VERSION ""

NS_ :

BS_:

BU_: HCM IPMA_ADAS PSCM ABS_ESC PCM ECM_HEV VDM CMR_DSMC SOBDMC_HPCM GWM _delete AWD_DLCM GENERIC TSTR

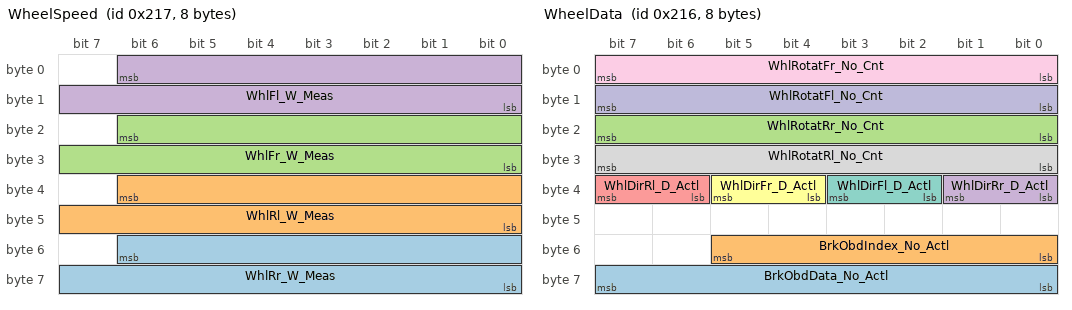
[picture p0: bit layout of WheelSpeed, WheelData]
BO_ 535 WheelSpeed: 8 ABS_ESC
 SG_ WhlRr_W_Meas : 54|15@0+ (0.01,0) [0|327.65] "rad/s"  VDM,SOBDMC_HPCM,IPMA_ADAS,GWM,ECM_HEV,PCM,PSCM,AWD_DLCM
 SG_ WhlRl_W_Meas : 38|15@0+ (0.01,0) [0|327.65] "rad/s"  VDM,SOBDMC_HPCM,IPMA_ADAS,GWM,ECM_HEV,PCM,PSCM,AWD_DLCM
 SG_ WhlFr_W_Meas : 22|15@0+ (0.01,0) [0|327.65] "rad/s"  VDM,SOBDMC_HPCM,IPMA_ADAS,GWM,ECM_HEV,PCM,PSCM,AWD_DLCM
 SG_ WhlFl_W_Meas : 6|15@0+ (0.01,0) [0|327.65] "rad/s"  VDM,SOBDMC_HPCM,IPMA_ADAS,GWM,ECM_HEV,PCM,PSCM,AWD_DLCM

BO_ 534 WheelData: 8 ABS_ESC
 SG_ BrkObdData_No_Actl : 63|8@0+ (1,0) [0|255] "unitless"  SOBDMC_HPCM,GWM
 SG_ BrkObdIndex_No_Actl : 53|6@0+ (1,0) [0|63] "unitless"  SOBDMC_HPCM,GWM
 SG_ WhlRotatRr_No_Cnt : 23|8@0+ (1,0) [0|255] "Unitless"  IPMA_ADAS,GWM
 SG_ WhlDirRr_D_Actl : 33|2@0+ (1,0) [0|3] "SED"  IPMA_ADAS,GWM,PCM,PSCM,ECM_HEV
 SG_ WhlDirRl_D_Actl : 39|2@0+ (1,0) [0|3] "SED"  IPMA_ADAS,GWM,PSCM,PCM,ECM_HEV
 SG_ WhlDirFr_D_Actl : 37|2@0+ (1,0) [0|3] "SED"  IPMA_ADAS,GWM,PCM,PSCM,ECM_HEV
 SG_ WhlDirFl_D_Actl : 35|2@0+ (1,0) [0|3] "SED"  IPMA_ADAS,GWM,PCM,PSCM,ECM_HEV
 SG_ WhlRotatRl_No_Cnt : 31|8@0+ (1,0) [0|255] "Unitless"  IPMA_ADAS,GWM
 SG_ WhlRotatFr_No_Cnt : 7|8@0+ (1,0) [0|255] "Unitless"  IPMA_ADAS,GWM
 SG_ WhlRotatFl_No_Cnt : 15|8@0+ (1,0) [0|255] "Unitless"  IPMA_ADAS,GWM

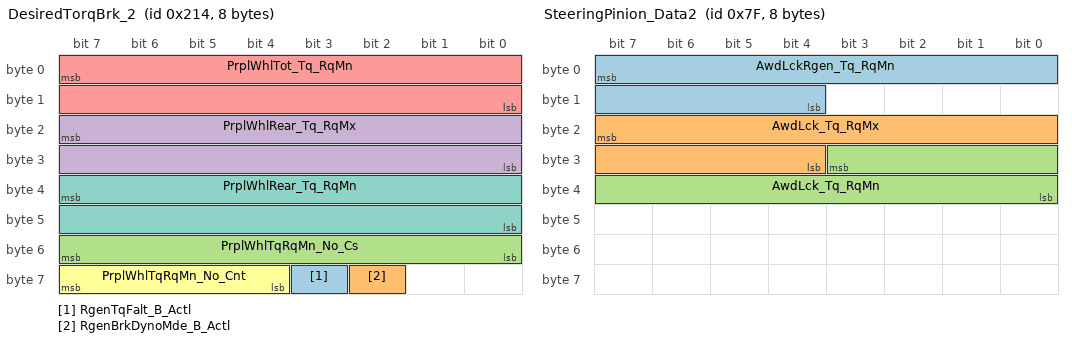
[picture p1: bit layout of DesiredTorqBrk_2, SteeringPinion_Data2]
BO_ 532 DesiredTorqBrk_2: 8 ABS_ESC
 SG_ RgenTqFalt_B_Actl : 59|1@0+ (1,0) [0|1] "SED"  SOBDMC_HPCM,GWM
 SG_ RgenBrkDynoMde_B_Actl : 58|1@0+ (1,0) [0|1] "SED"  ECM_HEV,SOBDMC_HPCM,GWM
 SG_ PrplWhlTqRqMn_No_Cs : 55|8@0+ (1,0) [0|255] "Unitless"  SOBDMC_HPCM,GWM,ECM_HEV,PCM
 SG_ PrplWhlRear_Tq_RqMx : 23|16@0+ (4,-131072) [-131072|131068] "Nm"  GWM
 SG_ PrplWhlTot_Tq_RqMn : 7|16@0+ (4,-131072) [-131072|131068] "Nm"  SOBDMC_HPCM,GWM,ECM_HEV,PCM
 SG_ PrplWhlTqRqMn_No_Cnt : 63|4@0+ (1,0) [0|15] "Unitless"  SOBDMC_HPCM,GWM,ECM_HEV,PCM
 SG_ PrplWhlRear_Tq_RqMn : 39|16@0+ (4,-131072) [-131072|131068] "Nm"  SOBDMC_HPCM,GWM

BO_ 531 DesiredTorqBrk: 8 ABS_ESC
 SG_ PrkBrkMsgTxt_D_Rq : 36|4@0+ (1,0) [0|15] "SED"  GWM
 SG_ VehStop_D_Stat : 28|2@0+ (1,0) [0|3] "SED"  IPMA_ADAS,GWM
 SG_ TracCtlPtActv_B_Actl : 31|1@0+ (1,0) [0|1] "SED"  SOBDMC_HPCM,IPMA_ADAS,ECM_HEV,PCM,VDM,AWD_DLCM,GWM
 SG_ VehicleStationary : 39|1@0+ (1,0) [0|1] "SED"  GWM,AWD_DLCM
 SG_ AbsActv_B_Actl : 45|1@0+ (1,0) [0|1] "SED"  SOBDMC_HPCM,IPMA_ADAS,ECM_HEV,PCM,PSCM,GWM,VDM,AWD_DLCM
 SG_ StabCtlBrkActv_B_Actl : 23|1@0+ (1,0) [0|1] "SED"  SOBDMC_HPCM,IPMA_ADAS,ECM_HEV,PCM,PSCM,VDM,GWM,AWD_DLCM
 SG_ CmbbBrkPrchg_B_Actl : 59|1@0+ (1,0) [0|1] "SED"  IPMA_ADAS,GWM
 SG_ CmbbBrkDecel_B_Actl : 58|1@0+ (1,0) [0|1] "SED"  IPMA_ADAS,GWM
 SG_ CmbbBaSensInc_B_Actl : 57|1@0+ (1,0) [0|1] "SED"  IPMA_ADAS,GWM
 SG_ AccBrkWarm_B_Actl : 63|1@0+ (1,0) [0|1] "SED"  IPMA_ADAS,GWM
 SG_ AccBrkTotTqMn_B_Actl : 62|1@0+ (1,0) [0|1] "SED"  IPMA_ADAS,GWM
 SG_ AccBrkPrchgActv_B_Actl : 61|1@0+ (1,0) [0|1] "SED"  IPMA_ADAS,GWM
 SG_ AccBrkDis_B_Actl : 44|1@0+ (1,0) [0|1] "SED"  IPMA_ADAS,GWM
 SG_ AccBrkDeny_B_Actl : 42|1@0+ (1,0) [0|1] "SED"  IPMA_ADAS,ECM_HEV,PCM,GWM
 SG_ AccBrkActv_B_Actl : 43|1@0+ (1,0) [0|1] "SED"  IPMA_ADAS,GWM
 SG_ PrplDrgCtlActv_B_Actl : 46|1@0+ (1,0) [0|1] "SED"  SOBDMC_HPCM,ECM_HEV,PCM,GWM
 SG_ PrplWhlTot_Tq_RqMx : 7|16@0+ (4,-131072) [-131072|131068] "Nm"  SOBDMC_HPCM,ECM_HEV,PCM,GWM,AWD_DLCM
 SG_ CmbbBrkDis_B_Actl : 56|1@0+ (1,0) [0|1] "SED"  IPMA_ADAS,PSCM,GWM
 SG_ CmbbDeny_B_ActlBrk : 60|1@0+ (1,0) [0|1] "SED"  SOBDMC_HPCM,IPMA_ADAS,PSCM,ECM_HEV,GENERIC,PCM,GWM
 SG_ CcDis_B_Cmd : 47|1@0+ (1,0) [0|1] "SED"  ECM_HEV,PCM,GWM
 SG_ VehLongOvrGnd_A_Est : 41|10@0+ (0.035,-17.9) [-17.9|17.835] "m/s^2"  SOBDMC_HPCM,IPMA_ADAS,GWM,VDM
 SG_ AccStopActv_B_ActlBrk : 22|1@0+ (1,0) [0|1] "SED"  IPMA_ADAS,ECM_HEV,PCM,GWM
 SG_ AccDis_B_ActlEpb : 32|1@0+ (1,0) [0|1] "SED"  IPMA_ADAS,GWM
 SG_ PrkBrkStatus : 26|3@0+ (1,0) [0|7] "SED"  SOBDMC_HPCM,IPMA_ADAS,ECM_HEV,PCM,GWM,AWD_DLCM
 SG_ PrkBrkYwLamp_D_Rq : 38|2@0+ (1,0) [0|3] "SED"  GWM
 SG_ PrkBrkRedLamp_D_Rq : 30|2@0+ (1,0) [0|3] "SED"  GWM

BO_ 127 SteeringPinion_Data2: 8 ABS_ESC
 SG_ AwdLckRgen_Tq_RqMn : 7|12@0+ (1,-4095) [-4095|0] "Nm"  SOBDMC_HPCM,GWM
 SG_ AwdLck_Tq_RqMx : 23|12@0+ (1,0) [0|4095] "Nm"  AWD_DLCM,ECM_HEV,PCM,SOBDMC_HPCM,GWM
 SG_ AwdLck_Tq_RqMn : 27|12@0+ (1,0) [0|4095] "Nm"  AWD_DLCM,ECM_HEV,PCM,SOBDMC_HPCM,GWM

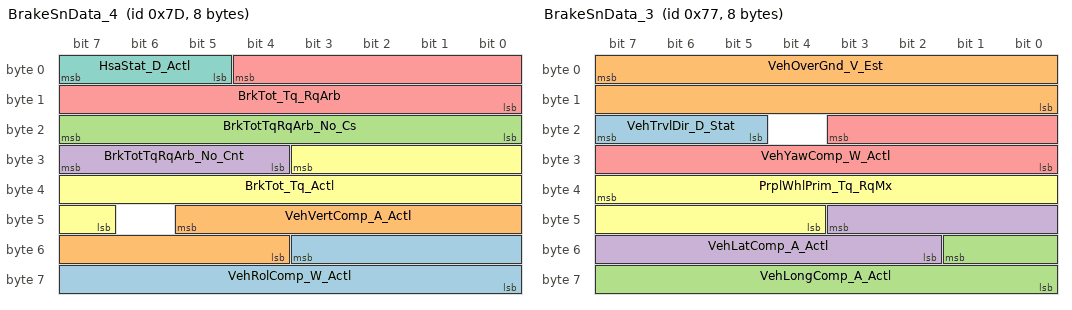
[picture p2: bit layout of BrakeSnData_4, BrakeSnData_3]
BO_ 125 BrakeSnData_4: 8 ABS_ESC
 SG_ VehRolComp_W_Actl : 51|12@0+ (0.03663,-75) [-75|74.92659] "degrees/sec"  GWM,VDM
 SG_ VehVertComp_A_Actl : 45|10@0+ (0.035,-17.9) [-17.9|17.835] "m/s^2"  GWM,VDM
 SG_ BrkTotTqRqArb_No_Cs : 23|8@0+ (1,0) [0|255] "Unitless"  SOBDMC_HPCM,ECM_HEV,PCM,GWM
 SG_ BrkTotTqRqArb_No_Cnt : 31|4@0+ (1,0) [0|15] "Unitless"  SOBDMC_HPCM,ECM_HEV,PCM,GWM
 SG_ BrkTot_Tq_RqArb : 4|13@0+ (4,0) [0|32756] "Nm"  SOBDMC_HPCM,HCM,IPMA_ADAS,ECM_HEV,PCM,VDM,GWM
 SG_ BrkTot_Tq_Actl : 27|13@0+ (4,0) [0|32756] "Nm"  SOBDMC_HPCM,ECM_HEV,PCM,PSCM,GWM
 SG_ HsaStat_D_Actl : 7|3@0+ (1,0) [0|7] "SED"  ECM_HEV,PCM,GWM

BO_ 119 BrakeSnData_3: 8 ABS_ESC
 SG_ VehTrvlDir_D_Stat : 23|3@0+ (1,0) [0|7] "SED"  GWM
 SG_ VehOverGnd_V_Est : 7|16@0+ (0.01,0) [0|655.33] "kph"  SOBDMC_HPCM,IPMA_ADAS,PSCM,GWM,VDM,AWD_DLCM
 SG_ VehLongComp_A_Actl : 49|10@0+ (0.035,-17.9) [-17.9|17.835] "m/s^2"  SOBDMC_HPCM,ECM_HEV,PCM,VDM,HCM,GWM,AWD_DLCM
 SG_ VehLatComp_A_Actl : 43|10@0+ (0.035,-17.9) [-17.9|17.835] "m/s^2"  SOBDMC_HPCM,ECM_HEV,PCM,PSCM,VDM,HCM,GWM,AWD_DLCM
 SG_ VehYawComp_W_Actl : 19|12@0+ (0.03663,-75) [-75|74.92659] "deg/s"  SOBDMC_HPCM,IPMA_ADAS,ECM_HEV,PCM,PSCM,VDM,GWM,AWD_DLCM
 SG_ PrplWhlPrim_Tq_RqMx : 39|12@0+ (8,0) [0|32760] "Nm"  SOBDMC_HPCM,GWM

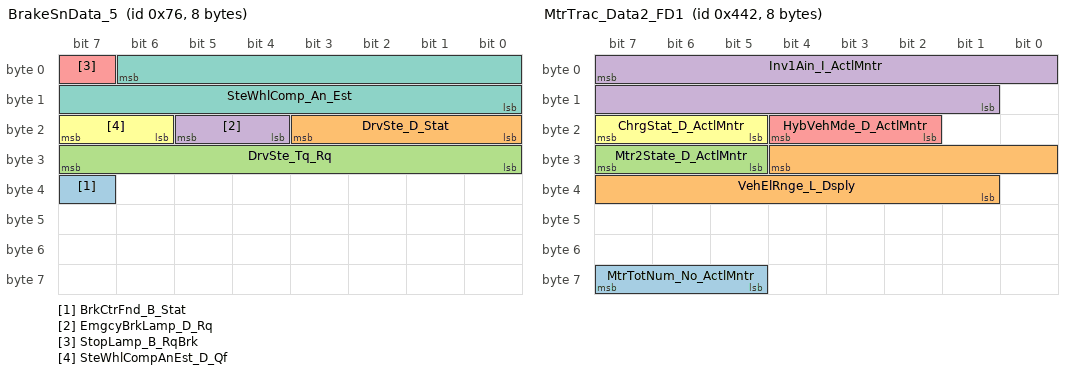
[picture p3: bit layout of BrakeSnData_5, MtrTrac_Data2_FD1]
BO_ 118 BrakeSnData_5: 8 ABS_ESC
 SG_ BrkCtrFnd_B_Stat : 39|1@0+ (1,0) [0|1] "SED"  GWM
 SG_ DrvSte_D_Stat : 19|4@0+ (1,0) [0|15] "SED"  GWM
 SG_ DrvSte_Tq_Rq : 31|8@0+ (0.0625,-8) [-8|7.8125] "Nm"  GWM
 SG_ EmgcyBrkLamp_D_Rq : 21|2@0+ (1,0) [0|3] "SED"  GWM
 SG_ StopLamp_B_RqBrk : 7|1@0+ (1,0) [0|1] "SED"  GWM
 SG_ SteWhlCompAnEst_D_Qf : 23|2@0+ (1,0) [0|3] "SED"  GWM
 SG_ SteWhlComp_An_Est : 6|15@0+ (0.1,-1600) [-1600|1676.7] "deg"  GWM

BO_ 73 Global_PATS_SubTarget: 8 ABS_ESC
 SG_ immoSubTarget1Data_T1 : 15|40@0+ (1,0) [0|1099511627775] "Encrypted"  ECM_HEV,SOBDMC_HPCM,GWM,PCM
 SG_ immoSubTarget1Cmd_T1 : 7|3@0+ (1,0) [0|7] "SED"  SOBDMC_HPCM,GWM,PCM

BO_ 1034 GGCC_Config_Mgmt_ID_1_FD1: 8 GWM
 SG_ VehicleGGCCData : 7|64@0+ (1,0) [0|1.84467E+019] "mixed"  SOBDMC_HPCM,HCM,VDM,IPMA_ADAS,ABS_ESC,ECM_HEV,PCM,PSCM,CMR_DSMC,AWD_DLCM

BO_ 561 TransGearData_2: 8 PCM
 SG_ TrnMsgTxt2_D_Rq : 39|3@0+ (1,0) [0|7] "SED"  GWM
 SG_ TrnMsgTxt_D_Rq : 23|4@0+ (1,0) [0|15] "SED"  GWM

BO_ 1090 MtrTrac_Data2_FD1: 8 SOBDMC_HPCM
 SG_ MtrTotNum_No_ActlMntr : 63|3@0+ (1,0) [0|7] "unitless"  GWM
 SG_ VehElRnge_L_Dsply : 28|12@0+ (0.1,0) [0|409.3] "kilometer"  GWM
 SG_ Mtr2State_D_ActlMntr : 31|3@0+ (1,0) [0|7] "SED"  GWM
 SG_ Inv1Ain_I_ActlMntr : 7|15@0+ (0.1,-1000) [-1000|2276.5] "ampere"  GWM
 SG_ HybVehMde_D_ActlMntr : 20|3@0+ (1,0) [0|7] "SED"  GWM
 SG_ ChrgStat_D_ActlMntr : 23|3@0+ (1,0) [0|7] "SED"  GWM

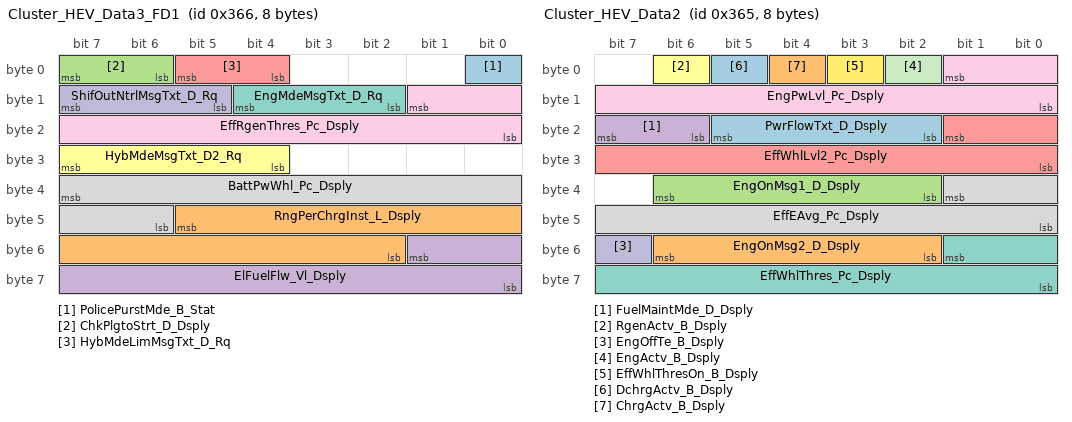
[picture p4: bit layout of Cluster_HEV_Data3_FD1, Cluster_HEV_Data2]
BO_ 870 Cluster_HEV_Data3_FD1: 8 SOBDMC_HPCM
 SG_ PolicePurstMde_B_Stat : 0|1@0+ (1,0) [0|1] "SED"  GWM
 SG_ RngPerChrgInst_L_Dsply : 45|12@0+ (0.1,0) [0|409.3] "km"  GWM
 SG_ ChkPlgtoStrt_D_Dsply : 7|2@0+ (1,0) [0|3] "SED"  GWM
 SG_ ElFuelFlw_Vl_Dsply : 49|10@0+ (25,0) [0|25575] "micro-litre"  GWM
 SG_ HybMdeLimMsgTxt_D_Rq : 5|2@0+ (1,0) [0|3] "SED"  GWM
 SG_ HybMdeMsgTxt_D2_Rq : 31|4@0+ (1,0) [0|15] "SED"  GWM
 SG_ EngMdeMsgTxt_D_Rq : 12|3@0+ (1,0) [0|7] "SED"  GWM
 SG_ BattPwWhl_Pc_Dsply : 39|10@0+ (0.1,0) [0|102.3] "percent"  GWM
 SG_ EffRgenThres_Pc_Dsply : 9|10@0+ (0.1,-102.3) [-102.3|0] "percent"  GWM
 SG_ ShifOutNtrlMsgTxt_D_Rq : 15|3@0+ (1,0) [0|7] "SED"  GWM

BO_ 869 Cluster_HEV_Data2: 8 SOBDMC_HPCM
 SG_ PwrFlowTxt_D_Dsply : 21|4@0+ (1,0) [0|15] "SED"  GWM
 SG_ EngOnMsg2_D_Dsply : 54|5@0+ (1,0) [0|31] "SED"  GWM
 SG_ EngOnMsg1_D_Dsply : 38|5@0+ (1,0) [0|31] "SED"  GWM
 SG_ FuelMaintMde_D_Dsply : 23|2@0+ (1,0) [0|3] "SED"  GWM
 SG_ EffWhlLvl2_Pc_Dsply : 17|10@0+ (0.2,-102.2) [-102.2|102.4] "percent"  GWM
 SG_ RgenActv_B_Dsply : 6|1@0+ (1,0) [0|1] "SED"  GWM
 SG_ EffWhlThres_Pc_Dsply : 49|10@0+ (0.1,0) [0|102.3] "percent"  GWM
 SG_ EffEAvg_Pc_Dsply : 33|10@0+ (0.1,0) [0|102.3] "percent"  GWM
 SG_ EngPwLvl_Pc_Dsply : 1|10@0+ (0.1,0) [0|102.3] "percent"  GWM
 SG_ EngOffTe_B_Dsply : 55|1@0+ (1,0) [0|1] "SED"  GWM
 SG_ EngActv_B_Dsply : 2|1@0+ (1,0) [0|1] "SED"  GWM
 SG_ EffWhlThresOn_B_Dsply : 3|1@0+ (1,0) [0|1] "SED"  GWM
 SG_ DchrgActv_B_Dsply : 5|1@0+ (1,0) [0|1] "SED"  GWM
 SG_ ChrgActv_B_Dsply : 4|1@0+ (1,0) [0|1] "SED"  GWM

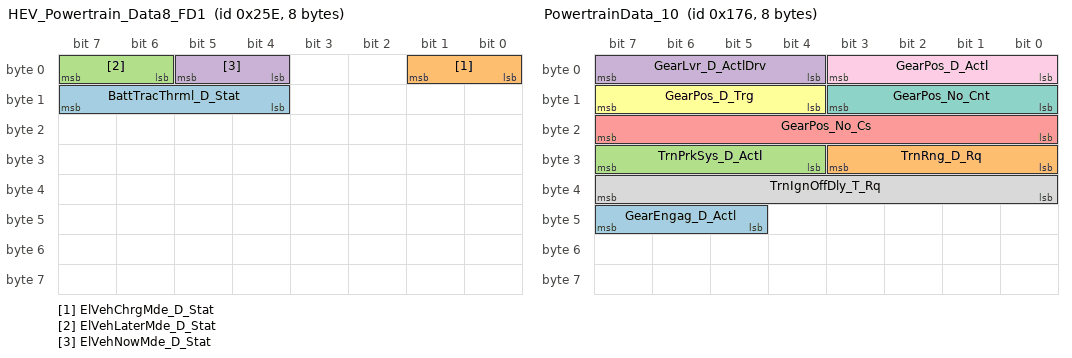
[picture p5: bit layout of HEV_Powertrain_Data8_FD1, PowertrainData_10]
BO_ 606 HEV_Powertrain_Data8_FD1: 8 SOBDMC_HPCM
 SG_ BattTracThrml_D_Stat : 15|4@0+ (1,0) [0|15] "SED"  GWM
 SG_ ElVehChrgMde_D_Stat : 1|2@0+ (1,0) [0|3] "SED"  GWM
 SG_ ElVehLaterMde_D_Stat : 7|2@0+ (1,0) [0|3] "SED"  ABS_ESC,GWM
 SG_ ElVehNowMde_D_Stat : 5|2@0+ (1,0) [0|3] "SED"  ABS_ESC,GWM

BO_ 374 PowertrainData_10: 8 PCM
 SG_ GearEngag_D_Actl : 47|3@0+ (1,0) [0|7] "SED"  ABS_ESC,GWM
 SG_ TrnRng_D_Rq : 27|4@0+ (1,0) [0|15] "SED"  IPMA_ADAS,ABS_ESC,ECM_HEV,GWM,AWD_DLCM
 SG_ TrnPrkSys_D_Actl : 31|4@0+ (1,0) [0|15] "SED"  IPMA_ADAS,ABS_ESC,ECM_HEV,GWM,AWD_DLCM
 SG_ GearLvr_D_ActlDrv : 7|4@0+ (1,0) [0|15] "SED"  IPMA_ADAS,ABS_ESC,ECM_HEV,GWM
 SG_ GearPos_No_Cs : 23|8@0+ (1,0) [0|255] "unitless"  IPMA_ADAS,ABS_ESC,ECM_HEV,GWM
 SG_ GearPos_D_Trg : 15|4@0+ (1,0) [0|15] "SED"  HCM,IPMA_ADAS,ABS_ESC,ECM_HEV,GWM,AWD_DLCM
 SG_ GearPos_No_Cnt : 11|4@0+ (1,0) [0|15] "unitless"  IPMA_ADAS,ABS_ESC,ECM_HEV,GWM
 SG_ TrnIgnOffDly_T_Rq : 39|8@0+ (4,0) [0|1020] "ms"  GWM
 SG_ GearPos_D_Actl : 3|4@0+ (1,0) [0|15] "SED"  ABS_ESC,IPMA_ADAS,ECM_HEV,GWM

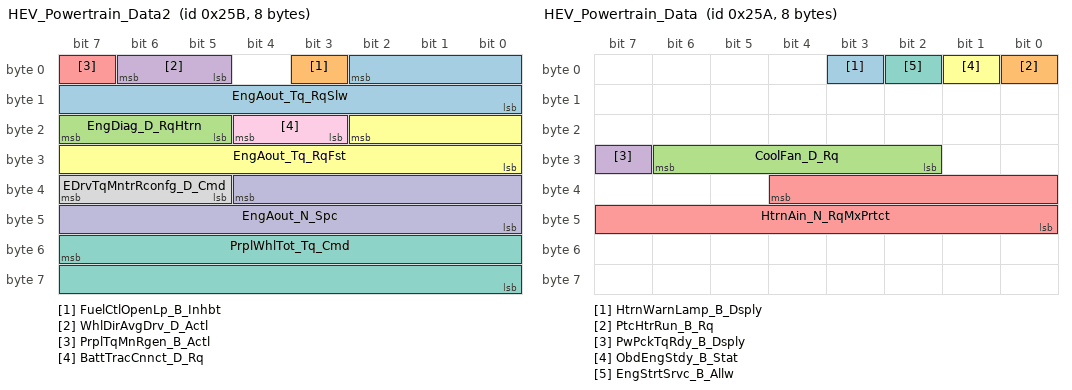
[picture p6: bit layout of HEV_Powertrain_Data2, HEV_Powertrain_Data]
BO_ 603 HEV_Powertrain_Data2: 8 SOBDMC_HPCM
 SG_ EngAout_Tq_RqSlw : 2|11@0+ (1,-500) [-500|1547] "Nm"  ECM_HEV,GWM
 SG_ FuelCtlOpenLp_B_Inhbt : 3|1@0+ (1,0) [0|1] "SED"  ECM_HEV,GWM
 SG_ EngDiag_D_RqHtrn : 23|3@0+ (1,0) [0|7] "SED"  ECM_HEV,GWM
 SG_ WhlDirAvgDrv_D_Actl : 6|2@0+ (1,0) [0|3] "SED"  IPMA_ADAS,ABS_ESC,ECM_HEV,GWM
 SG_ PrplTqMnRgen_B_Actl : 7|1@0+ (1,0) [0|1] "SED"  ABS_ESC,GWM
 SG_ EngAout_Tq_RqFst : 18|11@0+ (1,-500) [-500|1547] "Nm"  ECM_HEV,GWM
 SG_ PrplWhlTot_Tq_Cmd : 55|16@0+ (4,-131072) [-131072|131068] "Nm"  ECM_HEV,GWM
 SG_ EDrvTqMntrRconfg_D_Cmd : 39|3@0+ (1,0) [0|7] "SED"  ECM_HEV,GWM
 SG_ BattTracCnnct_D_Rq : 20|2@0+ (1,0) [0|3] "SED"  SOBDMC_HPCM,ECM_HEV,GWM
 SG_ EngAout_N_Spc : 36|13@0+ (2,0) [0|16382] "rpm"  ECM_HEV,GWM

BO_ 602 HEV_Powertrain_Data: 8 SOBDMC_HPCM
 SG_ HtrnWarnLamp_B_Dsply : 3|1@0+ (1,0) [0|1] "SED"  GWM
 SG_ PtcHtrRun_B_Rq : 0|1@0+ (1,0) [0|1] "SED"  GWM
 SG_ CoolFan_D_Rq : 30|5@0+ (1,0) [0|31] "unitless"  GWM
 SG_ PwPckTqRdy_B_Dsply : 31|1@0+ (1,0) [0|1] "SED"  GWM
 SG_ HtrnAin_N_RqMxPrtct : 36|13@0+ (2,0) [0|16382] "RPM"  GWM
 SG_ ObdEngStdy_B_Stat : 1|1@0+ (1,0) [0|1] "SED"  GWM
 SG_ EngStrtSrvc_B_Allw : 2|1@0+ (1,0) [0|1] "SED"  GWM

BO_ 1152 HEV_Powertrain_Data6: 8 ECM_HEV
 SG_ VehElEff_No_Avg : 15|7@0+ (10,-100) [-100|1150] "watt*hr/km" Vector__XXX
 SG_ PwCabinEnblScnd_B_Rq : 28|1@0+ (1,0) [0|1] "SED"  GWM
 SG_ PwCabinEnbl_B_Rq : 29|1@0+ (1,0) [0|1] "SED"  GWM
 SG_ PwTrnkFrntEnblScnd_B_Rq : 30|1@0+ (1,0) [0|1] "SED"  GWM
 SG_ PwTrnkFrntEnbl_B_Rq : 31|1@0+ (1,0) [0|1] "SED"  GWM
 SG_ PwOutlet8EnblScnd_B_Rq : 16|1@0+ (1,0) [0|1] "SED"  GWM
 SG_ PwOutlet8Enbl_B_Rq : 17|1@0+ (1,0) [0|1] "SED"  GWM
 SG_ PwOutlet7EnblScnd_B_Rq : 18|1@0+ (1,0) [0|1] "SED"  GWM
 SG_ PwOutlet7Enbl_B_Rq : 19|1@0+ (1,0) [0|1] "SED"  GWM
 SG_ PwOutlet6EnblScnd_B_Rq : 20|1@0+ (1,0) [0|1] "SED"  GWM
 SG_ PwOutlet6Enbl_B_Rq : 21|1@0+ (1,0) [0|1] "SED"  GWM
 SG_ HybPwULoLamp_B_Rq : 22|1@0+ (1,0) [0|1] "SED"  GWM
 SG_ GrdAsstActv_B_Stat : 8|1@0+ (1,0) [0|1] "SED"  SOBDMC_HPCM,GWM
 SG_ EngTeHi_B_Actl : 5|1@0+ (1,0) [0|1] "SED"  SOBDMC_HPCM,GWM
 SG_ DcdcOn_B_Rq : 6|1@0+ (1,0) [0|1] "SED"  GWM
 SG_ ULoBattSpprtSustn_B_Rq : 7|1@0+ (1,0) [0|1] "SED"  SOBDMC_HPCM,GWM
 SG_ BattTracDiagClr_B_Stat : 2|1@0+ (1,0) [0|1] "SED"  GWM

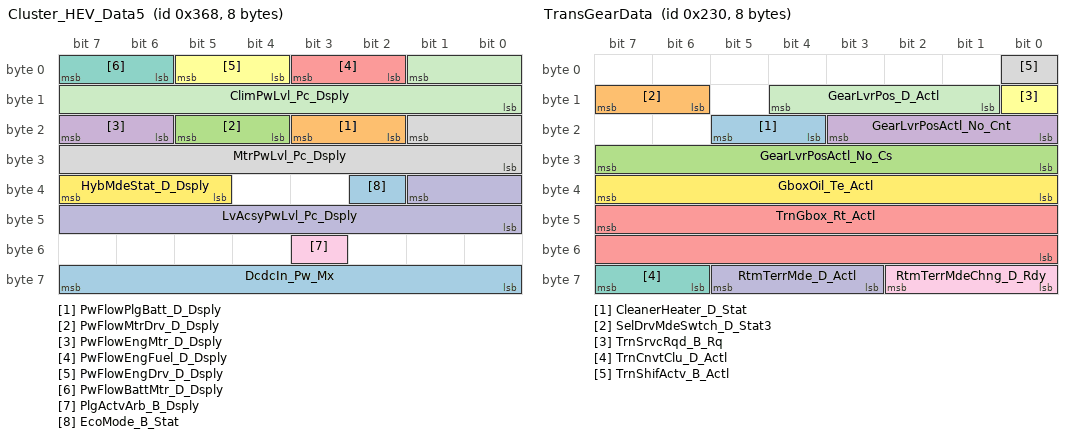
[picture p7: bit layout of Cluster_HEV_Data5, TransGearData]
BO_ 872 Cluster_HEV_Data5: 8 SOBDMC_HPCM
 SG_ DcdcIn_Pw_Mx : 63|8@0+ (20,1000) [1000|6100] "watts"  GWM,GENERIC
 SG_ PwFlowPlgBatt_D_Dsply : 19|2@0+ (1,0) [0|3] "SED"  GWM
 SG_ PwFlowMtrDrv_D_Dsply : 21|2@0+ (1,0) [0|3] "SED"  GWM
 SG_ PwFlowEngMtr_D_Dsply : 23|2@0+ (1,0) [0|3] "SED"  GWM
 SG_ PwFlowEngFuel_D_Dsply : 3|2@0+ (1,0) [0|3] "SED"  GWM
 SG_ PwFlowEngDrv_D_Dsply : 5|2@0+ (1,0) [0|3] "SED"  GWM
 SG_ PwFlowBattMtr_D_Dsply : 7|2@0+ (1,0) [0|3] "SED"  GWM
 SG_ MtrPwLvl_Pc_Dsply : 17|10@0+ (0.2,-102.2) [-102.2|102.4] "percent"  GWM
 SG_ PlgActvArb_B_Dsply : 51|1@0+ (1,0) [0|1] "SED"  GWM
 SG_ LvAcsyPwLvl_Pc_Dsply : 33|10@0+ (0.1,0) [0|102.3] "percent"  GWM
 SG_ ClimPwLvl_Pc_Dsply : 1|10@0+ (0.1,0) [0|102.3] "percent"  GWM
 SG_ HybMdeStat_D_Dsply : 39|3@0+ (1,0) [0|7] "SED"  GWM,ECM_HEV
 SG_ EcoMode_B_Stat : 34|1@0+ (1,0) [0|1] "SED"  GWM

BO_ 560 TransGearData: 8 ECM_HEV
 SG_ CleanerHeater_D_Stat : 21|2@0+ (1,0) [0|3] "SED"  GWM
 SG_ SelDrvMdeSwtch_D_Stat3 : 15|2@0+ (1,0) [0|3] "SED"  GWM
 SG_ GearLvrPosActl_No_Cs : 31|8@0+ (1,0) [0|255] "Unitless"  GWM
 SG_ GearLvrPosActl_No_Cnt : 19|4@0+ (1,0) [0|15] "Unitless"  GWM
 SG_ TrnGbox_Rt_Actl : 47|16@0+ (0.001,0) [0|65.533] "Unitless"  GWM,ECM_HEV
 SG_ TrnSrvcRqd_B_Rq : 8|1@0+ (1,0) [0|1] "SED"  GWM
 SG_ TrnCnvtClu_D_Actl : 63|2@0+ (1,0) [0|3] "SED"  GWM,AWD_DLCM
 SG_ TrnShifActv_B_Actl : 0|1@0+ (1,0) [0|1] "SED"  ABS_ESC,GWM,ECM_HEV
 SG_ RtmTerrMdeChng_D_Rdy : 58|3@0+ (1,0) [0|7] "SED"  GWM
 SG_ RtmTerrMde_D_Actl : 61|3@0+ (1,0) [0|7] "SED"  GWM
 SG_ GearLvrPos_D_Actl : 12|4@0+ (1,0) [0|15] "SED"  HCM,VDM,IPMA_ADAS,GWM,ABS_ESC,ECM_HEV,AWD_DLCM
 SG_ GboxOil_Te_Actl : 39|8@0+ (1,-60) [-60|193] "degC"  AWD_DLCM,GWM,ECM_HEV

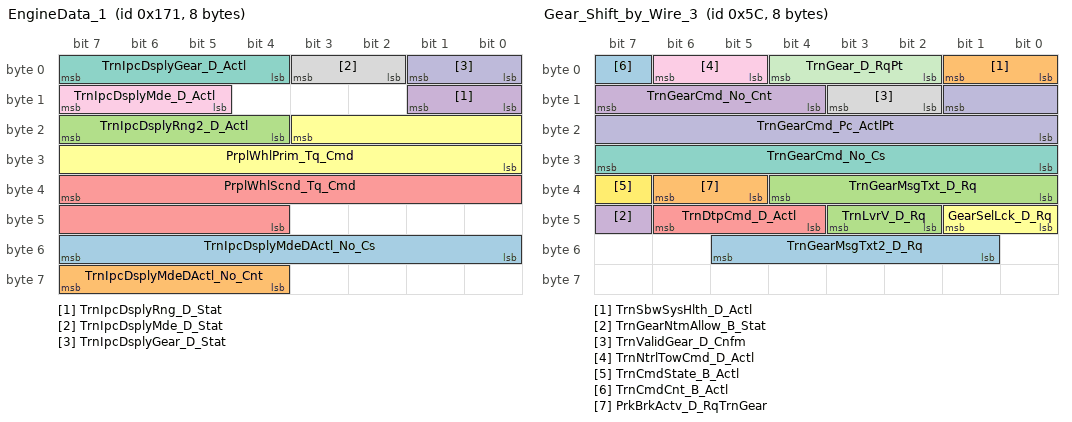
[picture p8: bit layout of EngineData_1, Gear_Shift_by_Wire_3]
BO_ 369 EngineData_1: 8 SOBDMC_HPCM
 SG_ TrnIpcDsplyMdeDActl_No_Cs : 55|8@0+ (1,0) [0|255] "Unitless"  GWM
 SG_ TrnIpcDsplyMdeDActl_No_Cnt : 63|4@0+ (1,0) [0|15] "Unitless"  GWM
 SG_ TrnIpcDsplyRng2_D_Actl : 23|4@0+ (1,0) [0|15] "SED" Vector__XXX
 SG_ TrnIpcDsplyRng_D_Stat : 9|2@0+ (1,0) [0|3] "SED" Vector__XXX
 SG_ PrplWhlScnd_Tq_Cmd : 39|12@0+ (8,-16380) [-16380|16380] "Nm"  ABS_ESC
 SG_ PrplWhlPrim_Tq_Cmd : 19|12@0+ (8,-16380) [-16380|16380] "Nm"  ABS_ESC
 SG_ TrnIpcDsplyGear_D_Actl : 7|4@0+ (1,0) [0|15] "SED"  GWM
 SG_ TrnIpcDsplyMde_D_Stat : 3|2@0+ (1,0) [0|3] "SED"  GWM
 SG_ TrnIpcDsplyMde_D_Actl : 15|3@0+ (1,0) [0|7] "SED"  GWM
 SG_ TrnIpcDsplyGear_D_Stat : 1|2@0+ (1,0) [0|3] "SED"  GWM

BO_ 92 Gear_Shift_by_Wire_3: 8 PCM
 SG_ TrnGearMsgTxt2_D_Rq : 53|5@0+ (1,0) [0|31] "SED"  GWM
 SG_ TrnSbwSysHlth_D_Actl : 1|2@0+ (1,0) [0|3] "SED"  GWM
 SG_ TrnLvrV_D_Rq : 43|2@0+ (1,0) [0|3] "SED"  GWM
 SG_ TrnGearNtmAllow_B_Stat : 47|1@0+ (1,0) [0|1] "SED"  GWM
 SG_ TrnDtpCmd_D_Actl : 46|3@0+ (1,0) [0|7] "SED"  GWM
 SG_ GearSelLck_D_Rq : 41|2@0+ (1,0) [0|3] "SED"  GWM
 SG_ TrnGearCmd_No_Cs : 31|8@0+ (1,0) [0|255] "Unitless"  GWM
 SG_ TrnValidGear_D_Cnfm : 11|2@0+ (1,0) [0|3] "SED"  GWM
 SG_ TrnNtrlTowCmd_D_Actl : 6|2@0+ (1,0) [0|3] "SED"  IPMA_ADAS,GWM,ABS_ESC
 SG_ TrnGearCmd_Pc_ActlPt : 9|10@0+ (0.1,0) [0|102.2] "percent duty cycle"  GWM
 SG_ TrnGear_D_RqPt : 4|3@0+ (1,0) [0|7] "SED"  GWM
 SG_ TrnCmdState_B_Actl : 39|1@0+ (1,0) [0|1] "SED"  GWM
 SG_ TrnCmdCnt_B_Actl : 7|1@0+ (1,0) [0|1] "unitless"  GWM
 SG_ PrkBrkActv_D_RqTrnGear : 38|2@0+ (1,0) [0|3] "SED"  GWM,ABS_ESC
 SG_ TrnGearMsgTxt_D_Rq : 36|5@0+ (1,0) [0|31] "SED"  GWM
 SG_ TrnGearCmd_No_Cnt : 15|4@0+ (1,0) [0|15] "Unitless"  GWM

BO_ 2030 TesterPhysicalResSOBDMCFD1: 64 SOBDMC_HPCM
 SG_ TesterPhysicalResSOBDMC : 7|64@0+ (1,0) [0|1.84467E+019] "unitless"  TSTR

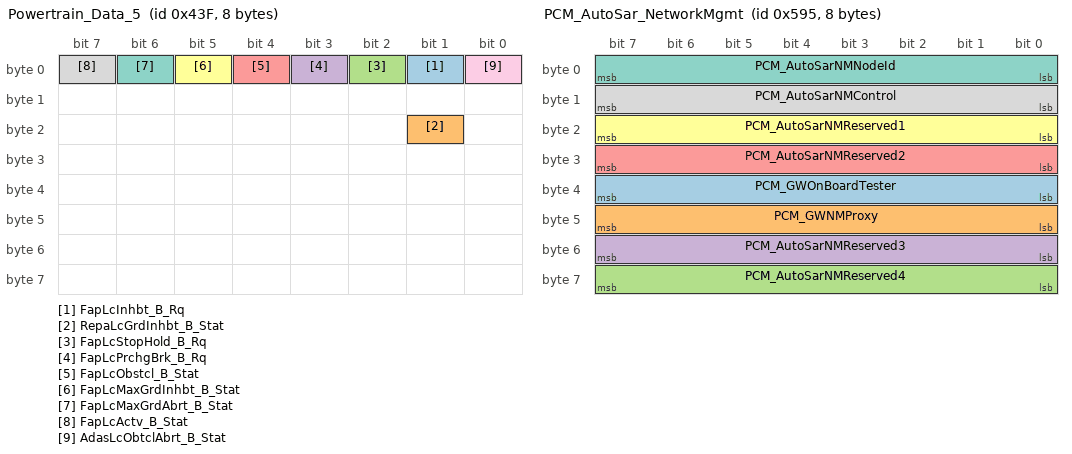
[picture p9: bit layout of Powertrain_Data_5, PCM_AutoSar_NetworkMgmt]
BO_ 1087 Powertrain_Data_5: 8 ECM_HEV
 SG_ FapLcInhbt_B_Rq : 1|1@0+ (1,0) [0|1] "SED"  GWM,IPMA_ADAS
 SG_ RepaLcGrdInhbt_B_Stat : 17|1@0+ (1,0) [0|1] "SED"  IPMA_ADAS,GWM
 SG_ FapLcStopHold_B_Rq : 2|1@0+ (1,0) [0|1] "SED"  ABS_ESC
 SG_ FapLcPrchgBrk_B_Rq : 3|1@0+ (1,0) [0|1] "SED"  ABS_ESC
 SG_ FapLcObstcl_B_Stat : 4|1@0+ (1,0) [0|1] "SED"  IPMA_ADAS
 SG_ FapLcMaxGrdInhbt_B_Stat : 5|1@0+ (1,0) [0|1] "SED"  IPMA_ADAS
 SG_ FapLcMaxGrdAbrt_B_Stat : 6|1@0+ (1,0) [0|1] "SED"  IPMA_ADAS
 SG_ FapLcActv_B_Stat : 7|1@0+ (1,0) [0|1] "SED"  IPMA_ADAS
 SG_ AdasLcObtclAbrt_B_Stat : 0|1@0+ (1,0) [0|1] "SED"  GWM,IPMA_ADAS

BO_ 1896 TesterPhysicalResABS: 64 ABS_ESC
 SG_ TesterPhysicalResABS : 7|64@0+ (1,0) [0|1.84467E+019] "unitless"  TSTR

BO_ 1888 TesterPhysicalReqABS: 64 TSTR
 SG_ TesterPhysicalReqABS : 7|64@0+ (1,0) [0|1.84467E+019] "unitless"  ABS_ESC

BO_ 1848 TesterPhysicalResPSCM: 64 PSCM
 SG_ TesterPhysicalResPSCM : 7|64@0+ (1,0) [0|1.84467E+019] "unitless"  TSTR

BO_ 1840 TesterPhysicalReqPSCM: 64 TSTR
 SG_ TesterPhysicalReqPSCM : 7|64@0+ (1,0) [0|1.84467E+019] "unitless"  PSCM

BO_ 1713 ABS_Rapid_Data_Response_2: 8 ABS_ESC
 SG_ UUDTABSResponse2 : 7|64@0+ (1,0) [0|1.84467440737096E+019] "unitless"  TSTR

BO_ 1712 ABS_Rapid_Data_Response_1: 8 ABS_ESC
 SG_ UUDTABSResponse1 : 7|64@0+ (1,0) [0|1.84467440737096E+019] "unitless"  TSTR

BO_ 2024 TesterPhysicalResPCM: 64 ECM_HEV
 SG_ TesterPhysicalResPCM : 7|64@0+ (1,0) [0|1.84467E+019] "unitless"  TSTR

BO_ 2016 TesterPhysicalReqPCM: 64 TSTR
 SG_ TesterPhysicalReqPCM : 7|64@0+ (1,0) [0|1.84467E+019] "unitless"  ECM_HEV,PCM

BO_ 2015 TesterFunctionalReq_FD1: 64 TSTR
 SG_ TesterFunctionalReq : 7|64@0+ (1,0) [0|1.84467E+019] "unitless"  CMR_DSMC,VDM,SOBDMC_HPCM,HCM,IPMA_ADAS,ECM_HEV,PCM,PSCM,ABS_ESC,AWD_DLCM,GWM

BO_ 1814 TesterPhysicalReqGWM_FD1: 64 TSTR
 SG_ TesterPhysicalReqGWM_F1 : 7|64@0+ (1,0) [0|1.84467E+019] "unitless"  GWM

BO_ 1697 PCM_Rapid_Data_Response_2: 8 ECM_HEV
 SG_ UUDTPCMResponse2 : 7|64@0+ (1,0) [0|1.84467440737096E+019] "unitless"  TSTR

BO_ 1696 PCM_Rapid_Data_Response_1: 8 ECM_HEV
 SG_ UUDTPCMResponse1 : 7|64@0+ (1,0) [0|1.84467440737096E+019] "unitless"  TSTR

BO_ 1429 PCM_AutoSar_NetworkMgmt: 8 ECM_HEV
 SG_ PCM_GWOnBoardTester : 39|8@0+ (1,0) [0|255] "unitless"  GENERIC
 SG_ PCM_GWNMProxy : 47|8@0+ (1,0) [0|255] "unitless"  GENERIC
 SG_ PCM_AutoSarNMReserved4 : 63|8@0+ (1,0) [0|255] "unitless"  GENERIC
 SG_ PCM_AutoSarNMReserved3 : 55|8@0+ (1,0) [0|255] "unitless"  GENERIC
 SG_ PCM_AutoSarNMReserved2 : 31|8@0+ (1,0) [0|255] "unitless"  GENERIC
 SG_ PCM_AutoSarNMReserved1 : 23|8@0+ (1,0) [0|255] "unitless"  GENERIC
 SG_ PCM_AutoSarNMNodeId : 7|8@0+ (1,0) [0|255] "unitless"  GENERIC
 SG_ PCM_AutoSarNMControl : 15|8@0+ (1,0) [0|255] "unitless"  GENERIC

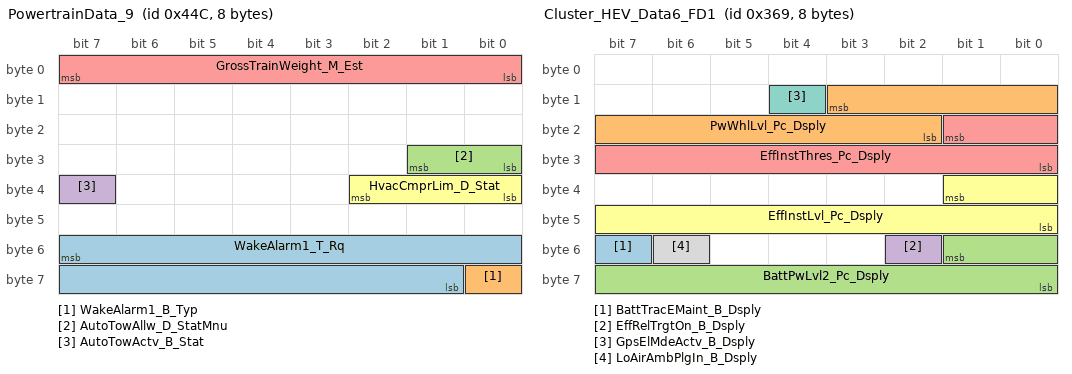
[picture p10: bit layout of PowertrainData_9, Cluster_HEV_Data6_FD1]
BO_ 1100 PowertrainData_9: 8 ECM_HEV
 SG_ WakeAlarm1_T_Rq : 55|15@0+ (1,0) [0|32767] "minute"  GWM
 SG_ WakeAlarm1_B_Typ : 56|1@0+ (1,0) [0|1] "SED"  GWM
 SG_ AutoTowAllw_D_StatMnu : 25|2@0+ (1,0) [0|3] "SED"  GWM
 SG_ AutoTowActv_B_Stat : 39|1@0+ (1,0) [0|1] "SED"  IPMA_ADAS,GWM
 SG_ GrossTrainWeight_M_Est : 7|8@0+ (100,0) [0|25300] "kilogram"  IPMA_ADAS,VDM,GWM,AWD_DLCM
 SG_ HvacCmprLim_D_Stat : 34|3@0+ (1,0) [0|7] "SED"  GWM

BO_ 873 Cluster_HEV_Data6_FD1: 8 SOBDMC_HPCM
 SG_ BattTracEMaint_B_Dsply : 55|1@0+ (1,0) [0|1] "SED"  GWM
 SG_ PwWhlLvl_Pc_Dsply : 11|10@0+ (0.2,-102.2) [-102.2|102.4] "percent"  GWM
 SG_ BattPwLvl2_Pc_Dsply : 49|10@0+ (0.2,-102.2) [-102.2|102.4] "percent"  GWM
 SG_ EffRelTrgtOn_B_Dsply : 50|1@0+ (1,0) [0|1] "SED"  GWM
 SG_ EffInstThres_Pc_Dsply : 17|10@0+ (0.1,0) [0|102.3] "percent"  GWM
 SG_ EffInstLvl_Pc_Dsply : 33|10@0+ (0.1,0) [0|102.3] "percent"  GWM
 SG_ GpsElMdeActv_B_Dsply : 12|1@0+ (1,0) [0|1] "SED"  GWM
 SG_ LoAirAmbPlgIn_B_Dsply : 54|1@0+ (1,0) [0|1] "SED"  GWM

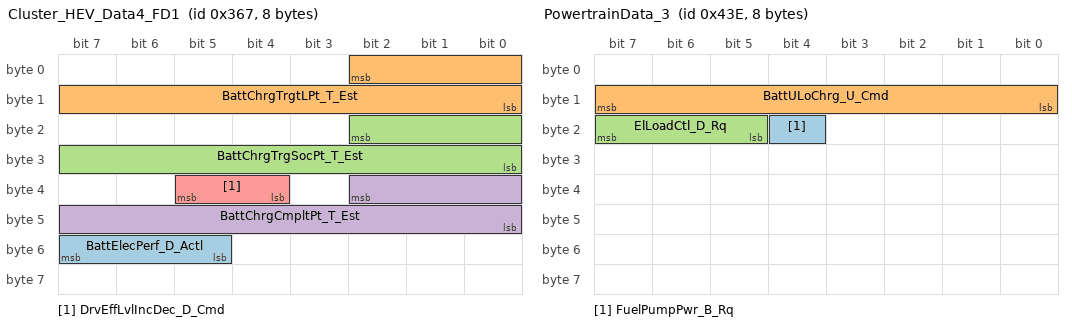
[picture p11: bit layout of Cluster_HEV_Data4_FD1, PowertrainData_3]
BO_ 871 Cluster_HEV_Data4_FD1: 8 SOBDMC_HPCM
 SG_ BattElecPerf_D_Actl : 55|3@0+ (1,0) [0|7] "SED"  GWM
 SG_ BattChrgTrgtLPt_T_Est : 2|11@0+ (1,0) [0|2045] "minute"  GWM
 SG_ BattChrgTrgSocPt_T_Est : 18|11@0+ (1,0) [0|2045] "minute"  GWM
 SG_ BattChrgCmpltPt_T_Est : 34|11@0+ (1,0) [0|2045] "minute"  GWM
 SG_ DrvEffLvlIncDec_D_Cmd : 37|2@0+ (1,0) [0|3] "SED"  GWM

BO_ 1098 EffDrvModeData: 8 PCM
 SG_ EcoCochInstTot_Pc_Dsply : 47|8@0+ (0.392157,0) [0|100.000035] "percent"  GWM

BO_ 1086 PowertrainData_3: 8 ECM_HEV
 SG_ FuelPumpPwr_B_Rq : 20|1@0+ (1,0) [0|1] "SED"  GWM
 SG_ BattULoChrg_U_Cmd : 15|8@0+ (0.025,10.6) [10.6|16.975] "volt"  GWM
 SG_ ElLoadCtl_D_Rq : 23|3@0+ (1,0) [0|7] "SED"  GWM

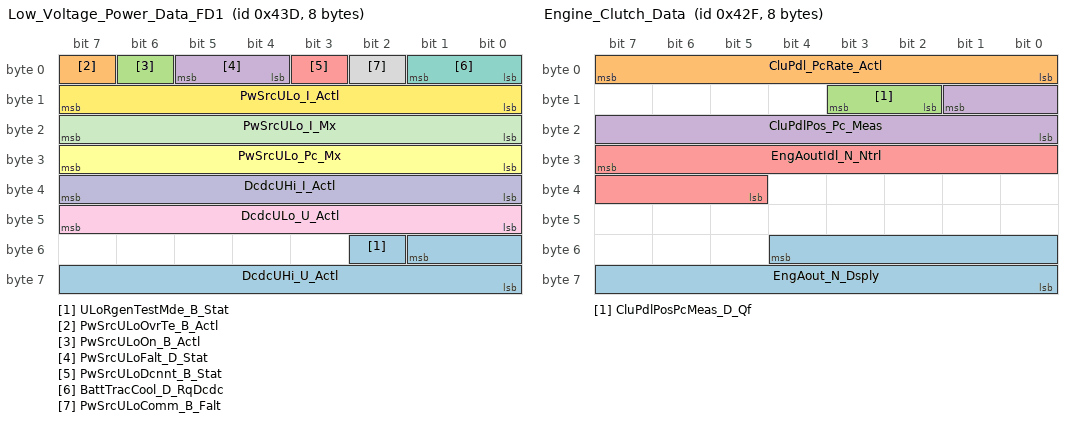
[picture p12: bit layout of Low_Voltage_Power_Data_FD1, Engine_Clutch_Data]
BO_ 1085 Low_Voltage_Power_Data_FD1: 8 GWM
 SG_ ULoRgenTestMde_B_Stat : 50|1@0+ (1,0) [0|1] "SED"  GWM
 SG_ PwSrcULoOvrTe_B_Actl : 7|1@0+ (1,0) [0|1] "SED"  SOBDMC_HPCM,GWM
 SG_ PwSrcULoOn_B_Actl : 6|1@0+ (1,0) [0|1] "SED"  SOBDMC_HPCM,ECM_HEV,GWM
 SG_ PwSrcULoFalt_D_Stat : 5|2@0+ (1,0) [0|3] "SED"  GWM
 SG_ PwSrcULoDcnnt_B_Stat : 3|1@0+ (1,0) [0|1] "SED"  SOBDMC_HPCM,ECM_HEV,GWM
 SG_ PwSrcULo_Pc_Mx : 31|8@0+ (0.4,0) [0|101.6] "%"  SOBDMC_HPCM,GWM
 SG_ BattTracCool_D_RqDcdc : 1|2@0+ (1,0) [0|3] "SED"  GWM
 SG_ PwSrcULoComm_B_Falt : 2|1@0+ (1,0) [0|1] "SED"  GWM
 SG_ DcdcULo_U_Actl : 47|8@0+ (0.1,0) [0|25.4] "Volts"  SOBDMC_HPCM,ECM_HEV,GWM
 SG_ DcdcUHi_I_Actl : 39|8@0+ (0.1,0) [0|25.4] "Amps"  SOBDMC_HPCM,GWM
 SG_ PwSrcULo_I_Mx : 23|8@0+ (1,0) [0|254] "ampere"  SOBDMC_HPCM,ECM_HEV,GWM
 SG_ PwSrcULo_I_Actl : 15|8@0+ (1,0) [0|254] "ampere"  SOBDMC_HPCM,ECM_HEV,GWM
 SG_ DcdcUHi_U_Actl : 49|10@0+ (0.5,0) [0|510.5] "V"  SOBDMC_HPCM,ECM_HEV,GWM

BO_ 1071 Engine_Clutch_Data: 8 ECM_HEV
 SG_ EngAout_N_Dsply : 52|13@0+ (2,0) [0|16382] "rpm"  GWM
 SG_ CluPdl_PcRate_Actl : 7|8@0+ (0.04,-5) [-5|5.2] "%/ms"  ABS_ESC,GWM
 SG_ CluPdlPosPcMeas_D_Qf : 11|2@0+ (1,0) [0|3] "SED"  ABS_ESC,GWM
 SG_ CluPdlPos_Pc_Meas : 9|10@0+ (0.1,0) [0|102.3] "%"  ABS_ESC,GWM
 SG_ EngAoutIdl_N_Ntrl : 31|11@0+ (2,0) [0|4094] "rpm"  ABS_ESC,GWM

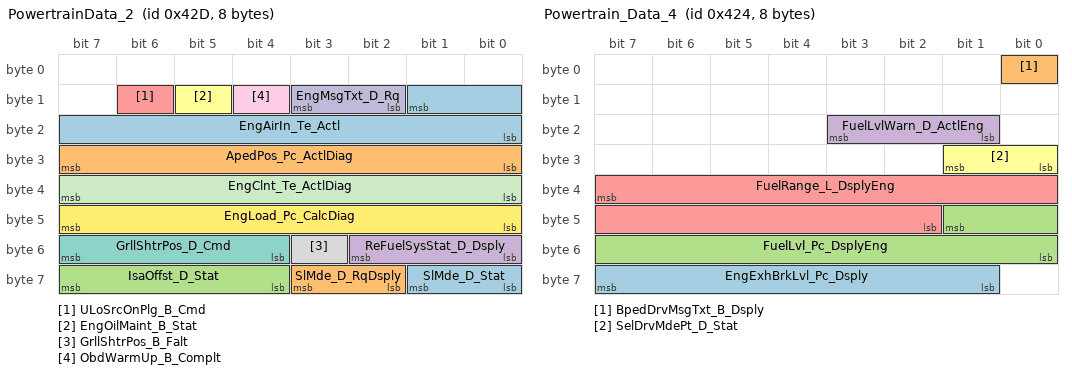
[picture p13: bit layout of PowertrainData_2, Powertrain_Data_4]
BO_ 1069 PowertrainData_2: 8 ECM_HEV
 SG_ SlMde_D_Stat : 57|2@0+ (1,0) [0|3] "SED"  GWM
 SG_ SlMde_D_RqDsply : 59|2@0+ (1,0) [0|3] "SED"  GWM
 SG_ IsaOffst_D_Stat : 63|4@0+ (1,0) [0|15] "SED"  GWM
 SG_ ReFuelSysStat_D_Dsply : 50|3@0+ (1,0) [0|7] "SED"  GWM
 SG_ ULoSrcOnPlg_B_Cmd : 14|1@0+ (1,0) [0|1] "SED"  SOBDMC_HPCM,GWM
 SG_ EngOilMaint_B_Stat : 13|1@0+ (1,0) [0|1] "SED"  SOBDMC_HPCM,GWM
 SG_ GrllShtrPos_D_Cmd : 55|4@0+ (1,0) [0|15] "SED"  GWM
 SG_ GrllShtrPos_B_Falt : 51|1@0+ (1,0) [0|1] "SED"  GWM
 SG_ ObdWarmUp_B_Complt : 12|1@0+ (1,0) [0|1] "SED"  SOBDMC_HPCM,GWM
 SG_ EngMsgTxt_D_Rq : 11|2@0+ (1,0) [0|3] "SED"  GWM
 SG_ EngClnt_Te_ActlDiag : 39|8@0+ (1,-40) [-40|215] "degC"  SOBDMC_HPCM,GWM
 SG_ EngLoad_Pc_CalcDiag : 47|8@0+ (0.392157,0) [0|100.000035] "%"  SOBDMC_HPCM,GWM
 SG_ EngAirIn_Te_Actl : 9|10@0+ (0.25,-128) [-128|127.25] "degC"  GWM
 SG_ ApedPos_Pc_ActlDiag : 31|8@0+ (0.392157,0) [0|100.000035] "%"  SOBDMC_HPCM,GWM

BO_ 1060 Powertrain_Data_4: 8 ECM_HEV
 SG_ EngExhBrkLvl_Pc_Dsply : 63|7@0+ (1,0) [0|127] "Percent"  GWM
 SG_ BpedDrvMsgTxt_B_Dsply : 0|1@0+ (1,0) [0|1] "SED"  GWM
 SG_ FuelLvl_Pc_DsplyEng : 41|10@0+ (0.108696,-5.217408) [-5.217408|105.9786] "percent"  GWM
 SG_ FuelLvlWarn_D_ActlEng : 19|3@0+ (1,0) [0|7] "SED"  GWM
 SG_ FuelRange_L_DsplyEng : 39|14@0+ (0.1,0) [0|1638.3] "kilometer"  GWM
 SG_ SelDrvMdePt_D_Stat : 25|2@0+ (1,0) [0|3] "SED"  ABS_ESC,GWM

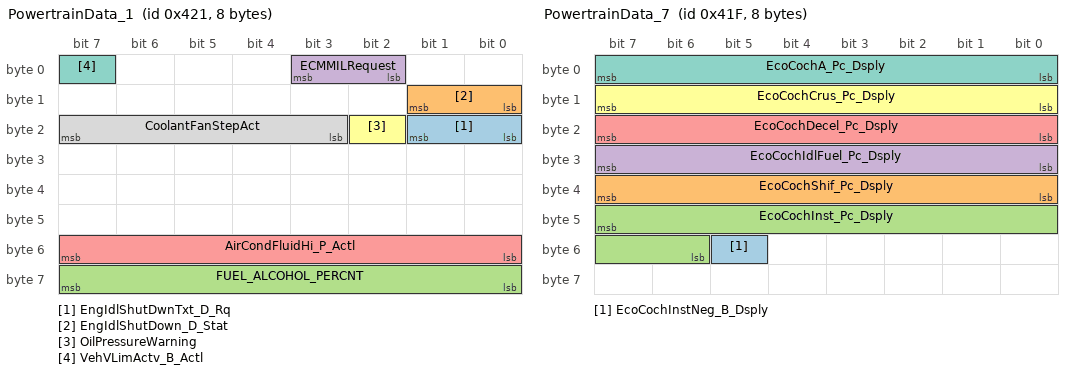
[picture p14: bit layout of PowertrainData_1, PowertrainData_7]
BO_ 1057 PowertrainData_1: 8 ECM_HEV
 SG_ EngIdlShutDwnTxt_D_Rq : 17|2@0+ (1,0) [0|3] "SED"  GWM
 SG_ EngIdlShutDown_D_Stat : 9|2@0+ (1,0) [0|3] "SED"  GWM
 SG_ FUEL_ALCOHOL_PERCNT : 63|8@0+ (0.393700787,0) [0|99.999899898] "Percent"  GWM
 SG_ ECMMILRequest : 3|2@0+ (1,0) [0|3] "SED"  GWM
 SG_ AirCondFluidHi_P_Actl : 55|8@0+ (0.125,0) [0|31.625] "bar"  SOBDMC_HPCM,GWM
 SG_ OilPressureWarning : 18|1@0+ (1,0) [0|1] "SED"  GWM
 SG_ VehVLimActv_B_Actl : 7|1@0+ (1,0) [0|1] "SED"  SOBDMC_HPCM,GWM
 SG_ CoolantFanStepAct : 23|5@0+ (1,0) [0|31] "Steps"  GWM

BO_ 1055 PowertrainData_7: 8 ECM_HEV
 SG_ EcoCochInstNeg_B_Dsply : 53|1@0+ (1,0) [0|1] "SED"  GWM
 SG_ EcoCochShif_Pc_Dsply : 39|8@0+ (0.392157,0) [0|100.000035] "percent"  GWM
 SG_ EcoCochInst_Pc_Dsply : 47|10@0+ (0.1,0) [0|102.3] "percent"  GWM
 SG_ EcoCochIdlFuel_Pc_Dsply : 31|8@0+ (0.392157,0) [0|100.000035] "percent"  GWM
 SG_ EcoCochDecel_Pc_Dsply : 23|8@0+ (0.392157,0) [0|100.000035] "percent"  GWM
 SG_ EcoCochCrus_Pc_Dsply : 15|8@0+ (0.392157,0) [0|100.000035] "percent"  GWM
 SG_ EcoCochA_Pc_Dsply : 7|8@0+ (0.392157,0) [0|100.000035] "percent"  GWM

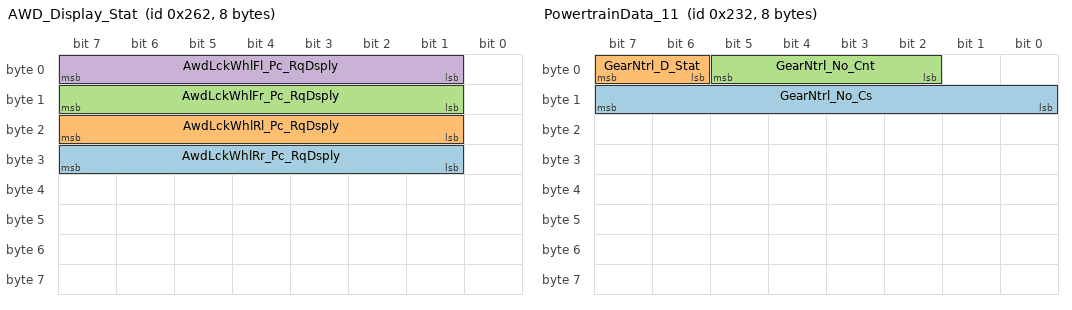
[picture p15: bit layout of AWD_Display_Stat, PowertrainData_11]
BO_ 610 AWD_Display_Stat: 8 AWD_DLCM
 SG_ AwdLckWhlRr_Pc_RqDsply : 31|7@0+ (1,0) [0|127] "percent"  GWM
 SG_ AwdLckWhlRl_Pc_RqDsply : 23|7@0+ (1,0) [0|127] "percent"  GWM
 SG_ AwdLckWhlFr_Pc_RqDsply : 15|7@0+ (1,0) [0|127] "percent"  GWM
 SG_ AwdLckWhlFl_Pc_RqDsply : 7|7@0+ (1,0) [0|127] "percent"  GWM

BO_ 562 PowertrainData_11: 8 ECM_HEV
 SG_ GearNtrl_No_Cs : 15|8@0+ (1,0) [0|255] "unitless"  GWM
 SG_ GearNtrl_D_Stat : 7|2@0+ (1,0) [0|3] "SED"  ABS_ESC,GWM
 SG_ GearNtrl_No_Cnt : 5|4@0+ (1,0) [0|15] "unitless"  GWM

BO_ 517 PowertrainData_6: 8 ECM_HEV
 SG_ FapLc_B_Err : 10|1@0+ (1,0) [0|1] "SED"  IPMA_ADAS,GWM
 SG_ BrkTot_Tq_RqFapLc : 7|13@0+ (4,0) [0|32764] "Nm"  ABS_ESC,GWM

BO_TX_BU_ 606 : PCM,SOBDMC_HPCM;
BO_TX_BU_ 374 : SOBDMC_HPCM,PCM;
BO_TX_BU_ 560 : ECM_HEV,SOBDMC_HPCM,PCM;
BO_TX_BU_ 369 : PCM,SOBDMC_HPCM;
BO_TX_BU_ 92 : SOBDMC_HPCM,PCM;
BO_TX_BU_ 1087 : PCM,ECM_HEV;
BO_TX_BU_ 2024 : PCM,ECM_HEV;
BO_TX_BU_ 1697 : PCM,ECM_HEV;
BO_TX_BU_ 1696 : PCM,ECM_HEV;
BO_TX_BU_ 1429 : PCM,ECM_HEV;
BO_TX_BU_ 1100 : PCM,ECM_HEV;
BO_TX_BU_ 1098 : ECM_HEV,PCM;
BO_TX_BU_ 1086 : PCM,ECM_HEV;
BO_TX_BU_ 1085 : PCM,GWM;
BO_TX_BU_ 1071 : PCM,ECM_HEV;
BO_TX_BU_ 1069 : PCM,ECM_HEV;
BO_TX_BU_ 1060 : PCM,ECM_HEV;
BO_TX_BU_ 1057 : PCM,ECM_HEV;
BO_TX_BU_ 1055 : PCM,ECM_HEV;
BO_TX_BU_ 610 : SOBDMC_HPCM,AWD_DLCM;
BO_TX_BU_ 562 : ECM_HEV,PCM;
BO_TX_BU_ 517 : PCM,ECM_HEV;
CM_ SG_ 534 BrkObdData_No_Actl "Signal not transmitted on gas, diesel and HEV.  Only supported on PHEV.";
CM_ SG_ 534 BrkObdIndex_No_Actl "Signal not transmitted on gas, diesel and HEV.  Only supported on PHEV.";
CM_ SG_ 534 WhlRotatRr_No_Cnt "DCR 1833 to update Tx from GWM to EP100ms. Wheel Count signals are used by complex algorithm to determine Tire Pressure by Location & can't change from 20msec. (jweinfur)";
CM_ SG_ 534 WhlRotatRl_No_Cnt "DCR 1833 to update Tx from GWM to EP100ms. Wheel Count signals are used by complex algorithm to determine Tire Pressure by Location & can't change from 20msec. (jweinfur)";
CM_ SG_ 534 WhlRotatFr_No_Cnt "DCR 1833 to update Tx from GWM to EP100ms. Wheel Count signals are used by complex algorithm to determine Tire Pressure by Location & can't change from 20msec. (jweinfur)";
CM_ SG_ 534 WhlRotatFl_No_Cnt "DCR 1833 to update Tx from GWM to EP100ms. Wheel Count signals are used by complex algorithm to determine Tire Pressure by Location & can't change from 20msec. (jweinfur)";
CM_ BO_ 532 "IC is NOT to use data in this message for displays, Used data from 415 instead.";
CM_ BO_ 531 "When PBM is present use 0x41B for PrkMsgTxt_D_Rq, PrkBrkRedLamp_D_Rq, PrkBrkYwLamp_D_Rq source signals otherwise ABS will source from 0x213.";
CM_ SG_ 118 SteWhlCompAnEst_D_Qf "Legacy signal not supported, reserving bit locations for commodity BCM, PAM, RCM, APIM dbc files.  GWM to Tx Init value, no valid data. ";
CM_ SG_ 118 SteWhlComp_An_Est "Legacy signal not supported, reserving bit locations for commodity BCM, PAM, RCM, APIM dbc files.  GWM to Tx Init value, no valid data. ";
CM_ BO_ 73 "Provide target function information to the control function of the Passive Anti-Theft Subsystem";
CM_ SG_ 1034 VehicleGGCCData "RCMGenSigTimeout=6000";
CM_ SG_ 870 PolicePurstMde_B_Stat "Normal SED EP 1000. Using 100FP can result  in100ms w/c latency.  Latency accepted for feature/function by SME since existing FGW msg.";
CM_ BO_ 374 "Programs w/o HS1 0x172 will need HS1 0x176 for GearPos_D_Actl.  Future MY Programs that choose c/o still require HS1 0x172. ";
CM_ SG_ 374 TrnRng_D_Rq "Powersplit HEVs with HF45, HPCM will Tx  this message.  For all other programs it will be Tx by PCM or TCM. ";
CM_ SG_ 374 TrnPrkSys_D_Actl "Powersplit HEVs with HF45, HPCM will Tx  this message.  For all other programs it will be Tx by PCM or TCM. ";
CM_ SG_ 374 GearLvr_D_ActlDrv "Powersplit HEVs with HF45, HPCM will Tx  this message.  For all other programs it will be Tx by PCM or TCM. ";
CM_ SG_ 374 GearPos_No_Cs "Powersplit HEVs with HF45, HPCM will Tx  this message.  For all other programs it will be Tx by PCM or TCM. ";
CM_ SG_ 374 GearPos_D_Trg "Powersplit HEVs with HF45, HPCM will Tx  this message.  For all other programs it will be Tx by PCM or TCM. ";
CM_ SG_ 374 GearPos_No_Cnt "Powersplit HEVs with HF45, HPCM will Tx  this message.  For all other programs it will be Tx by PCM or TCM. ";
CM_ SG_ 374 GearPos_D_Actl "Powersplit HEVs with HF45, HPCM will Tx  this message.  For all other programs it will be Tx by PCM or TCM. ";
CM_ BO_ 603 "48V mHEV: ECM_HEVDSL is Tx
MHT HEV: PCM_HEV is Tx
Powersplit HEV: SOBDMC_HPCM is Tx
";
CM_ SG_ 603 WhlDirAvgDrv_D_Actl "48V mHEV: ECM_HEVDSL is Tx,  MHT HEV: PCM_HEV is Tx,  Powersplit HEV: SOBDMC_HPCM is Tx";
CM_ SG_ 603 PrplTqMnRgen_B_Actl "48V mHEV: ECM_HEVDSL is Tx,  MHT HEV: PCM_HEV is Tx,  Powersplit HEV: SOBDMC_HPCM is Tx";
CM_ SG_ 603 BattTracCnnct_D_Rq "48V mHEV: ECM_HEVDSL is Tx,  MHT HEV: PCM_HEV is Tx,  Powersplit HEV: SOBDMC_HPCM is Tx";
CM_ BO_ 560 "MHT (U611/625) the HPCM will Rx 0x230 from the PCM_HEV
Powersplit FWD HEV’s (Cx482/3 430) the HPCM will Tx 0x230";
CM_ SG_ 560 SelDrvMdeSwtch_D_Stat3 "ECM_HEV does not support or Transmit signal.";
CM_ SG_ 560 GearLvrPosActl_No_Cs "Signal not transmitted on Gas & HEV variants. MHT(U611/625) HPCM Rx 0x230 from PCM_HEV. Powersplit FWD HEV’s(Cx482/3 430) HPCM Tx 0x230.";
CM_ SG_ 560 GearLvrPosActl_No_Cnt "Signal not transmitted on Gas & HEV variants. MHT(U611/625) HPCM Rx 0x230 from PCM_HEV. Powersplit FWD HEV’s(Cx482/3 430) HPCM Tx 0x230.";
CM_ SG_ 560 TrnGbox_Rt_Actl "Signal not transmitted on Gas & HEV variants. MHT(U611/625) HPCM Rx 0x230 from PCM_HEV. Powersplit FWD HEV’s(Cx482/3 430) HPCM Tx 0x230.";
CM_ SG_ 560 TrnSrvcRqd_B_Rq "Signal not transmitted on Diesel & HEV variants. MHT(U611/625) HPCM Rx 0x230 from PCM_HEV. Powersplit FWD HEV’s(Cx482/3 430) HPCM Tx 0x230.";
CM_ SG_ 560 TrnCnvtClu_D_Actl "Signal not transmitted on Gas & HEV variants. MHT(U611/625) HPCM Rx 0x230 from PCM_HEV. Powersplit FWD HEV’s(Cx482/3 430) HPCM Tx 0x230.";
CM_ SG_ 560 TrnShifActv_B_Actl "Signal not transmitted on HEV variants. MHT(U611/625) HPCM Rx 0x230 from PCM_HEV. Powersplit FWD HEV’s(Cx482/3 430) HPCM Tx 0x230.";
CM_ SG_ 560 GboxOil_Te_Actl "Signal not transmitted on HEV variants. MHT(U611/625) HPCM Rx 0x230 from PCM_HEV. Powersplit FWD HEV’s(Cx482/3 430) HPCM Tx 0x230.";
CM_ SG_ 369 TrnIpcDsplyMdeDActl_No_Cs "Applies to Drag Mode on S550 Only.";
CM_ SG_ 369 TrnIpcDsplyMdeDActl_No_Cnt "Applies to Drag Mode on S550 Only.";
CM_ SG_ 92 TrnGearMsgTxt2_D_Rq "Signal not transmitted on vehicles that do not have shift by wire.";
CM_ SG_ 92 TrnSbwSysHlth_D_Actl "Signal not transmitted on vehicles that do not have shift by wire.";
CM_ SG_ 92 TrnGearNtmAllow_B_Stat "Signal not transmitted on vehicles that do not have shift by wire.";
CM_ SG_ 92 TrnDtpCmd_D_Actl "Signal not transmitted on vehicles that do not have shift by wire.";
CM_ SG_ 92 TrnGearCmd_No_Cs "Signal not transmitted on vehicles that do not have shift by wire.";
CM_ SG_ 92 TrnValidGear_D_Cnfm "Signal not transmitted on vehicles that do not have shift by wire.";
CM_ SG_ 92 TrnNtrlTowCmd_D_Actl "Signal not transmitted on vehicles that do not have shift by wire.";
CM_ SG_ 92 TrnGearCmd_Pc_ActlPt "Signal not transmitted on vehicles that do not have shift by wire.";
CM_ SG_ 92 TrnGear_D_RqPt "Signal not transmitted on vehicles that do not have shift by wire.";
CM_ SG_ 92 TrnCmdState_B_Actl "Signal not transmitted on vehicles that do not have shift by wire.";
CM_ SG_ 92 TrnCmdCnt_B_Actl "Signal not transmitted on vehicles that do not have shift by wire.";
CM_ SG_ 92 PrkBrkActv_D_RqTrnGear "Signal not transmitted on vehicles that do not have shift by wire.";
CM_ SG_ 92 TrnGearMsgTxt_D_Rq "Signal not transmitted on vehicles that do not have shift by wire.";
CM_ SG_ 92 TrnGearCmd_No_Cnt "Signal not transmitted on vehicles that do not have shift by wire.";
CM_ BO_ 2015 "OBDII Request ($7DF) messages are for FNOS 1.0.1 only.
Diagnostic Functional Addressing ($7DF) and Dual Rate Periodic messages are for FNOS I3 only.";
CM_ SG_ 1086 ElLoadCtl_D_Rq "Signal not transmitted on HEV variants.";
CM_ BO_ 1085 "Tx by FD1 ECM, ECM_DIESEL, ECM_HEVDSL, PCM, PCM_HEV
Or FrameGateway from HS1
Set to FixedPeriodic 50ms at all nodes so the transmit method and rate export from mdc to dbc
Program specific msg lists update attributes as needed.";
CM_ SG_ 1085 ULoRgenTestMde_B_Stat "Signal not transmitted on HEV variants.";
CM_ SG_ 1085 BattTracCool_D_RqDcdc "Signal not transmitted on gas and diesel variants.";
CM_ SG_ 1085 PwSrcULoComm_B_Falt "Signal not transmitted on HEV variants.";
CM_ SG_ 1085 DcdcULo_U_Actl "Signal not transmitted on gas and diesel variants.";
CM_ SG_ 1085 DcdcUHi_I_Actl "Signal not transmitted on gas and diesel variants.";
CM_ SG_ 1085 DcdcUHi_U_Actl "Signal not transmitted on gas and diesel variants.";
CM_ SG_ 1071 CluPdl_PcRate_Actl "Signal not transmitted on HEV variants.";
CM_ SG_ 1071 CluPdlPosPcMeas_D_Qf "Signal not transmitted on HEV variants.";
CM_ SG_ 1071 CluPdlPos_Pc_Meas "Signal not transmitted on HEV variants.";
CM_ SG_ 1071 EngAoutIdl_N_Ntrl "Signal not transmitted on HEV variants and diesel.";
CM_ SG_ 1069 SlMde_D_Stat "IPC and HUD_ADV Receve from HS3 FGW 0x42D, not HS3 0x38A, MSG DCR 506.";
CM_ SG_ 1069 SlMde_D_RqDsply "IPC and HUD_ADV Receve from HS3 FGW 0x42D, not HS3 0x38A, MSG DCR 506.";
CM_ SG_ 1069 ObdWarmUp_B_Complt "Signal not transmitted on gas and diesel variants.";
CM_ SG_ 1069 EngMsgTxt_D_Rq "Signal not transmitted on diesel variants.";
CM_ SG_ 1069 EngClnt_Te_ActlDiag "Signal not transmitted on gas variants.";
CM_ SG_ 1069 EngLoad_Pc_CalcDiag "Signal not transmitted on gas variants.";
CM_ SG_ 1069 ApedPos_Pc_ActlDiag "Signal not transmitted on gas variants.";
CM_ SG_ 1057 EngIdlShutDown_D_Stat "Signal not transmitted on diesel variants.";
CM_ SG_ 1057 FUEL_ALCOHOL_PERCNT "signal not transmitted on diesel and HEV variants.";
CM_ SG_ 1057 VehVLimActv_B_Actl "Signal not transmitted on gas and HEV variants.";
CM_ SG_ 562 GearNtrl_No_Cs "Powersplit HEVs with HF45, HPCM will Tx  this message.  For all other programs it will be Tx by PCM or TCM. ";
CM_ SG_ 562 GearNtrl_No_Cnt "Powersplit HEVs with HF45, HPCM will Tx  this message.  For all other programs it will be Tx by PCM or TCM. ";
BA_DEF_ SG_  "U_CDX706_MY2023_Tx" ENUM  "No","Yes";
BA_DEF_ SG_  "U_CDX706_MY2023_Rx" ENUM  "No","Yes";
BA_DEF_ BO_  "AuthFreshnessCounterSyncAttempt" INT 0 2;
BA_DEF_ BO_  "VFrameFormat" ENUM  "StandardCAN","ExtendedCAN","reserved","reserved","reserved","reserved","reserved","reserved","reserved","reserved","reserved","reserved","reserved","reserved","StandardCAN_FD","ExtendedCAN_FD";
BA_DEF_ SG_  "GenSigSendType" ENUM  "Cyclic","OnWrite","vector_leerstring","OnChange","vector_leerstring","IfActive","vector_leerstring","NoSigSendType";
BA_DEF_ SG_  "GenSigInactiveValue" INT 0 100000;
BA_DEF_ SG_  "WakeupSignal" ENUM  "No","Yes";
BA_DEF_ SG_  "UsedOnPgmDBC" ENUM  "No","Yes";
BA_DEF_ SG_  "GenSigStartValueInteger" INT 0 1000000000;
BA_DEF_ SG_  "ContentDependant" ENUM  "No","Yes";
BA_DEF_ SG_  "MetaData" ENUM  "No","Yes";
BA_DEF_ SG_  "GenSigStartValue" HEX 0 268435455;
BA_DEF_ SG_  "U_CX727_MY2021_Rx" ENUM  "No","Yes";
BA_DEF_ SG_  "U_P702_MY2021_Rx" ENUM  "No","Yes";
BA_DEF_ SG_  "U_T6_MCA_MY2020_Rx" ENUM  "No","Yes";
BA_DEF_ SG_  "ECGUsedRxSignal" ENUM  "No","Yes";
BA_DEF_ SG_  "U_CD542_MY2021_Rx" ENUM  "No","Yes";
BA_DEF_ SG_  "U_U55X_MY2022_Rx" ENUM  "No","Yes";
BA_DEF_ SG_  "U_CD764_MY2022_Rx" ENUM  "No","Yes";
BA_DEF_ SG_  "U_CX727_MY2021_Tx" ENUM  "No","Yes";
BA_DEF_ SG_  "U_P702_MY2021_Tx" ENUM  "No","Yes";
BA_DEF_ SG_  "U_T6_MCA_MY2020_Tx" ENUM  "No","Yes";
BA_DEF_ SG_  "ECGUsedTxSignal" ENUM  "No","Yes";
BA_DEF_ SG_  "U_CD542_MY2021_Tx" ENUM  "No","Yes";
BA_DEF_ SG_  "U_U55X_MY2022_Tx" ENUM  "No","Yes";
BA_DEF_ SG_  "U_CD764_MY2022_Tx" ENUM  "No","Yes";
BA_DEF_ BO_  "GenMsgILSupport" ENUM  "No","Yes";
BA_DEF_ BO_  "DiagResponse" ENUM  "No","Yes";
BA_DEF_ BO_  "DiagRequest" ENUM  "No","Yes";
BA_DEF_ BO_  "TpTxIndex" INT 0 536870911;
BA_DEF_ BO_  "DiagState" ENUM  "No","Yes";
BA_DEF_ BO_  "TpApplType" STRING ;
BA_DEF_ BO_  "NmAsrMessage" ENUM  "No","Yes";
BA_DEF_ BO_  "SCP_AuthInfoTxLength" INT 0 512;
BA_DEF_ BO_  "SCP_FreshnessValueTxLength" INT 0 512;
BA_DEF_ BO_  "SCP_FreshnessValueLength" INT 0 512;
BA_DEF_ BO_  "OvtpPushApplication" ENUM  "FALSE","TRUE";
BA_DEF_ BO_  "GenMsgSendType" ENUM  "FixedPeriodic","Event","EnabledPeriodic","NotUsed","NotUsed","EventPeriodic","NotUsed","NotUsed","NoMsgSendType";
BA_DEF_ BO_  "GenMsgCycleTime" INT 0 100000;
BA_DEF_ BO_  "GenMsgDelayTime" INT 0 1000;
BA_DEF_ BO_  "GenMsgNrOfRepetition" INT 0 100;
BA_DEF_ BO_  "GenMsgStartDelayTime" INT 0 10000;
BA_DEF_ BO_  "EventRateOfChange" INT 10 10000;
BA_DEF_ BO_  "FrameGatewayId" HEX 0 1407;
BA_DEF_ BO_  "NetworkInitialization" ENUM  "No","Yes";
BA_DEF_ BO_  "FrameGatewayNetwork" STRING ;
BA_DEF_ BO_  "FrameRouting" STRING ;
BA_DEF_DEF_  "U_CDX706_MY2023_Tx" "No";
BA_DEF_DEF_  "U_CDX706_MY2023_Rx" "No";
BA_DEF_DEF_  "AuthFreshnessCounterSyncAttempt" 2;
BA_DEF_DEF_  "VFrameFormat" "ExtendedCAN_FD";
BA_DEF_DEF_  "GenSigSendType" "NoSigSendType";
BA_DEF_DEF_  "GenSigInactiveValue" 0;
BA_DEF_DEF_  "WakeupSignal" "No";
BA_DEF_DEF_  "UsedOnPgmDBC" "Yes";
BA_DEF_DEF_  "GenSigStartValueInteger" 0;
BA_DEF_DEF_  "ContentDependant" "No";
BA_DEF_DEF_  "MetaData" "No";
BA_DEF_DEF_  "GenSigStartValue" 0;
BA_DEF_DEF_  "U_CX727_MY2021_Rx" "No";
BA_DEF_DEF_  "U_P702_MY2021_Rx" "No";
BA_DEF_DEF_  "U_T6_MCA_MY2020_Rx" "No";
BA_DEF_DEF_  "ECGUsedRxSignal" "No";
BA_DEF_DEF_  "U_CD542_MY2021_Rx" "No";
BA_DEF_DEF_  "U_U55X_MY2022_Rx" "No";
BA_DEF_DEF_  "U_CD764_MY2022_Rx" "No";
BA_DEF_DEF_  "U_CX727_MY2021_Tx" "No";
BA_DEF_DEF_  "U_P702_MY2021_Tx" "No";
BA_DEF_DEF_  "U_T6_MCA_MY2020_Tx" "No";
BA_DEF_DEF_  "ECGUsedTxSignal" "No";
BA_DEF_DEF_  "U_CD542_MY2021_Tx" "No";
BA_DEF_DEF_  "U_U55X_MY2022_Tx" "No";
BA_DEF_DEF_  "U_CD764_MY2022_Tx" "No";
BA_DEF_DEF_  "GenMsgILSupport" "Yes";
BA_DEF_DEF_  "DiagResponse" "No";
BA_DEF_DEF_  "DiagRequest" "No";
BA_DEF_DEF_  "TpTxIndex" 0;
BA_DEF_DEF_  "DiagState" "No";
BA_DEF_DEF_  "TpApplType" "";
BA_DEF_DEF_  "NmAsrMessage" "No";
BA_DEF_DEF_  "SCP_AuthInfoTxLength" 53;
BA_DEF_DEF_  "SCP_FreshnessValueTxLength" 11;
BA_DEF_DEF_  "SCP_FreshnessValueLength" 64;
BA_DEF_DEF_  "OvtpPushApplication" "FALSE";
BA_DEF_DEF_  "GenMsgSendType" "NoMsgSendType";
BA_DEF_DEF_  "GenMsgCycleTime" 0;
BA_DEF_DEF_  "GenMsgDelayTime" 20;
BA_DEF_DEF_  "GenMsgNrOfRepetition" 1;
BA_DEF_DEF_  "GenMsgStartDelayTime" 0;
BA_DEF_DEF_  "EventRateOfChange" 10000;
BA_DEF_DEF_  "FrameGatewayId" 0;
BA_DEF_DEF_  "NetworkInitialization" "Yes";
BA_DEF_DEF_  "FrameGatewayNetwork" "NONE";
BA_DEF_DEF_  "FrameRouting" "";
BA_ "GenMsgSendType" BO_ 535 0;
BA_ "GenMsgCycleTime" BO_ 535 10;
BA_ "GenMsgDelayTime" BO_ 535 0;
BA_ "VFrameFormat" BO_ 535 14;
BA_ "GenMsgSendType" BO_ 534 0;
BA_ "GenMsgCycleTime" BO_ 534 20;
BA_ "GenMsgDelayTime" BO_ 534 10;
BA_ "VFrameFormat" BO_ 534 14;
BA_ "GenMsgSendType" BO_ 532 0;
BA_ "GenMsgCycleTime" BO_ 532 20;
BA_ "GenMsgDelayTime" BO_ 532 10;
BA_ "VFrameFormat" BO_ 532 14;
BA_ "GenMsgSendType" BO_ 531 0;
BA_ "GenMsgCycleTime" BO_ 531 20;
BA_ "GenMsgDelayTime" BO_ 531 10;
BA_ "VFrameFormat" BO_ 531 14;
BA_ "GenMsgSendType" BO_ 127 0;
BA_ "GenMsgCycleTime" BO_ 127 20;
BA_ "GenMsgDelayTime" BO_ 127 10;
BA_ "VFrameFormat" BO_ 127 14;
BA_ "GenMsgSendType" BO_ 125 0;
BA_ "GenMsgCycleTime" BO_ 125 20;
BA_ "GenMsgDelayTime" BO_ 125 10;
BA_ "VFrameFormat" BO_ 125 14;
BA_ "GenMsgSendType" BO_ 119 0;
BA_ "GenMsgCycleTime" BO_ 119 20;
BA_ "GenMsgDelayTime" BO_ 119 10;
BA_ "VFrameFormat" BO_ 119 14;
BA_ "GenMsgSendType" BO_ 118 5;
BA_ "GenMsgCycleTime" BO_ 118 500;
BA_ "VFrameFormat" BO_ 118 14;
BA_ "GenMsgSendType" BO_ 73 0;
BA_ "GenMsgCycleTime" BO_ 73 20;
BA_ "GenMsgDelayTime" BO_ 73 10;
BA_ "VFrameFormat" BO_ 73 14;
BA_ "FrameGatewayId" BO_ 1034 1034;
BA_ "FrameGatewayNetwork" BO_ 1034 "HS1_CAN";
BA_ "FrameRouting" BO_ 1034 "HS1_CAN,0x40A;";
BA_ "VFrameFormat" BO_ 1034 14;
BA_ "GenMsgSendType" BO_ 561 0;
BA_ "GenMsgCycleTime" BO_ 561 100;
BA_ "VFrameFormat" BO_ 561 14;
BA_ "GenMsgSendType" BO_ 1090 0;
BA_ "GenMsgCycleTime" BO_ 1090 1000;
BA_ "VFrameFormat" BO_ 1090 14;
BA_ "GenMsgSendType" BO_ 870 0;
BA_ "GenMsgCycleTime" BO_ 870 100;
BA_ "VFrameFormat" BO_ 870 14;
BA_ "GenMsgSendType" BO_ 869 0;
BA_ "GenMsgCycleTime" BO_ 869 100;
BA_ "VFrameFormat" BO_ 869 14;
BA_ "GenMsgSendType" BO_ 606 5;
BA_ "GenMsgCycleTime" BO_ 606 1000;
BA_ "VFrameFormat" BO_ 606 14;
BA_ "GenMsgSendType" BO_ 374 5;
BA_ "GenMsgCycleTime" BO_ 374 100;
BA_ "VFrameFormat" BO_ 374 14;
BA_ "GenMsgSendType" BO_ 603 0;
BA_ "GenMsgCycleTime" BO_ 603 20;
BA_ "GenMsgDelayTime" BO_ 603 10;
BA_ "VFrameFormat" BO_ 603 14;
BA_ "GenMsgSendType" BO_ 602 0;
BA_ "GenMsgCycleTime" BO_ 602 100;
BA_ "VFrameFormat" BO_ 602 14;
BA_ "GenMsgSendType" BO_ 1152 5;
BA_ "GenMsgCycleTime" BO_ 1152 1000;
BA_ "VFrameFormat" BO_ 1152 14;
BA_ "GenMsgSendType" BO_ 872 0;
BA_ "GenMsgCycleTime" BO_ 872 100;
BA_ "VFrameFormat" BO_ 872 14;
BA_ "GenMsgSendType" BO_ 560 0;
BA_ "GenMsgCycleTime" BO_ 560 20;
BA_ "GenMsgDelayTime" BO_ 560 10;
BA_ "VFrameFormat" BO_ 560 14;
BA_ "GenMsgSendType" BO_ 369 0;
BA_ "GenMsgCycleTime" BO_ 369 30;
BA_ "GenMsgDelayTime" BO_ 369 10;
BA_ "VFrameFormat" BO_ 369 14;
BA_ "GenMsgSendType" BO_ 92 5;
BA_ "GenMsgCycleTime" BO_ 92 100;
BA_ "VFrameFormat" BO_ 92 14;
BA_ "GenMsgILSupport" BO_ 2030 0;
BA_ "DiagResponse" BO_ 2030 1;
BA_ "GenMsgSendType" BO_ 2030 1;
BA_ "GenMsgDelayTime" BO_ 2030 0;
BA_ "NetworkInitialization" BO_ 2030 0;
BA_ "VFrameFormat" BO_ 2030 14;
BA_ "GenMsgSendType" BO_ 1087 5;
BA_ "GenMsgCycleTime" BO_ 1087 1000;
BA_ "VFrameFormat" BO_ 1087 14;
BA_ "GenMsgILSupport" BO_ 1896 0;
BA_ "DiagResponse" BO_ 1896 1;
BA_ "GenMsgSendType" BO_ 1896 1;
BA_ "GenMsgDelayTime" BO_ 1896 0;
BA_ "NetworkInitialization" BO_ 1896 0;
BA_ "VFrameFormat" BO_ 1896 14;
BA_ "GenMsgILSupport" BO_ 1888 0;
BA_ "DiagRequest" BO_ 1888 1;
BA_ "GenMsgSendType" BO_ 1888 1;
BA_ "GenMsgDelayTime" BO_ 1888 0;
BA_ "NetworkInitialization" BO_ 1888 0;
BA_ "VFrameFormat" BO_ 1888 14;
BA_ "GenMsgILSupport" BO_ 1848 0;
BA_ "DiagResponse" BO_ 1848 1;
BA_ "GenMsgSendType" BO_ 1848 1;
BA_ "GenMsgDelayTime" BO_ 1848 0;
BA_ "NetworkInitialization" BO_ 1848 0;
BA_ "VFrameFormat" BO_ 1848 14;
BA_ "GenMsgILSupport" BO_ 1840 0;
BA_ "DiagRequest" BO_ 1840 1;
BA_ "GenMsgSendType" BO_ 1840 1;
BA_ "GenMsgDelayTime" BO_ 1840 0;
BA_ "NetworkInitialization" BO_ 1840 0;
BA_ "VFrameFormat" BO_ 1840 14;
BA_ "GenMsgILSupport" BO_ 1713 0;
BA_ "TpApplType" BO_ 1713 "DiagUUDTResponse";
BA_ "GenMsgSendType" BO_ 1713 1;
BA_ "NetworkInitialization" BO_ 1713 0;
BA_ "VFrameFormat" BO_ 1713 14;
BA_ "GenMsgILSupport" BO_ 1712 0;
BA_ "TpApplType" BO_ 1712 "DiagUUDTResponse";
BA_ "GenMsgSendType" BO_ 1712 1;
BA_ "NetworkInitialization" BO_ 1712 0;
BA_ "VFrameFormat" BO_ 1712 14;
BA_ "GenMsgILSupport" BO_ 2024 0;
BA_ "DiagResponse" BO_ 2024 1;
BA_ "GenMsgSendType" BO_ 2024 1;
BA_ "GenMsgDelayTime" BO_ 2024 0;
BA_ "NetworkInitialization" BO_ 2024 0;
BA_ "VFrameFormat" BO_ 2024 14;
BA_ "GenMsgILSupport" BO_ 2016 0;
BA_ "DiagRequest" BO_ 2016 1;
BA_ "GenMsgSendType" BO_ 2016 1;
BA_ "GenMsgDelayTime" BO_ 2016 0;
BA_ "NetworkInitialization" BO_ 2016 0;
BA_ "VFrameFormat" BO_ 2016 14;
BA_ "GenMsgILSupport" BO_ 2015 0;
BA_ "DiagState" BO_ 2015 1;
BA_ "GenMsgSendType" BO_ 2015 1;
BA_ "GenMsgDelayTime" BO_ 2015 0;
BA_ "NetworkInitialization" BO_ 2015 0;
BA_ "VFrameFormat" BO_ 2015 14;
BA_ "GenMsgILSupport" BO_ 1814 0;
BA_ "DiagRequest" BO_ 1814 1;
BA_ "GenMsgSendType" BO_ 1814 1;
BA_ "GenMsgDelayTime" BO_ 1814 0;
BA_ "NetworkInitialization" BO_ 1814 0;
BA_ "VFrameFormat" BO_ 1814 14;
BA_ "GenMsgILSupport" BO_ 1697 0;
BA_ "TpApplType" BO_ 1697 "DiagUUDTResponse";
BA_ "GenMsgSendType" BO_ 1697 1;
BA_ "NetworkInitialization" BO_ 1697 0;
BA_ "VFrameFormat" BO_ 1697 14;
BA_ "GenMsgILSupport" BO_ 1696 0;
BA_ "TpApplType" BO_ 1696 "DiagUUDTResponse";
BA_ "GenMsgSendType" BO_ 1696 1;
BA_ "NetworkInitialization" BO_ 1696 0;
BA_ "VFrameFormat" BO_ 1696 14;
BA_ "GenMsgILSupport" BO_ 1429 0;
BA_ "NmAsrMessage" BO_ 1429 1;
BA_ "GenMsgSendType" BO_ 1429 0;
BA_ "GenMsgCycleTime" BO_ 1429 1000;
BA_ "NetworkInitialization" BO_ 1429 0;
BA_ "VFrameFormat" BO_ 1429 14;
BA_ "GenMsgSendType" BO_ 1100 5;
BA_ "GenMsgCycleTime" BO_ 1100 1000;
BA_ "VFrameFormat" BO_ 1100 14;
BA_ "GenMsgSendType" BO_ 873 0;
BA_ "GenMsgCycleTime" BO_ 873 100;
BA_ "VFrameFormat" BO_ 873 14;
BA_ "GenMsgSendType" BO_ 871 0;
BA_ "GenMsgCycleTime" BO_ 871 100;
BA_ "VFrameFormat" BO_ 871 14;
BA_ "GenMsgSendType" BO_ 1098 5;
BA_ "GenMsgCycleTime" BO_ 1098 500;
BA_ "VFrameFormat" BO_ 1098 14;
BA_ "GenMsgSendType" BO_ 1086 0;
BA_ "GenMsgCycleTime" BO_ 1086 100;
BA_ "VFrameFormat" BO_ 1086 14;
BA_ "GenMsgSendType" BO_ 1085 0;
BA_ "GenMsgCycleTime" BO_ 1085 50;
BA_ "FrameGatewayId" BO_ 1085 1085;
BA_ "FrameGatewayNetwork" BO_ 1085 "HS1_CAN";
BA_ "FrameRouting" BO_ 1085 "HS1_CAN,0x43D;";
BA_ "VFrameFormat" BO_ 1085 14;
BA_ "GenMsgSendType" BO_ 1071 0;
BA_ "GenMsgCycleTime" BO_ 1071 30;
BA_ "GenMsgDelayTime" BO_ 1071 10;
BA_ "VFrameFormat" BO_ 1071 14;
BA_ "GenMsgSendType" BO_ 1069 0;
BA_ "GenMsgCycleTime" BO_ 1069 100;
BA_ "VFrameFormat" BO_ 1069 14;
BA_ "GenMsgSendType" BO_ 1060 0;
BA_ "GenMsgCycleTime" BO_ 1060 100;
BA_ "VFrameFormat" BO_ 1060 14;
BA_ "GenMsgSendType" BO_ 1057 0;
BA_ "GenMsgCycleTime" BO_ 1057 100;
BA_ "VFrameFormat" BO_ 1057 14;
BA_ "GenMsgSendType" BO_ 1055 0;
BA_ "GenMsgCycleTime" BO_ 1055 100;
BA_ "VFrameFormat" BO_ 1055 14;
BA_ "GenMsgSendType" BO_ 610 0;
BA_ "GenMsgCycleTime" BO_ 610 100;
BA_ "VFrameFormat" BO_ 610 14;
BA_ "GenMsgSendType" BO_ 562 0;
BA_ "GenMsgCycleTime" BO_ 562 100;
BA_ "VFrameFormat" BO_ 562 14;
BA_ "GenMsgSendType" BO_ 517 0;
BA_ "GenMsgCycleTime" BO_ 517 10;
BA_ "GenMsgDelayTime" BO_ 517 0;
BA_ "VFrameFormat" BO_ 517 14;
BA_ "U_CX727_MY2021_Rx" SG_ 535 WhlRr_W_Meas 1;
BA_ "U_P702_MY2021_Rx" SG_ 535 WhlRr_W_Meas 1;
BA_ "U_T6_MCA_MY2020_Rx" SG_ 535 WhlRr_W_Meas 1;
BA_ "U_CD542_MY2021_Rx" SG_ 535 WhlRr_W_Meas 1;
BA_ "U_U55X_MY2022_Rx" SG_ 535 WhlRr_W_Meas 1;
BA_ "U_CD764_MY2022_Rx" SG_ 535 WhlRr_W_Meas 1;
BA_ "U_CX727_MY2021_Tx" SG_ 535 WhlRr_W_Meas 1;
BA_ "U_P702_MY2021_Tx" SG_ 535 WhlRr_W_Meas 1;
BA_ "U_T6_MCA_MY2020_Tx" SG_ 535 WhlRr_W_Meas 1;
BA_ "U_CD542_MY2021_Tx" SG_ 535 WhlRr_W_Meas 1;
BA_ "U_U55X_MY2022_Tx" SG_ 535 WhlRr_W_Meas 1;
BA_ "U_CD764_MY2022_Tx" SG_ 535 WhlRr_W_Meas 1;
BA_ "U_CX727_MY2021_Rx" SG_ 535 WhlRl_W_Meas 1;
BA_ "U_P702_MY2021_Rx" SG_ 535 WhlRl_W_Meas 1;
BA_ "U_T6_MCA_MY2020_Rx" SG_ 535 WhlRl_W_Meas 1;
BA_ "U_CD542_MY2021_Rx" SG_ 535 WhlRl_W_Meas 1;
BA_ "U_U55X_MY2022_Rx" SG_ 535 WhlRl_W_Meas 1;
BA_ "U_CD764_MY2022_Rx" SG_ 535 WhlRl_W_Meas 1;
BA_ "U_CX727_MY2021_Tx" SG_ 535 WhlRl_W_Meas 1;
BA_ "U_P702_MY2021_Tx" SG_ 535 WhlRl_W_Meas 1;
BA_ "U_T6_MCA_MY2020_Tx" SG_ 535 WhlRl_W_Meas 1;
BA_ "U_CD542_MY2021_Tx" SG_ 535 WhlRl_W_Meas 1;
BA_ "U_U55X_MY2022_Tx" SG_ 535 WhlRl_W_Meas 1;
BA_ "U_CD764_MY2022_Tx" SG_ 535 WhlRl_W_Meas 1;
BA_ "U_CX727_MY2021_Rx" SG_ 535 WhlFr_W_Meas 1;
BA_ "U_P702_MY2021_Rx" SG_ 535 WhlFr_W_Meas 1;
BA_ "U_T6_MCA_MY2020_Rx" SG_ 535 WhlFr_W_Meas 1;
BA_ "U_CD542_MY2021_Rx" SG_ 535 WhlFr_W_Meas 1;
BA_ "U_U55X_MY2022_Rx" SG_ 535 WhlFr_W_Meas 1;
BA_ "U_CD764_MY2022_Rx" SG_ 535 WhlFr_W_Meas 1;
BA_ "U_CX727_MY2021_Tx" SG_ 535 WhlFr_W_Meas 1;
BA_ "U_P702_MY2021_Tx" SG_ 535 WhlFr_W_Meas 1;
BA_ "U_T6_MCA_MY2020_Tx" SG_ 535 WhlFr_W_Meas 1;
BA_ "U_CD542_MY2021_Tx" SG_ 535 WhlFr_W_Meas 1;
BA_ "U_U55X_MY2022_Tx" SG_ 535 WhlFr_W_Meas 1;
BA_ "U_CD764_MY2022_Tx" SG_ 535 WhlFr_W_Meas 1;
BA_ "U_CX727_MY2021_Rx" SG_ 535 WhlFl_W_Meas 1;
BA_ "U_P702_MY2021_Rx" SG_ 535 WhlFl_W_Meas 1;
BA_ "U_T6_MCA_MY2020_Rx" SG_ 535 WhlFl_W_Meas 1;
BA_ "U_CD542_MY2021_Rx" SG_ 535 WhlFl_W_Meas 1;
BA_ "U_U55X_MY2022_Rx" SG_ 535 WhlFl_W_Meas 1;
BA_ "U_CD764_MY2022_Rx" SG_ 535 WhlFl_W_Meas 1;
BA_ "U_CX727_MY2021_Tx" SG_ 535 WhlFl_W_Meas 1;
BA_ "U_P702_MY2021_Tx" SG_ 535 WhlFl_W_Meas 1;
BA_ "U_T6_MCA_MY2020_Tx" SG_ 535 WhlFl_W_Meas 1;
BA_ "U_CD542_MY2021_Tx" SG_ 535 WhlFl_W_Meas 1;
BA_ "U_U55X_MY2022_Tx" SG_ 535 WhlFl_W_Meas 1;
BA_ "U_CD764_MY2022_Tx" SG_ 535 WhlFl_W_Meas 1;
BA_ "ContentDependant" SG_ 534 BrkObdData_No_Actl 1;
BA_ "U_CX727_MY2021_Rx" SG_ 534 BrkObdData_No_Actl 1;
BA_ "U_CD542_MY2021_Rx" SG_ 534 BrkObdData_No_Actl 1;
BA_ "U_CX727_MY2021_Tx" SG_ 534 BrkObdData_No_Actl 1;
BA_ "U_P702_MY2021_Tx" SG_ 534 BrkObdData_No_Actl 1;
BA_ "U_T6_MCA_MY2020_Tx" SG_ 534 BrkObdData_No_Actl 1;
BA_ "U_CD542_MY2021_Tx" SG_ 534 BrkObdData_No_Actl 1;
BA_ "U_U55X_MY2022_Tx" SG_ 534 BrkObdData_No_Actl 1;
BA_ "U_CD764_MY2022_Tx" SG_ 534 BrkObdData_No_Actl 1;
BA_ "ContentDependant" SG_ 534 BrkObdIndex_No_Actl 1;
BA_ "U_CX727_MY2021_Rx" SG_ 534 BrkObdIndex_No_Actl 1;
BA_ "U_CD542_MY2021_Rx" SG_ 534 BrkObdIndex_No_Actl 1;
BA_ "U_CX727_MY2021_Tx" SG_ 534 BrkObdIndex_No_Actl 1;
BA_ "U_P702_MY2021_Tx" SG_ 534 BrkObdIndex_No_Actl 1;
BA_ "U_T6_MCA_MY2020_Tx" SG_ 534 BrkObdIndex_No_Actl 1;
BA_ "U_CD542_MY2021_Tx" SG_ 534 BrkObdIndex_No_Actl 1;
BA_ "U_U55X_MY2022_Tx" SG_ 534 BrkObdIndex_No_Actl 1;
BA_ "U_CD764_MY2022_Tx" SG_ 534 BrkObdIndex_No_Actl 1;
BA_ "U_P702_MY2021_Rx" SG_ 534 WhlRotatRr_No_Cnt 1;
BA_ "U_T6_MCA_MY2020_Rx" SG_ 534 WhlRotatRr_No_Cnt 1;
BA_ "U_CD542_MY2021_Rx" SG_ 534 WhlRotatRr_No_Cnt 1;
BA_ "U_U55X_MY2022_Rx" SG_ 534 WhlRotatRr_No_Cnt 1;
BA_ "U_CD764_MY2022_Rx" SG_ 534 WhlRotatRr_No_Cnt 1;
BA_ "U_CX727_MY2021_Tx" SG_ 534 WhlRotatRr_No_Cnt 1;
BA_ "U_P702_MY2021_Tx" SG_ 534 WhlRotatRr_No_Cnt 1;
BA_ "U_T6_MCA_MY2020_Tx" SG_ 534 WhlRotatRr_No_Cnt 1;
BA_ "U_CD542_MY2021_Tx" SG_ 534 WhlRotatRr_No_Cnt 1;
BA_ "U_U55X_MY2022_Tx" SG_ 534 WhlRotatRr_No_Cnt 1;
BA_ "U_CD764_MY2022_Tx" SG_ 534 WhlRotatRr_No_Cnt 1;
BA_ "U_CX727_MY2021_Rx" SG_ 534 WhlDirRr_D_Actl 1;
BA_ "U_P702_MY2021_Rx" SG_ 534 WhlDirRr_D_Actl 1;
BA_ "U_T6_MCA_MY2020_Rx" SG_ 534 WhlDirRr_D_Actl 1;
BA_ "U_CD542_MY2021_Rx" SG_ 534 WhlDirRr_D_Actl 1;
BA_ "U_U55X_MY2022_Rx" SG_ 534 WhlDirRr_D_Actl 1;
BA_ "U_CD764_MY2022_Rx" SG_ 534 WhlDirRr_D_Actl 1;
BA_ "U_CX727_MY2021_Tx" SG_ 534 WhlDirRr_D_Actl 1;
BA_ "U_P702_MY2021_Tx" SG_ 534 WhlDirRr_D_Actl 1;
BA_ "U_T6_MCA_MY2020_Tx" SG_ 534 WhlDirRr_D_Actl 1;
BA_ "U_CD542_MY2021_Tx" SG_ 534 WhlDirRr_D_Actl 1;
BA_ "U_U55X_MY2022_Tx" SG_ 534 WhlDirRr_D_Actl 1;
BA_ "U_CD764_MY2022_Tx" SG_ 534 WhlDirRr_D_Actl 1;
BA_ "U_CX727_MY2021_Rx" SG_ 534 WhlDirRl_D_Actl 1;
BA_ "U_P702_MY2021_Rx" SG_ 534 WhlDirRl_D_Actl 1;
BA_ "U_T6_MCA_MY2020_Rx" SG_ 534 WhlDirRl_D_Actl 1;
BA_ "U_CD542_MY2021_Rx" SG_ 534 WhlDirRl_D_Actl 1;
BA_ "U_U55X_MY2022_Rx" SG_ 534 WhlDirRl_D_Actl 1;
BA_ "U_CD764_MY2022_Rx" SG_ 534 WhlDirRl_D_Actl 1;
BA_ "U_CX727_MY2021_Tx" SG_ 534 WhlDirRl_D_Actl 1;
BA_ "U_P702_MY2021_Tx" SG_ 534 WhlDirRl_D_Actl 1;
BA_ "U_T6_MCA_MY2020_Tx" SG_ 534 WhlDirRl_D_Actl 1;
BA_ "U_CD542_MY2021_Tx" SG_ 534 WhlDirRl_D_Actl 1;
BA_ "U_U55X_MY2022_Tx" SG_ 534 WhlDirRl_D_Actl 1;
BA_ "U_CD764_MY2022_Tx" SG_ 534 WhlDirRl_D_Actl 1;
BA_ "U_CX727_MY2021_Rx" SG_ 534 WhlDirFr_D_Actl 1;
BA_ "U_P702_MY2021_Rx" SG_ 534 WhlDirFr_D_Actl 1;
BA_ "U_T6_MCA_MY2020_Rx" SG_ 534 WhlDirFr_D_Actl 1;
BA_ "U_CD542_MY2021_Rx" SG_ 534 WhlDirFr_D_Actl 1;
BA_ "U_U55X_MY2022_Rx" SG_ 534 WhlDirFr_D_Actl 1;
BA_ "U_CD764_MY2022_Rx" SG_ 534 WhlDirFr_D_Actl 1;
BA_ "U_CX727_MY2021_Tx" SG_ 534 WhlDirFr_D_Actl 1;
BA_ "U_P702_MY2021_Tx" SG_ 534 WhlDirFr_D_Actl 1;
BA_ "U_T6_MCA_MY2020_Tx" SG_ 534 WhlDirFr_D_Actl 1;
BA_ "U_CD542_MY2021_Tx" SG_ 534 WhlDirFr_D_Actl 1;
BA_ "U_U55X_MY2022_Tx" SG_ 534 WhlDirFr_D_Actl 1;
BA_ "U_CD764_MY2022_Tx" SG_ 534 WhlDirFr_D_Actl 1;
BA_ "U_CX727_MY2021_Rx" SG_ 534 WhlDirFl_D_Actl 1;
BA_ "U_P702_MY2021_Rx" SG_ 534 WhlDirFl_D_Actl 1;
BA_ "U_T6_MCA_MY2020_Rx" SG_ 534 WhlDirFl_D_Actl 1;
BA_ "U_CD542_MY2021_Rx" SG_ 534 WhlDirFl_D_Actl 1;
BA_ "U_U55X_MY2022_Rx" SG_ 534 WhlDirFl_D_Actl 1;
BA_ "U_CD764_MY2022_Rx" SG_ 534 WhlDirFl_D_Actl 1;
BA_ "U_CX727_MY2021_Tx" SG_ 534 WhlDirFl_D_Actl 1;
BA_ "U_P702_MY2021_Tx" SG_ 534 WhlDirFl_D_Actl 1;
BA_ "U_T6_MCA_MY2020_Tx" SG_ 534 WhlDirFl_D_Actl 1;
BA_ "U_CD542_MY2021_Tx" SG_ 534 WhlDirFl_D_Actl 1;
BA_ "U_U55X_MY2022_Tx" SG_ 534 WhlDirFl_D_Actl 1;
BA_ "U_CD764_MY2022_Tx" SG_ 534 WhlDirFl_D_Actl 1;
BA_ "U_P702_MY2021_Rx" SG_ 534 WhlRotatRl_No_Cnt 1;
BA_ "U_T6_MCA_MY2020_Rx" SG_ 534 WhlRotatRl_No_Cnt 1;
BA_ "U_CD542_MY2021_Rx" SG_ 534 WhlRotatRl_No_Cnt 1;
BA_ "U_U55X_MY2022_Rx" SG_ 534 WhlRotatRl_No_Cnt 1;
BA_ "U_CD764_MY2022_Rx" SG_ 534 WhlRotatRl_No_Cnt 1;
BA_ "U_CX727_MY2021_Tx" SG_ 534 WhlRotatRl_No_Cnt 1;
BA_ "U_P702_MY2021_Tx" SG_ 534 WhlRotatRl_No_Cnt 1;
BA_ "U_T6_MCA_MY2020_Tx" SG_ 534 WhlRotatRl_No_Cnt 1;
BA_ "U_CD542_MY2021_Tx" SG_ 534 WhlRotatRl_No_Cnt 1;
BA_ "U_U55X_MY2022_Tx" SG_ 534 WhlRotatRl_No_Cnt 1;
BA_ "U_CD764_MY2022_Tx" SG_ 534 WhlRotatRl_No_Cnt 1;
BA_ "U_P702_MY2021_Rx" SG_ 534 WhlRotatFr_No_Cnt 1;
BA_ "U_T6_MCA_MY2020_Rx" SG_ 534 WhlRotatFr_No_Cnt 1;
BA_ "U_CD542_MY2021_Rx" SG_ 534 WhlRotatFr_No_Cnt 1;
BA_ "U_U55X_MY2022_Rx" SG_ 534 WhlRotatFr_No_Cnt 1;
BA_ "U_CD764_MY2022_Rx" SG_ 534 WhlRotatFr_No_Cnt 1;
BA_ "U_CX727_MY2021_Tx" SG_ 534 WhlRotatFr_No_Cnt 1;
BA_ "U_P702_MY2021_Tx" SG_ 534 WhlRotatFr_No_Cnt 1;
BA_ "U_T6_MCA_MY2020_Tx" SG_ 534 WhlRotatFr_No_Cnt 1;
BA_ "U_CD542_MY2021_Tx" SG_ 534 WhlRotatFr_No_Cnt 1;
BA_ "U_U55X_MY2022_Tx" SG_ 534 WhlRotatFr_No_Cnt 1;
BA_ "U_CD764_MY2022_Tx" SG_ 534 WhlRotatFr_No_Cnt 1;
BA_ "U_P702_MY2021_Rx" SG_ 534 WhlRotatFl_No_Cnt 1;
BA_ "U_T6_MCA_MY2020_Rx" SG_ 534 WhlRotatFl_No_Cnt 1;
BA_ "U_CD542_MY2021_Rx" SG_ 534 WhlRotatFl_No_Cnt 1;
BA_ "U_U55X_MY2022_Rx" SG_ 534 WhlRotatFl_No_Cnt 1;
BA_ "U_CD764_MY2022_Rx" SG_ 534 WhlRotatFl_No_Cnt 1;
BA_ "U_CX727_MY2021_Tx" SG_ 534 WhlRotatFl_No_Cnt 1;
BA_ "U_P702_MY2021_Tx" SG_ 534 WhlRotatFl_No_Cnt 1;
BA_ "U_T6_MCA_MY2020_Tx" SG_ 534 WhlRotatFl_No_Cnt 1;
BA_ "U_CD542_MY2021_Tx" SG_ 534 WhlRotatFl_No_Cnt 1;
BA_ "U_U55X_MY2022_Tx" SG_ 534 WhlRotatFl_No_Cnt 1;
BA_ "U_CD764_MY2022_Tx" SG_ 534 WhlRotatFl_No_Cnt 1;
BA_ "U_CX727_MY2021_Rx" SG_ 532 RgenTqFalt_B_Actl 1;
BA_ "U_P702_MY2021_Rx" SG_ 532 RgenTqFalt_B_Actl 1;
BA_ "U_CD542_MY2021_Rx" SG_ 532 RgenTqFalt_B_Actl 1;
BA_ "U_CX727_MY2021_Tx" SG_ 532 RgenTqFalt_B_Actl 1;
BA_ "U_P702_MY2021_Tx" SG_ 532 RgenTqFalt_B_Actl 1;
BA_ "U_T6_MCA_MY2020_Tx" SG_ 532 RgenTqFalt_B_Actl 1;
BA_ "U_CD542_MY2021_Tx" SG_ 532 RgenTqFalt_B_Actl 1;
BA_ "U_U55X_MY2022_Tx" SG_ 532 RgenTqFalt_B_Actl 1;
BA_ "U_CX727_MY2021_Rx" SG_ 532 RgenBrkDynoMde_B_Actl 1;
BA_ "U_P702_MY2021_Rx" SG_ 532 RgenBrkDynoMde_B_Actl 1;
BA_ "U_CD542_MY2021_Rx" SG_ 532 RgenBrkDynoMde_B_Actl 1;
BA_ "U_CX727_MY2021_Tx" SG_ 532 RgenBrkDynoMde_B_Actl 1;
BA_ "U_P702_MY2021_Tx" SG_ 532 RgenBrkDynoMde_B_Actl 1;
BA_ "U_T6_MCA_MY2020_Tx" SG_ 532 RgenBrkDynoMde_B_Actl 1;
BA_ "U_CD542_MY2021_Tx" SG_ 532 RgenBrkDynoMde_B_Actl 1;
BA_ "U_U55X_MY2022_Tx" SG_ 532 RgenBrkDynoMde_B_Actl 1;
BA_ "MetaData" SG_ 532 PrplWhlTqRqMn_No_Cs 1;
BA_ "U_CX727_MY2021_Rx" SG_ 532 PrplWhlTqRqMn_No_Cs 1;
BA_ "U_P702_MY2021_Rx" SG_ 532 PrplWhlTqRqMn_No_Cs 1;
BA_ "U_T6_MCA_MY2020_Rx" SG_ 532 PrplWhlTqRqMn_No_Cs 1;
BA_ "U_CD542_MY2021_Rx" SG_ 532 PrplWhlTqRqMn_No_Cs 1;
BA_ "U_U55X_MY2022_Rx" SG_ 532 PrplWhlTqRqMn_No_Cs 1;
BA_ "U_CD764_MY2022_Rx" SG_ 532 PrplWhlTqRqMn_No_Cs 1;
BA_ "U_CX727_MY2021_Tx" SG_ 532 PrplWhlTqRqMn_No_Cs 1;
BA_ "U_P702_MY2021_Tx" SG_ 532 PrplWhlTqRqMn_No_Cs 1;
BA_ "U_T6_MCA_MY2020_Tx" SG_ 532 PrplWhlTqRqMn_No_Cs 1;
BA_ "U_CD542_MY2021_Tx" SG_ 532 PrplWhlTqRqMn_No_Cs 1;
BA_ "U_U55X_MY2022_Tx" SG_ 532 PrplWhlTqRqMn_No_Cs 1;
BA_ "U_CX727_MY2021_Tx" SG_ 532 PrplWhlRear_Tq_RqMx 1;
BA_ "U_P702_MY2021_Tx" SG_ 532 PrplWhlRear_Tq_RqMx 1;
BA_ "U_T6_MCA_MY2020_Tx" SG_ 532 PrplWhlRear_Tq_RqMx 1;
BA_ "U_CD542_MY2021_Tx" SG_ 532 PrplWhlRear_Tq_RqMx 1;
BA_ "U_U55X_MY2022_Tx" SG_ 532 PrplWhlRear_Tq_RqMx 1;
BA_ "U_CX727_MY2021_Rx" SG_ 532 PrplWhlTot_Tq_RqMn 1;
BA_ "U_P702_MY2021_Rx" SG_ 532 PrplWhlTot_Tq_RqMn 1;
BA_ "U_T6_MCA_MY2020_Rx" SG_ 532 PrplWhlTot_Tq_RqMn 1;
BA_ "U_CD542_MY2021_Rx" SG_ 532 PrplWhlTot_Tq_RqMn 1;
BA_ "U_U55X_MY2022_Rx" SG_ 532 PrplWhlTot_Tq_RqMn 1;
BA_ "U_CD764_MY2022_Rx" SG_ 532 PrplWhlTot_Tq_RqMn 1;
BA_ "U_CX727_MY2021_Tx" SG_ 532 PrplWhlTot_Tq_RqMn 1;
BA_ "U_P702_MY2021_Tx" SG_ 532 PrplWhlTot_Tq_RqMn 1;
BA_ "U_T6_MCA_MY2020_Tx" SG_ 532 PrplWhlTot_Tq_RqMn 1;
BA_ "U_CD542_MY2021_Tx" SG_ 532 PrplWhlTot_Tq_RqMn 1;
BA_ "U_U55X_MY2022_Tx" SG_ 532 PrplWhlTot_Tq_RqMn 1;
BA_ "MetaData" SG_ 532 PrplWhlTqRqMn_No_Cnt 1;
BA_ "U_CX727_MY2021_Rx" SG_ 532 PrplWhlTqRqMn_No_Cnt 1;
BA_ "U_P702_MY2021_Rx" SG_ 532 PrplWhlTqRqMn_No_Cnt 1;
BA_ "U_T6_MCA_MY2020_Rx" SG_ 532 PrplWhlTqRqMn_No_Cnt 1;
BA_ "U_CD542_MY2021_Rx" SG_ 532 PrplWhlTqRqMn_No_Cnt 1;
BA_ "U_U55X_MY2022_Rx" SG_ 532 PrplWhlTqRqMn_No_Cnt 1;
BA_ "U_CD764_MY2022_Rx" SG_ 532 PrplWhlTqRqMn_No_Cnt 1;
BA_ "U_CX727_MY2021_Tx" SG_ 532 PrplWhlTqRqMn_No_Cnt 1;
BA_ "U_P702_MY2021_Tx" SG_ 532 PrplWhlTqRqMn_No_Cnt 1;
BA_ "U_T6_MCA_MY2020_Tx" SG_ 532 PrplWhlTqRqMn_No_Cnt 1;
BA_ "U_CD542_MY2021_Tx" SG_ 532 PrplWhlTqRqMn_No_Cnt 1;
BA_ "U_U55X_MY2022_Tx" SG_ 532 PrplWhlTqRqMn_No_Cnt 1;
BA_ "U_CX727_MY2021_Rx" SG_ 532 PrplWhlRear_Tq_RqMn 1;
BA_ "U_CD542_MY2021_Rx" SG_ 532 PrplWhlRear_Tq_RqMn 1;
BA_ "U_CX727_MY2021_Tx" SG_ 532 PrplWhlRear_Tq_RqMn 1;
BA_ "U_P702_MY2021_Tx" SG_ 532 PrplWhlRear_Tq_RqMn 1;
BA_ "U_T6_MCA_MY2020_Tx" SG_ 532 PrplWhlRear_Tq_RqMn 1;
BA_ "U_CD542_MY2021_Tx" SG_ 532 PrplWhlRear_Tq_RqMn 1;
BA_ "U_U55X_MY2022_Tx" SG_ 532 PrplWhlRear_Tq_RqMn 1;
BA_ "WakeupSignal" SG_ 531 PrkBrkMsgTxt_D_Rq 1;
BA_ "U_CD764_MY2022_Tx" SG_ 531 PrkBrkMsgTxt_D_Rq 1;
BA_ "GenSigStartValueInteger" SG_ 531 VehStop_D_Stat 2;
BA_ "GenSigStartValue" SG_ 531 VehStop_D_Stat 2;
BA_ "U_T6_MCA_MY2020_Rx" SG_ 531 VehStop_D_Stat 1;
BA_ "U_CD542_MY2021_Rx" SG_ 531 VehStop_D_Stat 1;
BA_ "U_U55X_MY2022_Rx" SG_ 531 VehStop_D_Stat 1;
BA_ "U_CD764_MY2022_Rx" SG_ 531 VehStop_D_Stat 1;
BA_ "U_CX727_MY2021_Tx" SG_ 531 VehStop_D_Stat 1;
BA_ "U_P702_MY2021_Tx" SG_ 531 VehStop_D_Stat 1;
BA_ "U_T6_MCA_MY2020_Tx" SG_ 531 VehStop_D_Stat 1;
BA_ "U_CD542_MY2021_Tx" SG_ 531 VehStop_D_Stat 1;
BA_ "U_U55X_MY2022_Tx" SG_ 531 VehStop_D_Stat 1;
BA_ "U_CD764_MY2022_Tx" SG_ 531 VehStop_D_Stat 1;
BA_ "U_CX727_MY2021_Rx" SG_ 531 TracCtlPtActv_B_Actl 1;
BA_ "U_P702_MY2021_Rx" SG_ 531 TracCtlPtActv_B_Actl 1;
BA_ "U_T6_MCA_MY2020_Rx" SG_ 531 TracCtlPtActv_B_Actl 1;
BA_ "ECGUsedRxSignal" SG_ 531 TracCtlPtActv_B_Actl 1;
BA_ "U_CD542_MY2021_Rx" SG_ 531 TracCtlPtActv_B_Actl 1;
BA_ "U_U55X_MY2022_Rx" SG_ 531 TracCtlPtActv_B_Actl 1;
BA_ "U_CD764_MY2022_Rx" SG_ 531 TracCtlPtActv_B_Actl 1;
BA_ "U_CX727_MY2021_Tx" SG_ 531 TracCtlPtActv_B_Actl 1;
BA_ "U_P702_MY2021_Tx" SG_ 531 TracCtlPtActv_B_Actl 1;
BA_ "U_T6_MCA_MY2020_Tx" SG_ 531 TracCtlPtActv_B_Actl 1;
BA_ "U_CD542_MY2021_Tx" SG_ 531 TracCtlPtActv_B_Actl 1;
BA_ "U_U55X_MY2022_Tx" SG_ 531 TracCtlPtActv_B_Actl 1;
BA_ "U_CD764_MY2022_Tx" SG_ 531 TracCtlPtActv_B_Actl 1;
BA_ "U_T6_MCA_MY2020_Rx" SG_ 531 VehicleStationary 1;
BA_ "U_CX727_MY2021_Tx" SG_ 531 VehicleStationary 1;
BA_ "U_T6_MCA_MY2020_Tx" SG_ 531 VehicleStationary 1;
BA_ "U_CD542_MY2021_Tx" SG_ 531 VehicleStationary 1;
BA_ "U_CD764_MY2022_Tx" SG_ 531 VehicleStationary 1;
BA_ "U_CX727_MY2021_Rx" SG_ 531 AbsActv_B_Actl 1;
BA_ "U_P702_MY2021_Rx" SG_ 531 AbsActv_B_Actl 1;
BA_ "U_T6_MCA_MY2020_Rx" SG_ 531 AbsActv_B_Actl 1;
BA_ "U_CD542_MY2021_Rx" SG_ 531 AbsActv_B_Actl 1;
BA_ "U_U55X_MY2022_Rx" SG_ 531 AbsActv_B_Actl 1;
BA_ "U_CD764_MY2022_Rx" SG_ 531 AbsActv_B_Actl 1;
BA_ "U_CX727_MY2021_Tx" SG_ 531 AbsActv_B_Actl 1;
BA_ "U_P702_MY2021_Tx" SG_ 531 AbsActv_B_Actl 1;
BA_ "U_T6_MCA_MY2020_Tx" SG_ 531 AbsActv_B_Actl 1;
BA_ "U_CD542_MY2021_Tx" SG_ 531 AbsActv_B_Actl 1;
BA_ "U_U55X_MY2022_Tx" SG_ 531 AbsActv_B_Actl 1;
BA_ "U_CD764_MY2022_Tx" SG_ 531 AbsActv_B_Actl 1;
BA_ "U_CX727_MY2021_Rx" SG_ 531 StabCtlBrkActv_B_Actl 1;
BA_ "U_P702_MY2021_Rx" SG_ 531 StabCtlBrkActv_B_Actl 1;
BA_ "U_T6_MCA_MY2020_Rx" SG_ 531 StabCtlBrkActv_B_Actl 1;
BA_ "ECGUsedRxSignal" SG_ 531 StabCtlBrkActv_B_Actl 1;
BA_ "U_CD542_MY2021_Rx" SG_ 531 StabCtlBrkActv_B_Actl 1;
BA_ "U_U55X_MY2022_Rx" SG_ 531 StabCtlBrkActv_B_Actl 1;
BA_ "U_CD764_MY2022_Rx" SG_ 531 StabCtlBrkActv_B_Actl 1;
BA_ "U_CX727_MY2021_Tx" SG_ 531 StabCtlBrkActv_B_Actl 1;
BA_ "U_P702_MY2021_Tx" SG_ 531 StabCtlBrkActv_B_Actl 1;
BA_ "U_T6_MCA_MY2020_Tx" SG_ 531 StabCtlBrkActv_B_Actl 1;
BA_ "U_CD542_MY2021_Tx" SG_ 531 StabCtlBrkActv_B_Actl 1;
BA_ "U_U55X_MY2022_Tx" SG_ 531 StabCtlBrkActv_B_Actl 1;
BA_ "U_CD764_MY2022_Tx" SG_ 531 StabCtlBrkActv_B_Actl 1;
BA_ "U_T6_MCA_MY2020_Rx" SG_ 531 CmbbBrkPrchg_B_Actl 1;
BA_ "U_CD542_MY2021_Rx" SG_ 531 CmbbBrkPrchg_B_Actl 1;
BA_ "U_U55X_MY2022_Rx" SG_ 531 CmbbBrkPrchg_B_Actl 1;
BA_ "U_CD764_MY2022_Rx" SG_ 531 CmbbBrkPrchg_B_Actl 1;
BA_ "U_CX727_MY2021_Tx" SG_ 531 CmbbBrkPrchg_B_Actl 1;
BA_ "U_P702_MY2021_Tx" SG_ 531 CmbbBrkPrchg_B_Actl 1;
BA_ "U_T6_MCA_MY2020_Tx" SG_ 531 CmbbBrkPrchg_B_Actl 1;
BA_ "U_CD542_MY2021_Tx" SG_ 531 CmbbBrkPrchg_B_Actl 1;
BA_ "U_U55X_MY2022_Tx" SG_ 531 CmbbBrkPrchg_B_Actl 1;
BA_ "U_CD764_MY2022_Tx" SG_ 531 CmbbBrkPrchg_B_Actl 1;
BA_ "U_T6_MCA_MY2020_Rx" SG_ 531 CmbbBrkDecel_B_Actl 1;
BA_ "U_CD542_MY2021_Rx" SG_ 531 CmbbBrkDecel_B_Actl 1;
BA_ "U_U55X_MY2022_Rx" SG_ 531 CmbbBrkDecel_B_Actl 1;
BA_ "U_CD764_MY2022_Rx" SG_ 531 CmbbBrkDecel_B_Actl 1;
BA_ "U_CX727_MY2021_Tx" SG_ 531 CmbbBrkDecel_B_Actl 1;
BA_ "U_P702_MY2021_Tx" SG_ 531 CmbbBrkDecel_B_Actl 1;
BA_ "U_T6_MCA_MY2020_Tx" SG_ 531 CmbbBrkDecel_B_Actl 1;
BA_ "U_CD542_MY2021_Tx" SG_ 531 CmbbBrkDecel_B_Actl 1;
BA_ "U_U55X_MY2022_Tx" SG_ 531 CmbbBrkDecel_B_Actl 1;
BA_ "U_CD764_MY2022_Tx" SG_ 531 CmbbBrkDecel_B_Actl 1;
BA_ "U_T6_MCA_MY2020_Rx" SG_ 531 CmbbBaSensInc_B_Actl 1;
BA_ "U_CD542_MY2021_Rx" SG_ 531 CmbbBaSensInc_B_Actl 1;
BA_ "U_U55X_MY2022_Rx" SG_ 531 CmbbBaSensInc_B_Actl 1;
BA_ "U_CD764_MY2022_Rx" SG_ 531 CmbbBaSensInc_B_Actl 1;
BA_ "U_CX727_MY2021_Tx" SG_ 531 CmbbBaSensInc_B_Actl 1;
BA_ "U_P702_MY2021_Tx" SG_ 531 CmbbBaSensInc_B_Actl 1;
BA_ "U_T6_MCA_MY2020_Tx" SG_ 531 CmbbBaSensInc_B_Actl 1;
BA_ "U_CD542_MY2021_Tx" SG_ 531 CmbbBaSensInc_B_Actl 1;
BA_ "U_U55X_MY2022_Tx" SG_ 531 CmbbBaSensInc_B_Actl 1;
BA_ "U_CD764_MY2022_Tx" SG_ 531 CmbbBaSensInc_B_Actl 1;
BA_ "U_T6_MCA_MY2020_Rx" SG_ 531 AccBrkWarm_B_Actl 1;
BA_ "U_CD542_MY2021_Rx" SG_ 531 AccBrkWarm_B_Actl 1;
BA_ "U_U55X_MY2022_Rx" SG_ 531 AccBrkWarm_B_Actl 1;
BA_ "U_CD764_MY2022_Rx" SG_ 531 AccBrkWarm_B_Actl 1;
BA_ "U_CX727_MY2021_Tx" SG_ 531 AccBrkWarm_B_Actl 1;
BA_ "U_P702_MY2021_Tx" SG_ 531 AccBrkWarm_B_Actl 1;
BA_ "U_T6_MCA_MY2020_Tx" SG_ 531 AccBrkWarm_B_Actl 1;
BA_ "U_CD542_MY2021_Tx" SG_ 531 AccBrkWarm_B_Actl 1;
BA_ "U_U55X_MY2022_Tx" SG_ 531 AccBrkWarm_B_Actl 1;
BA_ "U_CD764_MY2022_Tx" SG_ 531 AccBrkWarm_B_Actl 1;
BA_ "U_T6_MCA_MY2020_Rx" SG_ 531 AccBrkTotTqMn_B_Actl 1;
BA_ "U_CD542_MY2021_Rx" SG_ 531 AccBrkTotTqMn_B_Actl 1;
BA_ "U_U55X_MY2022_Rx" SG_ 531 AccBrkTotTqMn_B_Actl 1;
BA_ "U_CD764_MY2022_Rx" SG_ 531 AccBrkTotTqMn_B_Actl 1;
BA_ "U_CX727_MY2021_Tx" SG_ 531 AccBrkTotTqMn_B_Actl 1;
BA_ "U_P702_MY2021_Tx" SG_ 531 AccBrkTotTqMn_B_Actl 1;
BA_ "U_T6_MCA_MY2020_Tx" SG_ 531 AccBrkTotTqMn_B_Actl 1;
BA_ "U_CD542_MY2021_Tx" SG_ 531 AccBrkTotTqMn_B_Actl 1;
BA_ "U_U55X_MY2022_Tx" SG_ 531 AccBrkTotTqMn_B_Actl 1;
BA_ "U_CD764_MY2022_Tx" SG_ 531 AccBrkTotTqMn_B_Actl 1;
BA_ "U_T6_MCA_MY2020_Rx" SG_ 531 AccBrkPrchgActv_B_Actl 1;
BA_ "U_CD542_MY2021_Rx" SG_ 531 AccBrkPrchgActv_B_Actl 1;
BA_ "U_U55X_MY2022_Rx" SG_ 531 AccBrkPrchgActv_B_Actl 1;
BA_ "U_CD764_MY2022_Rx" SG_ 531 AccBrkPrchgActv_B_Actl 1;
BA_ "U_CX727_MY2021_Tx" SG_ 531 AccBrkPrchgActv_B_Actl 1;
BA_ "U_P702_MY2021_Tx" SG_ 531 AccBrkPrchgActv_B_Actl 1;
BA_ "U_T6_MCA_MY2020_Tx" SG_ 531 AccBrkPrchgActv_B_Actl 1;
BA_ "U_CD542_MY2021_Tx" SG_ 531 AccBrkPrchgActv_B_Actl 1;
BA_ "U_U55X_MY2022_Tx" SG_ 531 AccBrkPrchgActv_B_Actl 1;
BA_ "U_CD764_MY2022_Tx" SG_ 531 AccBrkPrchgActv_B_Actl 1;
BA_ "U_T6_MCA_MY2020_Rx" SG_ 531 AccBrkDis_B_Actl 1;
BA_ "U_CD542_MY2021_Rx" SG_ 531 AccBrkDis_B_Actl 1;
BA_ "U_U55X_MY2022_Rx" SG_ 531 AccBrkDis_B_Actl 1;
BA_ "U_CD764_MY2022_Rx" SG_ 531 AccBrkDis_B_Actl 1;
BA_ "U_CX727_MY2021_Tx" SG_ 531 AccBrkDis_B_Actl 1;
BA_ "U_P702_MY2021_Tx" SG_ 531 AccBrkDis_B_Actl 1;
BA_ "U_T6_MCA_MY2020_Tx" SG_ 531 AccBrkDis_B_Actl 1;
BA_ "U_CD542_MY2021_Tx" SG_ 531 AccBrkDis_B_Actl 1;
BA_ "U_U55X_MY2022_Tx" SG_ 531 AccBrkDis_B_Actl 1;
BA_ "U_CD764_MY2022_Tx" SG_ 531 AccBrkDis_B_Actl 1;
BA_ "U_CX727_MY2021_Rx" SG_ 531 AccBrkDeny_B_Actl 1;
BA_ "U_P702_MY2021_Rx" SG_ 531 AccBrkDeny_B_Actl 1;
BA_ "U_T6_MCA_MY2020_Rx" SG_ 531 AccBrkDeny_B_Actl 1;
BA_ "U_CD542_MY2021_Rx" SG_ 531 AccBrkDeny_B_Actl 1;
BA_ "U_U55X_MY2022_Rx" SG_ 531 AccBrkDeny_B_Actl 1;
BA_ "U_CD764_MY2022_Rx" SG_ 531 AccBrkDeny_B_Actl 1;
BA_ "U_CX727_MY2021_Tx" SG_ 531 AccBrkDeny_B_Actl 1;
BA_ "U_P702_MY2021_Tx" SG_ 531 AccBrkDeny_B_Actl 1;
BA_ "U_T6_MCA_MY2020_Tx" SG_ 531 AccBrkDeny_B_Actl 1;
BA_ "U_CD542_MY2021_Tx" SG_ 531 AccBrkDeny_B_Actl 1;
BA_ "U_U55X_MY2022_Tx" SG_ 531 AccBrkDeny_B_Actl 1;
BA_ "U_CD764_MY2022_Tx" SG_ 531 AccBrkDeny_B_Actl 1;
BA_ "U_P702_MY2021_Rx" SG_ 531 AccBrkActv_B_Actl 1;
BA_ "U_T6_MCA_MY2020_Rx" SG_ 531 AccBrkActv_B_Actl 1;
BA_ "U_CD542_MY2021_Rx" SG_ 531 AccBrkActv_B_Actl 1;
BA_ "U_U55X_MY2022_Rx" SG_ 531 AccBrkActv_B_Actl 1;
BA_ "U_CD764_MY2022_Rx" SG_ 531 AccBrkActv_B_Actl 1;
BA_ "U_CX727_MY2021_Tx" SG_ 531 AccBrkActv_B_Actl 1;
BA_ "U_P702_MY2021_Tx" SG_ 531 AccBrkActv_B_Actl 1;
BA_ "U_T6_MCA_MY2020_Tx" SG_ 531 AccBrkActv_B_Actl 1;
BA_ "U_CD542_MY2021_Tx" SG_ 531 AccBrkActv_B_Actl 1;
BA_ "U_U55X_MY2022_Tx" SG_ 531 AccBrkActv_B_Actl 1;
BA_ "U_CD764_MY2022_Tx" SG_ 531 AccBrkActv_B_Actl 1;
BA_ "U_CX727_MY2021_Rx" SG_ 531 PrplDrgCtlActv_B_Actl 1;
BA_ "U_P702_MY2021_Rx" SG_ 531 PrplDrgCtlActv_B_Actl 1;
BA_ "U_T6_MCA_MY2020_Rx" SG_ 531 PrplDrgCtlActv_B_Actl 1;
BA_ "U_CD542_MY2021_Rx" SG_ 531 PrplDrgCtlActv_B_Actl 1;
BA_ "U_U55X_MY2022_Rx" SG_ 531 PrplDrgCtlActv_B_Actl 1;
BA_ "U_CD764_MY2022_Rx" SG_ 531 PrplDrgCtlActv_B_Actl 1;
BA_ "U_CX727_MY2021_Tx" SG_ 531 PrplDrgCtlActv_B_Actl 1;
BA_ "U_P702_MY2021_Tx" SG_ 531 PrplDrgCtlActv_B_Actl 1;
BA_ "U_T6_MCA_MY2020_Tx" SG_ 531 PrplDrgCtlActv_B_Actl 1;
BA_ "U_CD542_MY2021_Tx" SG_ 531 PrplDrgCtlActv_B_Actl 1;
BA_ "U_U55X_MY2022_Tx" SG_ 531 PrplDrgCtlActv_B_Actl 1;
BA_ "U_CD764_MY2022_Tx" SG_ 531 PrplDrgCtlActv_B_Actl 1;
BA_ "U_CX727_MY2021_Rx" SG_ 531 PrplWhlTot_Tq_RqMx 1;
BA_ "U_P702_MY2021_Rx" SG_ 531 PrplWhlTot_Tq_RqMx 1;
BA_ "U_T6_MCA_MY2020_Rx" SG_ 531 PrplWhlTot_Tq_RqMx 1;
BA_ "U_CD542_MY2021_Rx" SG_ 531 PrplWhlTot_Tq_RqMx 1;
BA_ "U_U55X_MY2022_Rx" SG_ 531 PrplWhlTot_Tq_RqMx 1;
BA_ "U_CD764_MY2022_Rx" SG_ 531 PrplWhlTot_Tq_RqMx 1;
BA_ "U_CX727_MY2021_Tx" SG_ 531 PrplWhlTot_Tq_RqMx 1;
BA_ "U_P702_MY2021_Tx" SG_ 531 PrplWhlTot_Tq_RqMx 1;
BA_ "U_T6_MCA_MY2020_Tx" SG_ 531 PrplWhlTot_Tq_RqMx 1;
BA_ "U_CD542_MY2021_Tx" SG_ 531 PrplWhlTot_Tq_RqMx 1;
BA_ "U_U55X_MY2022_Tx" SG_ 531 PrplWhlTot_Tq_RqMx 1;
BA_ "U_CD764_MY2022_Tx" SG_ 531 PrplWhlTot_Tq_RqMx 1;
BA_ "U_CX727_MY2021_Rx" SG_ 531 CmbbBrkDis_B_Actl 1;
BA_ "U_P702_MY2021_Rx" SG_ 531 CmbbBrkDis_B_Actl 1;
BA_ "U_T6_MCA_MY2020_Rx" SG_ 531 CmbbBrkDis_B_Actl 1;
BA_ "U_CD542_MY2021_Rx" SG_ 531 CmbbBrkDis_B_Actl 1;
BA_ "U_U55X_MY2022_Rx" SG_ 531 CmbbBrkDis_B_Actl 1;
BA_ "U_CD764_MY2022_Rx" SG_ 531 CmbbBrkDis_B_Actl 1;
BA_ "U_CX727_MY2021_Tx" SG_ 531 CmbbBrkDis_B_Actl 1;
BA_ "U_P702_MY2021_Tx" SG_ 531 CmbbBrkDis_B_Actl 1;
BA_ "U_T6_MCA_MY2020_Tx" SG_ 531 CmbbBrkDis_B_Actl 1;
BA_ "U_CD542_MY2021_Tx" SG_ 531 CmbbBrkDis_B_Actl 1;
BA_ "U_U55X_MY2022_Tx" SG_ 531 CmbbBrkDis_B_Actl 1;
BA_ "U_CD764_MY2022_Tx" SG_ 531 CmbbBrkDis_B_Actl 1;
BA_ "U_CX727_MY2021_Rx" SG_ 531 CmbbDeny_B_ActlBrk 1;
BA_ "U_P702_MY2021_Rx" SG_ 531 CmbbDeny_B_ActlBrk 1;
BA_ "U_T6_MCA_MY2020_Rx" SG_ 531 CmbbDeny_B_ActlBrk 1;
BA_ "U_CD542_MY2021_Rx" SG_ 531 CmbbDeny_B_ActlBrk 1;
BA_ "U_U55X_MY2022_Rx" SG_ 531 CmbbDeny_B_ActlBrk 1;
BA_ "U_CD764_MY2022_Rx" SG_ 531 CmbbDeny_B_ActlBrk 1;
BA_ "U_CX727_MY2021_Tx" SG_ 531 CmbbDeny_B_ActlBrk 1;
BA_ "U_P702_MY2021_Tx" SG_ 531 CmbbDeny_B_ActlBrk 1;
BA_ "U_T6_MCA_MY2020_Tx" SG_ 531 CmbbDeny_B_ActlBrk 1;
BA_ "U_CD542_MY2021_Tx" SG_ 531 CmbbDeny_B_ActlBrk 1;
BA_ "U_U55X_MY2022_Tx" SG_ 531 CmbbDeny_B_ActlBrk 1;
BA_ "U_CD764_MY2022_Tx" SG_ 531 CmbbDeny_B_ActlBrk 1;
BA_ "U_CX727_MY2021_Rx" SG_ 531 CcDis_B_Cmd 1;
BA_ "U_P702_MY2021_Rx" SG_ 531 CcDis_B_Cmd 1;
BA_ "U_T6_MCA_MY2020_Rx" SG_ 531 CcDis_B_Cmd 1;
BA_ "U_CD542_MY2021_Rx" SG_ 531 CcDis_B_Cmd 1;
BA_ "U_U55X_MY2022_Rx" SG_ 531 CcDis_B_Cmd 1;
BA_ "U_CD764_MY2022_Rx" SG_ 531 CcDis_B_Cmd 1;
BA_ "U_CX727_MY2021_Tx" SG_ 531 CcDis_B_Cmd 1;
BA_ "U_P702_MY2021_Tx" SG_ 531 CcDis_B_Cmd 1;
BA_ "U_T6_MCA_MY2020_Tx" SG_ 531 CcDis_B_Cmd 1;
BA_ "U_CD542_MY2021_Tx" SG_ 531 CcDis_B_Cmd 1;
BA_ "U_U55X_MY2022_Tx" SG_ 531 CcDis_B_Cmd 1;
BA_ "U_CD764_MY2022_Tx" SG_ 531 CcDis_B_Cmd 1;
BA_ "GenSigStartValueInteger" SG_ 531 VehLongOvrGnd_A_Est 511;
BA_ "U_P702_MY2021_Rx" SG_ 531 VehLongOvrGnd_A_Est 1;
BA_ "U_T6_MCA_MY2020_Rx" SG_ 531 VehLongOvrGnd_A_Est 1;
BA_ "U_CD542_MY2021_Rx" SG_ 531 VehLongOvrGnd_A_Est 1;
BA_ "U_U55X_MY2022_Rx" SG_ 531 VehLongOvrGnd_A_Est 1;
BA_ "U_CD764_MY2022_Rx" SG_ 531 VehLongOvrGnd_A_Est 1;
BA_ "U_CX727_MY2021_Tx" SG_ 531 VehLongOvrGnd_A_Est 1;
BA_ "U_P702_MY2021_Tx" SG_ 531 VehLongOvrGnd_A_Est 1;
BA_ "U_T6_MCA_MY2020_Tx" SG_ 531 VehLongOvrGnd_A_Est 1;
BA_ "U_CD542_MY2021_Tx" SG_ 531 VehLongOvrGnd_A_Est 1;
BA_ "U_U55X_MY2022_Tx" SG_ 531 VehLongOvrGnd_A_Est 1;
BA_ "U_CD764_MY2022_Tx" SG_ 531 VehLongOvrGnd_A_Est 1;
BA_ "U_CX727_MY2021_Rx" SG_ 531 AccStopActv_B_ActlBrk 1;
BA_ "U_P702_MY2021_Rx" SG_ 531 AccStopActv_B_ActlBrk 1;
BA_ "U_T6_MCA_MY2020_Rx" SG_ 531 AccStopActv_B_ActlBrk 1;
BA_ "U_CD542_MY2021_Rx" SG_ 531 AccStopActv_B_ActlBrk 1;
BA_ "U_U55X_MY2022_Rx" SG_ 531 AccStopActv_B_ActlBrk 1;
BA_ "U_CD764_MY2022_Rx" SG_ 531 AccStopActv_B_ActlBrk 1;
BA_ "U_CX727_MY2021_Tx" SG_ 531 AccStopActv_B_ActlBrk 1;
BA_ "U_P702_MY2021_Tx" SG_ 531 AccStopActv_B_ActlBrk 1;
BA_ "U_T6_MCA_MY2020_Tx" SG_ 531 AccStopActv_B_ActlBrk 1;
BA_ "U_CD542_MY2021_Tx" SG_ 531 AccStopActv_B_ActlBrk 1;
BA_ "U_U55X_MY2022_Tx" SG_ 531 AccStopActv_B_ActlBrk 1;
BA_ "U_CD764_MY2022_Tx" SG_ 531 AccStopActv_B_ActlBrk 1;
BA_ "U_T6_MCA_MY2020_Rx" SG_ 531 AccDis_B_ActlEpb 1;
BA_ "U_CD542_MY2021_Rx" SG_ 531 AccDis_B_ActlEpb 1;
BA_ "U_U55X_MY2022_Rx" SG_ 531 AccDis_B_ActlEpb 1;
BA_ "U_CD764_MY2022_Rx" SG_ 531 AccDis_B_ActlEpb 1;
BA_ "U_CX727_MY2021_Tx" SG_ 531 AccDis_B_ActlEpb 1;
BA_ "U_P702_MY2021_Tx" SG_ 531 AccDis_B_ActlEpb 1;
BA_ "U_T6_MCA_MY2020_Tx" SG_ 531 AccDis_B_ActlEpb 1;
BA_ "U_CD542_MY2021_Tx" SG_ 531 AccDis_B_ActlEpb 1;
BA_ "U_U55X_MY2022_Tx" SG_ 531 AccDis_B_ActlEpb 1;
BA_ "U_CD764_MY2022_Tx" SG_ 531 AccDis_B_ActlEpb 1;
BA_ "GenSigStartValueInteger" SG_ 531 PrkBrkStatus 7;
BA_ "GenSigStartValue" SG_ 531 PrkBrkStatus 7;
BA_ "U_CX727_MY2021_Rx" SG_ 531 PrkBrkStatus 1;
BA_ "U_P702_MY2021_Rx" SG_ 531 PrkBrkStatus 1;
BA_ "U_T6_MCA_MY2020_Rx" SG_ 531 PrkBrkStatus 1;
BA_ "ECGUsedRxSignal" SG_ 531 PrkBrkStatus 1;
BA_ "U_CD542_MY2021_Rx" SG_ 531 PrkBrkStatus 1;
BA_ "U_U55X_MY2022_Rx" SG_ 531 PrkBrkStatus 1;
BA_ "U_CD764_MY2022_Rx" SG_ 531 PrkBrkStatus 1;
BA_ "U_CX727_MY2021_Tx" SG_ 531 PrkBrkStatus 1;
BA_ "U_P702_MY2021_Tx" SG_ 531 PrkBrkStatus 1;
BA_ "U_T6_MCA_MY2020_Tx" SG_ 531 PrkBrkStatus 1;
BA_ "U_CD542_MY2021_Tx" SG_ 531 PrkBrkStatus 1;
BA_ "U_U55X_MY2022_Tx" SG_ 531 PrkBrkStatus 1;
BA_ "U_CD764_MY2022_Tx" SG_ 531 PrkBrkStatus 1;
BA_ "WakeupSignal" SG_ 531 PrkBrkYwLamp_D_Rq 1;
BA_ "U_CD764_MY2022_Tx" SG_ 531 PrkBrkYwLamp_D_Rq 1;
BA_ "WakeupSignal" SG_ 531 PrkBrkRedLamp_D_Rq 1;
BA_ "U_CD764_MY2022_Tx" SG_ 531 PrkBrkRedLamp_D_Rq 1;
BA_ "GenSigStartValueInteger" SG_ 127 AwdLckRgen_Tq_RqMn 4095;
BA_ "U_CX727_MY2021_Rx" SG_ 127 AwdLckRgen_Tq_RqMn 1;
BA_ "U_T6_MCA_MY2020_Tx" SG_ 127 AwdLckRgen_Tq_RqMn 1;
BA_ "U_T6_MCA_MY2020_Rx" SG_ 127 AwdLck_Tq_RqMx 1;
BA_ "U_U55X_MY2022_Rx" SG_ 127 AwdLck_Tq_RqMx 1;
BA_ "U_T6_MCA_MY2020_Tx" SG_ 127 AwdLck_Tq_RqMx 1;
BA_ "U_U55X_MY2022_Tx" SG_ 127 AwdLck_Tq_RqMx 1;
BA_ "U_T6_MCA_MY2020_Rx" SG_ 127 AwdLck_Tq_RqMn 1;
BA_ "U_U55X_MY2022_Rx" SG_ 127 AwdLck_Tq_RqMn 1;
BA_ "U_T6_MCA_MY2020_Tx" SG_ 127 AwdLck_Tq_RqMn 1;
BA_ "U_U55X_MY2022_Tx" SG_ 127 AwdLck_Tq_RqMn 1;
BA_ "GenSigStartValueInteger" SG_ 125 VehRolComp_W_Actl 4094;
BA_ "GenSigStartValue" SG_ 125 VehRolComp_W_Actl 4094;
BA_ "U_T6_MCA_MY2020_Rx" SG_ 125 VehRolComp_W_Actl 1;
BA_ "U_U55X_MY2022_Rx" SG_ 125 VehRolComp_W_Actl 1;
BA_ "U_CX727_MY2021_Tx" SG_ 125 VehRolComp_W_Actl 1;
BA_ "U_P702_MY2021_Tx" SG_ 125 VehRolComp_W_Actl 1;
BA_ "U_T6_MCA_MY2020_Tx" SG_ 125 VehRolComp_W_Actl 1;
BA_ "U_CD542_MY2021_Tx" SG_ 125 VehRolComp_W_Actl 1;
BA_ "U_U55X_MY2022_Tx" SG_ 125 VehRolComp_W_Actl 1;
BA_ "U_CD764_MY2022_Tx" SG_ 125 VehRolComp_W_Actl 1;
BA_ "GenSigStartValueInteger" SG_ 125 VehVertComp_A_Actl 1022;
BA_ "GenSigStartValue" SG_ 125 VehVertComp_A_Actl 1022;
BA_ "U_P702_MY2021_Rx" SG_ 125 VehVertComp_A_Actl 1;
BA_ "U_T6_MCA_MY2020_Rx" SG_ 125 VehVertComp_A_Actl 1;
BA_ "U_U55X_MY2022_Rx" SG_ 125 VehVertComp_A_Actl 1;
BA_ "U_CX727_MY2021_Tx" SG_ 125 VehVertComp_A_Actl 1;
BA_ "U_P702_MY2021_Tx" SG_ 125 VehVertComp_A_Actl 1;
BA_ "U_T6_MCA_MY2020_Tx" SG_ 125 VehVertComp_A_Actl 1;
BA_ "U_CD542_MY2021_Tx" SG_ 125 VehVertComp_A_Actl 1;
BA_ "U_U55X_MY2022_Tx" SG_ 125 VehVertComp_A_Actl 1;
BA_ "U_CD764_MY2022_Tx" SG_ 125 VehVertComp_A_Actl 1;
BA_ "MetaData" SG_ 125 BrkTotTqRqArb_No_Cs 1;
BA_ "U_CX727_MY2021_Rx" SG_ 125 BrkTotTqRqArb_No_Cs 1;
BA_ "U_P702_MY2021_Rx" SG_ 125 BrkTotTqRqArb_No_Cs 1;
BA_ "U_T6_MCA_MY2020_Rx" SG_ 125 BrkTotTqRqArb_No_Cs 1;
BA_ "U_CD542_MY2021_Rx" SG_ 125 BrkTotTqRqArb_No_Cs 1;
BA_ "U_U55X_MY2022_Rx" SG_ 125 BrkTotTqRqArb_No_Cs 1;
BA_ "U_CD764_MY2022_Rx" SG_ 125 BrkTotTqRqArb_No_Cs 1;
BA_ "U_CX727_MY2021_Tx" SG_ 125 BrkTotTqRqArb_No_Cs 1;
BA_ "U_P702_MY2021_Tx" SG_ 125 BrkTotTqRqArb_No_Cs 1;
BA_ "U_T6_MCA_MY2020_Tx" SG_ 125 BrkTotTqRqArb_No_Cs 1;
BA_ "U_CD542_MY2021_Tx" SG_ 125 BrkTotTqRqArb_No_Cs 1;
BA_ "U_U55X_MY2022_Tx" SG_ 125 BrkTotTqRqArb_No_Cs 1;
BA_ "U_CD764_MY2022_Tx" SG_ 125 BrkTotTqRqArb_No_Cs 1;
BA_ "MetaData" SG_ 125 BrkTotTqRqArb_No_Cnt 1;
BA_ "U_CX727_MY2021_Rx" SG_ 125 BrkTotTqRqArb_No_Cnt 1;
BA_ "U_P702_MY2021_Rx" SG_ 125 BrkTotTqRqArb_No_Cnt 1;
BA_ "U_T6_MCA_MY2020_Rx" SG_ 125 BrkTotTqRqArb_No_Cnt 1;
BA_ "U_CD542_MY2021_Rx" SG_ 125 BrkTotTqRqArb_No_Cnt 1;
BA_ "U_U55X_MY2022_Rx" SG_ 125 BrkTotTqRqArb_No_Cnt 1;
BA_ "U_CD764_MY2022_Rx" SG_ 125 BrkTotTqRqArb_No_Cnt 1;
BA_ "U_CX727_MY2021_Tx" SG_ 125 BrkTotTqRqArb_No_Cnt 1;
BA_ "U_P702_MY2021_Tx" SG_ 125 BrkTotTqRqArb_No_Cnt 1;
BA_ "U_T6_MCA_MY2020_Tx" SG_ 125 BrkTotTqRqArb_No_Cnt 1;
BA_ "U_CD542_MY2021_Tx" SG_ 125 BrkTotTqRqArb_No_Cnt 1;
BA_ "U_U55X_MY2022_Tx" SG_ 125 BrkTotTqRqArb_No_Cnt 1;
BA_ "U_CD764_MY2022_Tx" SG_ 125 BrkTotTqRqArb_No_Cnt 1;
BA_ "U_CX727_MY2021_Rx" SG_ 125 BrkTot_Tq_RqArb 1;
BA_ "U_P702_MY2021_Rx" SG_ 125 BrkTot_Tq_RqArb 1;
BA_ "U_T6_MCA_MY2020_Rx" SG_ 125 BrkTot_Tq_RqArb 1;
BA_ "ECGUsedRxSignal" SG_ 125 BrkTot_Tq_RqArb 1;
BA_ "U_CD542_MY2021_Rx" SG_ 125 BrkTot_Tq_RqArb 1;
BA_ "U_U55X_MY2022_Rx" SG_ 125 BrkTot_Tq_RqArb 1;
BA_ "U_CD764_MY2022_Rx" SG_ 125 BrkTot_Tq_RqArb 1;
BA_ "U_CX727_MY2021_Tx" SG_ 125 BrkTot_Tq_RqArb 1;
BA_ "U_P702_MY2021_Tx" SG_ 125 BrkTot_Tq_RqArb 1;
BA_ "U_T6_MCA_MY2020_Tx" SG_ 125 BrkTot_Tq_RqArb 1;
BA_ "U_CD542_MY2021_Tx" SG_ 125 BrkTot_Tq_RqArb 1;
BA_ "U_U55X_MY2022_Tx" SG_ 125 BrkTot_Tq_RqArb 1;
BA_ "U_CD764_MY2022_Tx" SG_ 125 BrkTot_Tq_RqArb 1;
BA_ "U_CX727_MY2021_Rx" SG_ 125 BrkTot_Tq_Actl 1;
BA_ "U_P702_MY2021_Rx" SG_ 125 BrkTot_Tq_Actl 1;
BA_ "U_T6_MCA_MY2020_Rx" SG_ 125 BrkTot_Tq_Actl 1;
BA_ "U_CD542_MY2021_Rx" SG_ 125 BrkTot_Tq_Actl 1;
BA_ "U_U55X_MY2022_Rx" SG_ 125 BrkTot_Tq_Actl 1;
BA_ "U_CD764_MY2022_Rx" SG_ 125 BrkTot_Tq_Actl 1;
BA_ "U_CX727_MY2021_Tx" SG_ 125 BrkTot_Tq_Actl 1;
BA_ "U_P702_MY2021_Tx" SG_ 125 BrkTot_Tq_Actl 1;
BA_ "U_T6_MCA_MY2020_Tx" SG_ 125 BrkTot_Tq_Actl 1;
BA_ "U_CD542_MY2021_Tx" SG_ 125 BrkTot_Tq_Actl 1;
BA_ "U_U55X_MY2022_Tx" SG_ 125 BrkTot_Tq_Actl 1;
BA_ "U_CD764_MY2022_Tx" SG_ 125 BrkTot_Tq_Actl 1;
BA_ "U_CX727_MY2021_Rx" SG_ 125 HsaStat_D_Actl 1;
BA_ "U_P702_MY2021_Rx" SG_ 125 HsaStat_D_Actl 1;
BA_ "U_T6_MCA_MY2020_Rx" SG_ 125 HsaStat_D_Actl 1;
BA_ "U_CD542_MY2021_Rx" SG_ 125 HsaStat_D_Actl 1;
BA_ "U_U55X_MY2022_Rx" SG_ 125 HsaStat_D_Actl 1;
BA_ "U_CD764_MY2022_Rx" SG_ 125 HsaStat_D_Actl 1;
BA_ "U_CX727_MY2021_Tx" SG_ 125 HsaStat_D_Actl 1;
BA_ "U_P702_MY2021_Tx" SG_ 125 HsaStat_D_Actl 1;
BA_ "U_T6_MCA_MY2020_Tx" SG_ 125 HsaStat_D_Actl 1;
BA_ "U_CD542_MY2021_Tx" SG_ 125 HsaStat_D_Actl 1;
BA_ "U_U55X_MY2022_Tx" SG_ 125 HsaStat_D_Actl 1;
BA_ "U_CD764_MY2022_Tx" SG_ 125 HsaStat_D_Actl 1;
BA_ "GenSigStartValueInteger" SG_ 119 VehTrvlDir_D_Stat 6;
BA_ "GenSigStartValue" SG_ 119 VehTrvlDir_D_Stat 6;
BA_ "U_P702_MY2021_Tx" SG_ 119 VehTrvlDir_D_Stat 1;
BA_ "U_T6_MCA_MY2020_Tx" SG_ 119 VehTrvlDir_D_Stat 1;
BA_ "U_U55X_MY2022_Tx" SG_ 119 VehTrvlDir_D_Stat 1;
BA_ "U_CX727_MY2021_Rx" SG_ 119 VehOverGnd_V_Est 1;
BA_ "U_P702_MY2021_Rx" SG_ 119 VehOverGnd_V_Est 1;
BA_ "U_T6_MCA_MY2020_Rx" SG_ 119 VehOverGnd_V_Est 1;
BA_ "U_CD542_MY2021_Rx" SG_ 119 VehOverGnd_V_Est 1;
BA_ "U_U55X_MY2022_Rx" SG_ 119 VehOverGnd_V_Est 1;
BA_ "U_CD764_MY2022_Rx" SG_ 119 VehOverGnd_V_Est 1;
BA_ "U_CX727_MY2021_Tx" SG_ 119 VehOverGnd_V_Est 1;
BA_ "U_P702_MY2021_Tx" SG_ 119 VehOverGnd_V_Est 1;
BA_ "U_T6_MCA_MY2020_Tx" SG_ 119 VehOverGnd_V_Est 1;
BA_ "U_CD542_MY2021_Tx" SG_ 119 VehOverGnd_V_Est 1;
BA_ "U_U55X_MY2022_Tx" SG_ 119 VehOverGnd_V_Est 1;
BA_ "U_CD764_MY2022_Tx" SG_ 119 VehOverGnd_V_Est 1;
BA_ "GenSigStartValueInteger" SG_ 119 VehLongComp_A_Actl 1022;
BA_ "GenSigStartValue" SG_ 119 VehLongComp_A_Actl 1022;
BA_ "U_CX727_MY2021_Rx" SG_ 119 VehLongComp_A_Actl 1;
BA_ "U_P702_MY2021_Rx" SG_ 119 VehLongComp_A_Actl 1;
BA_ "U_T6_MCA_MY2020_Rx" SG_ 119 VehLongComp_A_Actl 1;
BA_ "ECGUsedRxSignal" SG_ 119 VehLongComp_A_Actl 1;
BA_ "U_CD542_MY2021_Rx" SG_ 119 VehLongComp_A_Actl 1;
BA_ "U_U55X_MY2022_Rx" SG_ 119 VehLongComp_A_Actl 1;
BA_ "U_CD764_MY2022_Rx" SG_ 119 VehLongComp_A_Actl 1;
BA_ "U_CX727_MY2021_Tx" SG_ 119 VehLongComp_A_Actl 1;
BA_ "U_P702_MY2021_Tx" SG_ 119 VehLongComp_A_Actl 1;
BA_ "U_T6_MCA_MY2020_Tx" SG_ 119 VehLongComp_A_Actl 1;
BA_ "U_CD542_MY2021_Tx" SG_ 119 VehLongComp_A_Actl 1;
BA_ "U_U55X_MY2022_Tx" SG_ 119 VehLongComp_A_Actl 1;
BA_ "U_CD764_MY2022_Tx" SG_ 119 VehLongComp_A_Actl 1;
BA_ "GenSigStartValueInteger" SG_ 119 VehLatComp_A_Actl 1022;
BA_ "GenSigStartValue" SG_ 119 VehLatComp_A_Actl 1022;
BA_ "U_CX727_MY2021_Rx" SG_ 119 VehLatComp_A_Actl 1;
BA_ "U_P702_MY2021_Rx" SG_ 119 VehLatComp_A_Actl 1;
BA_ "U_T6_MCA_MY2020_Rx" SG_ 119 VehLatComp_A_Actl 1;
BA_ "ECGUsedRxSignal" SG_ 119 VehLatComp_A_Actl 1;
BA_ "U_CD542_MY2021_Rx" SG_ 119 VehLatComp_A_Actl 1;
BA_ "U_U55X_MY2022_Rx" SG_ 119 VehLatComp_A_Actl 1;
BA_ "U_CD764_MY2022_Rx" SG_ 119 VehLatComp_A_Actl 1;
BA_ "U_CX727_MY2021_Tx" SG_ 119 VehLatComp_A_Actl 1;
BA_ "U_P702_MY2021_Tx" SG_ 119 VehLatComp_A_Actl 1;
BA_ "U_T6_MCA_MY2020_Tx" SG_ 119 VehLatComp_A_Actl 1;
BA_ "U_CD542_MY2021_Tx" SG_ 119 VehLatComp_A_Actl 1;
BA_ "U_U55X_MY2022_Tx" SG_ 119 VehLatComp_A_Actl 1;
BA_ "U_CD764_MY2022_Tx" SG_ 119 VehLatComp_A_Actl 1;
BA_ "GenSigStartValueInteger" SG_ 119 VehYawComp_W_Actl 4094;
BA_ "GenSigStartValue" SG_ 119 VehYawComp_W_Actl 4094;
BA_ "U_CX727_MY2021_Rx" SG_ 119 VehYawComp_W_Actl 1;
BA_ "U_P702_MY2021_Rx" SG_ 119 VehYawComp_W_Actl 1;
BA_ "U_T6_MCA_MY2020_Rx" SG_ 119 VehYawComp_W_Actl 1;
BA_ "ECGUsedRxSignal" SG_ 119 VehYawComp_W_Actl 1;
BA_ "U_CD542_MY2021_Rx" SG_ 119 VehYawComp_W_Actl 1;
BA_ "U_U55X_MY2022_Rx" SG_ 119 VehYawComp_W_Actl 1;
BA_ "U_CD764_MY2022_Rx" SG_ 119 VehYawComp_W_Actl 1;
BA_ "U_CX727_MY2021_Tx" SG_ 119 VehYawComp_W_Actl 1;
BA_ "U_P702_MY2021_Tx" SG_ 119 VehYawComp_W_Actl 1;
BA_ "U_T6_MCA_MY2020_Tx" SG_ 119 VehYawComp_W_Actl 1;
BA_ "U_CD542_MY2021_Tx" SG_ 119 VehYawComp_W_Actl 1;
BA_ "U_U55X_MY2022_Tx" SG_ 119 VehYawComp_W_Actl 1;
BA_ "U_CD764_MY2022_Tx" SG_ 119 VehYawComp_W_Actl 1;
BA_ "U_CD542_MY2021_Rx" SG_ 119 PrplWhlPrim_Tq_RqMx 1;
BA_ "U_T6_MCA_MY2020_Tx" SG_ 119 PrplWhlPrim_Tq_RqMx 1;
BA_ "U_CD542_MY2021_Tx" SG_ 119 PrplWhlPrim_Tq_RqMx 1;
BA_ "U_CD764_MY2022_Tx" SG_ 119 PrplWhlPrim_Tq_RqMx 1;
BA_ "GenSigSendType" SG_ 118 BrkCtrFnd_B_Stat 3;
BA_ "U_P702_MY2021_Tx" SG_ 118 BrkCtrFnd_B_Stat 1;
BA_ "U_T6_MCA_MY2020_Tx" SG_ 118 BrkCtrFnd_B_Stat 1;
BA_ "U_U55X_MY2022_Tx" SG_ 118 BrkCtrFnd_B_Stat 1;
BA_ "GenSigSendType" SG_ 118 DrvSte_D_Stat 3;
BA_ "U_CX727_MY2021_Rx" SG_ 118 DrvSte_D_Stat 1;
BA_ "U_P702_MY2021_Rx" SG_ 118 DrvSte_D_Stat 1;
BA_ "U_T6_MCA_MY2020_Rx" SG_ 118 DrvSte_D_Stat 1;
BA_ "U_U55X_MY2022_Rx" SG_ 118 DrvSte_D_Stat 1;
BA_ "U_P702_MY2021_Tx" SG_ 118 DrvSte_D_Stat 1;
BA_ "U_T6_MCA_MY2020_Tx" SG_ 118 DrvSte_D_Stat 1;
BA_ "U_U55X_MY2022_Tx" SG_ 118 DrvSte_D_Stat 1;
BA_ "GenSigStartValueInteger" SG_ 118 DrvSte_Tq_Rq 128;
BA_ "U_CX727_MY2021_Rx" SG_ 118 DrvSte_Tq_Rq 1;
BA_ "U_P702_MY2021_Rx" SG_ 118 DrvSte_Tq_Rq 1;
BA_ "U_T6_MCA_MY2020_Rx" SG_ 118 DrvSte_Tq_Rq 1;
BA_ "U_U55X_MY2022_Rx" SG_ 118 DrvSte_Tq_Rq 1;
BA_ "U_P702_MY2021_Tx" SG_ 118 DrvSte_Tq_Rq 1;
BA_ "U_T6_MCA_MY2020_Tx" SG_ 118 DrvSte_Tq_Rq 1;
BA_ "U_U55X_MY2022_Tx" SG_ 118 DrvSte_Tq_Rq 1;
BA_ "GenSigSendType" SG_ 118 EmgcyBrkLamp_D_Rq 3;
BA_ "U_CX727_MY2021_Tx" SG_ 118 EmgcyBrkLamp_D_Rq 1;
BA_ "U_P702_MY2021_Tx" SG_ 118 EmgcyBrkLamp_D_Rq 1;
BA_ "U_T6_MCA_MY2020_Tx" SG_ 118 EmgcyBrkLamp_D_Rq 1;
BA_ "U_CD542_MY2021_Tx" SG_ 118 EmgcyBrkLamp_D_Rq 1;
BA_ "U_U55X_MY2022_Tx" SG_ 118 EmgcyBrkLamp_D_Rq 1;
BA_ "U_CD764_MY2022_Tx" SG_ 118 EmgcyBrkLamp_D_Rq 1;
BA_ "GenSigSendType" SG_ 118 StopLamp_B_RqBrk 3;
BA_ "U_CX727_MY2021_Tx" SG_ 118 StopLamp_B_RqBrk 1;
BA_ "U_P702_MY2021_Tx" SG_ 118 StopLamp_B_RqBrk 1;
BA_ "U_T6_MCA_MY2020_Tx" SG_ 118 StopLamp_B_RqBrk 1;
BA_ "U_CD542_MY2021_Tx" SG_ 118 StopLamp_B_RqBrk 1;
BA_ "U_U55X_MY2022_Tx" SG_ 118 StopLamp_B_RqBrk 1;
BA_ "GenSigSendType" SG_ 118 SteWhlCompAnEst_D_Qf 3;
BA_ "ContentDependant" SG_ 118 SteWhlCompAnEst_D_Qf 1;
BA_ "MetaData" SG_ 118 SteWhlCompAnEst_D_Qf 1;
BA_ "U_CX727_MY2021_Tx" SG_ 118 SteWhlCompAnEst_D_Qf 1;
BA_ "U_P702_MY2021_Tx" SG_ 118 SteWhlCompAnEst_D_Qf 1;
BA_ "U_T6_MCA_MY2020_Tx" SG_ 118 SteWhlCompAnEst_D_Qf 1;
BA_ "U_CD542_MY2021_Tx" SG_ 118 SteWhlCompAnEst_D_Qf 1;
BA_ "ContentDependant" SG_ 118 SteWhlComp_An_Est 1;
BA_ "U_CX727_MY2021_Tx" SG_ 118 SteWhlComp_An_Est 1;
BA_ "U_P702_MY2021_Tx" SG_ 118 SteWhlComp_An_Est 1;
BA_ "U_T6_MCA_MY2020_Tx" SG_ 118 SteWhlComp_An_Est 1;
BA_ "U_CD542_MY2021_Tx" SG_ 118 SteWhlComp_An_Est 1;
BA_ "U_CX727_MY2021_Rx" SG_ 73 immoSubTarget1Data_T1 1;
BA_ "U_P702_MY2021_Rx" SG_ 73 immoSubTarget1Data_T1 1;
BA_ "U_T6_MCA_MY2020_Rx" SG_ 73 immoSubTarget1Data_T1 1;
BA_ "U_CD542_MY2021_Rx" SG_ 73 immoSubTarget1Data_T1 1;
BA_ "U_CD764_MY2022_Rx" SG_ 73 immoSubTarget1Data_T1 1;
BA_ "U_CX727_MY2021_Tx" SG_ 73 immoSubTarget1Data_T1 1;
BA_ "U_P702_MY2021_Tx" SG_ 73 immoSubTarget1Data_T1 1;
BA_ "U_T6_MCA_MY2020_Tx" SG_ 73 immoSubTarget1Data_T1 1;
BA_ "U_CD542_MY2021_Tx" SG_ 73 immoSubTarget1Data_T1 1;
BA_ "U_U55X_MY2022_Tx" SG_ 73 immoSubTarget1Data_T1 1;
BA_ "U_CD764_MY2022_Tx" SG_ 73 immoSubTarget1Data_T1 1;
BA_ "GenSigStartValue" SG_ 73 immoSubTarget1Cmd_T1 6;
BA_ "U_CX727_MY2021_Rx" SG_ 73 immoSubTarget1Cmd_T1 1;
BA_ "U_P702_MY2021_Rx" SG_ 73 immoSubTarget1Cmd_T1 1;
BA_ "U_T6_MCA_MY2020_Rx" SG_ 73 immoSubTarget1Cmd_T1 1;
BA_ "U_CD542_MY2021_Rx" SG_ 73 immoSubTarget1Cmd_T1 1;
BA_ "U_CD764_MY2022_Rx" SG_ 73 immoSubTarget1Cmd_T1 1;
BA_ "U_CX727_MY2021_Tx" SG_ 73 immoSubTarget1Cmd_T1 1;
BA_ "U_P702_MY2021_Tx" SG_ 73 immoSubTarget1Cmd_T1 1;
BA_ "U_T6_MCA_MY2020_Tx" SG_ 73 immoSubTarget1Cmd_T1 1;
BA_ "U_CD542_MY2021_Tx" SG_ 73 immoSubTarget1Cmd_T1 1;
BA_ "U_U55X_MY2022_Tx" SG_ 73 immoSubTarget1Cmd_T1 1;
BA_ "U_CD764_MY2022_Tx" SG_ 73 immoSubTarget1Cmd_T1 1;
BA_ "U_CX727_MY2021_Rx" SG_ 1034 VehicleGGCCData 1;
BA_ "U_P702_MY2021_Rx" SG_ 1034 VehicleGGCCData 1;
BA_ "U_T6_MCA_MY2020_Rx" SG_ 1034 VehicleGGCCData 1;
BA_ "U_CD542_MY2021_Rx" SG_ 1034 VehicleGGCCData 1;
BA_ "U_U55X_MY2022_Rx" SG_ 1034 VehicleGGCCData 1;
BA_ "U_CD764_MY2022_Rx" SG_ 1034 VehicleGGCCData 1;
BA_ "U_P702_MY2021_Tx" SG_ 561 TrnMsgTxt2_D_Rq 1;
BA_ "U_T6_MCA_MY2020_Tx" SG_ 561 TrnMsgTxt2_D_Rq 1;
BA_ "U_P702_MY2021_Tx" SG_ 561 TrnMsgTxt_D_Rq 1;
BA_ "U_T6_MCA_MY2020_Tx" SG_ 561 TrnMsgTxt_D_Rq 1;
BA_ "ECGUsedRxSignal" SG_ 1090 MtrTotNum_No_ActlMntr 1;
BA_ "U_CD542_MY2021_Rx" SG_ 1090 MtrTotNum_No_ActlMntr 1;
BA_ "GenSigStartValueInteger" SG_ 1090 VehElRnge_L_Dsply 4095;
BA_ "GenSigStartValue" SG_ 1090 VehElRnge_L_Dsply 4093;
BA_ "ECGUsedRxSignal" SG_ 1090 VehElRnge_L_Dsply 1;
BA_ "U_CD542_MY2021_Rx" SG_ 1090 VehElRnge_L_Dsply 1;
BA_ "U_U55X_MY2022_Rx" SG_ 1090 VehElRnge_L_Dsply 1;
BA_ "U_CX727_MY2021_Tx" SG_ 1090 VehElRnge_L_Dsply 1;
BA_ "U_P702_MY2021_Tx" SG_ 1090 VehElRnge_L_Dsply 1;
BA_ "U_CD542_MY2021_Tx" SG_ 1090 VehElRnge_L_Dsply 1;
BA_ "ECGUsedRxSignal" SG_ 1090 Mtr2State_D_ActlMntr 1;
BA_ "U_CD542_MY2021_Rx" SG_ 1090 Mtr2State_D_ActlMntr 1;
BA_ "U_U55X_MY2022_Rx" SG_ 1090 Mtr2State_D_ActlMntr 1;
BA_ "U_CX727_MY2021_Tx" SG_ 1090 Mtr2State_D_ActlMntr 1;
BA_ "U_CD542_MY2021_Tx" SG_ 1090 Mtr2State_D_ActlMntr 1;
BA_ "GenSigStartValueInteger" SG_ 1090 Inv1Ain_I_ActlMntr 32766;
BA_ "GenSigStartValue" SG_ 1090 Inv1Ain_I_ActlMntr 32765;
BA_ "ECGUsedRxSignal" SG_ 1090 Inv1Ain_I_ActlMntr 1;
BA_ "U_CD542_MY2021_Rx" SG_ 1090 Inv1Ain_I_ActlMntr 1;
BA_ "U_U55X_MY2022_Rx" SG_ 1090 Inv1Ain_I_ActlMntr 1;
BA_ "U_CX727_MY2021_Tx" SG_ 1090 Inv1Ain_I_ActlMntr 1;
BA_ "U_CD542_MY2021_Tx" SG_ 1090 Inv1Ain_I_ActlMntr 1;
BA_ "ECGUsedRxSignal" SG_ 1090 HybVehMde_D_ActlMntr 1;
BA_ "U_CD542_MY2021_Rx" SG_ 1090 HybVehMde_D_ActlMntr 1;
BA_ "U_U55X_MY2022_Rx" SG_ 1090 HybVehMde_D_ActlMntr 1;
BA_ "U_CX727_MY2021_Tx" SG_ 1090 HybVehMde_D_ActlMntr 1;
BA_ "U_CD542_MY2021_Tx" SG_ 1090 HybVehMde_D_ActlMntr 1;
BA_ "ECGUsedRxSignal" SG_ 1090 ChrgStat_D_ActlMntr 1;
BA_ "U_CD542_MY2021_Rx" SG_ 1090 ChrgStat_D_ActlMntr 1;
BA_ "U_U55X_MY2022_Rx" SG_ 1090 ChrgStat_D_ActlMntr 1;
BA_ "U_CX727_MY2021_Tx" SG_ 1090 ChrgStat_D_ActlMntr 1;
BA_ "U_CD542_MY2021_Tx" SG_ 1090 ChrgStat_D_ActlMntr 1;
BA_ "U_CX727_MY2021_Tx" SG_ 870 PolicePurstMde_B_Stat 1;
BA_ "U_CD542_MY2021_Tx" SG_ 870 PolicePurstMde_B_Stat 1;
BA_ "GenSigStartValueInteger" SG_ 870 RngPerChrgInst_L_Dsply 4094;
BA_ "GenSigStartValue" SG_ 870 RngPerChrgInst_L_Dsply 4093;
BA_ "U_CX727_MY2021_Tx" SG_ 870 RngPerChrgInst_L_Dsply 1;
BA_ "U_P702_MY2021_Tx" SG_ 870 RngPerChrgInst_L_Dsply 1;
BA_ "U_CD542_MY2021_Tx" SG_ 870 RngPerChrgInst_L_Dsply 1;
BA_ "U_CX727_MY2021_Tx" SG_ 870 ChkPlgtoStrt_D_Dsply 1;
BA_ "U_CD542_MY2021_Tx" SG_ 870 ChkPlgtoStrt_D_Dsply 1;
BA_ "U_CX727_MY2021_Tx" SG_ 870 ElFuelFlw_Vl_Dsply 1;
BA_ "U_CD542_MY2021_Tx" SG_ 870 ElFuelFlw_Vl_Dsply 1;
BA_ "U_CX727_MY2021_Tx" SG_ 870 HybMdeLimMsgTxt_D_Rq 1;
BA_ "U_CD542_MY2021_Tx" SG_ 870 HybMdeLimMsgTxt_D_Rq 1;
BA_ "U_CX727_MY2021_Tx" SG_ 870 HybMdeMsgTxt_D2_Rq 1;
BA_ "U_CD542_MY2021_Tx" SG_ 870 HybMdeMsgTxt_D2_Rq 1;
BA_ "U_CX727_MY2021_Tx" SG_ 870 EngMdeMsgTxt_D_Rq 1;
BA_ "U_P702_MY2021_Tx" SG_ 870 EngMdeMsgTxt_D_Rq 1;
BA_ "U_CD542_MY2021_Tx" SG_ 870 EngMdeMsgTxt_D_Rq 1;
BA_ "U_CX727_MY2021_Tx" SG_ 870 BattPwWhl_Pc_Dsply 1;
BA_ "U_CD542_MY2021_Tx" SG_ 870 BattPwWhl_Pc_Dsply 1;
BA_ "GenSigStartValue" SG_ 870 EffRgenThres_Pc_Dsply 1023;
BA_ "U_CX727_MY2021_Tx" SG_ 870 EffRgenThres_Pc_Dsply 1;
BA_ "U_P702_MY2021_Tx" SG_ 870 EffRgenThres_Pc_Dsply 1;
BA_ "U_CD542_MY2021_Tx" SG_ 870 EffRgenThres_Pc_Dsply 1;
BA_ "U_CX727_MY2021_Tx" SG_ 870 ShifOutNtrlMsgTxt_D_Rq 1;
BA_ "U_CD542_MY2021_Tx" SG_ 870 ShifOutNtrlMsgTxt_D_Rq 1;
BA_ "U_CX727_MY2021_Tx" SG_ 869 PwrFlowTxt_D_Dsply 1;
BA_ "U_P702_MY2021_Tx" SG_ 869 PwrFlowTxt_D_Dsply 1;
BA_ "U_CD542_MY2021_Tx" SG_ 869 PwrFlowTxt_D_Dsply 1;
BA_ "U_CX727_MY2021_Tx" SG_ 869 EngOnMsg2_D_Dsply 1;
BA_ "U_P702_MY2021_Tx" SG_ 869 EngOnMsg2_D_Dsply 1;
BA_ "U_CD542_MY2021_Tx" SG_ 869 EngOnMsg2_D_Dsply 1;
BA_ "U_CX727_MY2021_Tx" SG_ 869 EngOnMsg1_D_Dsply 1;
BA_ "U_P702_MY2021_Tx" SG_ 869 EngOnMsg1_D_Dsply 1;
BA_ "U_CD542_MY2021_Tx" SG_ 869 EngOnMsg1_D_Dsply 1;
BA_ "U_CX727_MY2021_Tx" SG_ 869 FuelMaintMde_D_Dsply 1;
BA_ "U_P702_MY2021_Tx" SG_ 869 FuelMaintMde_D_Dsply 1;
BA_ "U_CD542_MY2021_Tx" SG_ 869 FuelMaintMde_D_Dsply 1;
BA_ "GenSigStartValueInteger" SG_ 869 EffWhlLvl2_Pc_Dsply 511;
BA_ "GenSigStartValue" SG_ 869 EffWhlLvl2_Pc_Dsply 511;
BA_ "U_CX727_MY2021_Tx" SG_ 869 EffWhlLvl2_Pc_Dsply 1;
BA_ "U_P702_MY2021_Tx" SG_ 869 EffWhlLvl2_Pc_Dsply 1;
BA_ "U_CD542_MY2021_Tx" SG_ 869 EffWhlLvl2_Pc_Dsply 1;
BA_ "U_CX727_MY2021_Tx" SG_ 869 RgenActv_B_Dsply 1;
BA_ "U_CD542_MY2021_Tx" SG_ 869 RgenActv_B_Dsply 1;
BA_ "U_CX727_MY2021_Tx" SG_ 869 EffWhlThres_Pc_Dsply 1;
BA_ "U_P702_MY2021_Tx" SG_ 869 EffWhlThres_Pc_Dsply 1;
BA_ "U_CD542_MY2021_Tx" SG_ 869 EffWhlThres_Pc_Dsply 1;
BA_ "U_CX727_MY2021_Tx" SG_ 869 EffEAvg_Pc_Dsply 1;
BA_ "U_CD542_MY2021_Tx" SG_ 869 EffEAvg_Pc_Dsply 1;
BA_ "U_CX727_MY2021_Tx" SG_ 869 EngPwLvl_Pc_Dsply 1;
BA_ "U_P702_MY2021_Tx" SG_ 869 EngPwLvl_Pc_Dsply 1;
BA_ "U_CD542_MY2021_Tx" SG_ 869 EngPwLvl_Pc_Dsply 1;
BA_ "U_CX727_MY2021_Tx" SG_ 869 EngOffTe_B_Dsply 1;
BA_ "U_CD542_MY2021_Tx" SG_ 869 EngOffTe_B_Dsply 1;
BA_ "U_CX727_MY2021_Tx" SG_ 869 EngActv_B_Dsply 1;
BA_ "U_P702_MY2021_Tx" SG_ 869 EngActv_B_Dsply 1;
BA_ "U_CD542_MY2021_Tx" SG_ 869 EngActv_B_Dsply 1;
BA_ "U_CX727_MY2021_Tx" SG_ 869 EffWhlThresOn_B_Dsply 1;
BA_ "U_P702_MY2021_Tx" SG_ 869 EffWhlThresOn_B_Dsply 1;
BA_ "U_CD542_MY2021_Tx" SG_ 869 EffWhlThresOn_B_Dsply 1;
BA_ "U_CX727_MY2021_Tx" SG_ 869 DchrgActv_B_Dsply 1;
BA_ "U_CD542_MY2021_Tx" SG_ 869 DchrgActv_B_Dsply 1;
BA_ "U_CX727_MY2021_Tx" SG_ 869 ChrgActv_B_Dsply 1;
BA_ "U_CD542_MY2021_Tx" SG_ 869 ChrgActv_B_Dsply 1;
BA_ "GenSigSendType" SG_ 606 BattTracThrml_D_Stat 3;
BA_ "GenSigSendType" SG_ 606 ElVehLaterMde_D_Stat 3;
BA_ "U_CX727_MY2021_Rx" SG_ 606 ElVehLaterMde_D_Stat 1;
BA_ "U_CD542_MY2021_Rx" SG_ 606 ElVehLaterMde_D_Stat 1;
BA_ "U_CD764_MY2022_Rx" SG_ 606 ElVehLaterMde_D_Stat 1;
BA_ "U_CX727_MY2021_Tx" SG_ 606 ElVehLaterMde_D_Stat 1;
BA_ "U_P702_MY2021_Tx" SG_ 606 ElVehLaterMde_D_Stat 1;
BA_ "U_CD542_MY2021_Tx" SG_ 606 ElVehLaterMde_D_Stat 1;
BA_ "GenSigSendType" SG_ 606 ElVehNowMde_D_Stat 3;
BA_ "U_CX727_MY2021_Rx" SG_ 606 ElVehNowMde_D_Stat 1;
BA_ "U_CD542_MY2021_Rx" SG_ 606 ElVehNowMde_D_Stat 1;
BA_ "U_CD764_MY2022_Rx" SG_ 606 ElVehNowMde_D_Stat 1;
BA_ "U_CX727_MY2021_Tx" SG_ 606 ElVehNowMde_D_Stat 1;
BA_ "U_P702_MY2021_Tx" SG_ 606 ElVehNowMde_D_Stat 1;
BA_ "U_CD542_MY2021_Tx" SG_ 606 ElVehNowMde_D_Stat 1;
BA_ "GenSigSendType" SG_ 374 GearEngag_D_Actl 3;
BA_ "U_T6_MCA_MY2020_Rx" SG_ 374 GearEngag_D_Actl 1;
BA_ "U_CD542_MY2021_Rx" SG_ 374 GearEngag_D_Actl 1;
BA_ "U_CD764_MY2022_Rx" SG_ 374 GearEngag_D_Actl 1;
BA_ "U_CX727_MY2021_Tx" SG_ 374 GearEngag_D_Actl 1;
BA_ "U_P702_MY2021_Tx" SG_ 374 GearEngag_D_Actl 1;
BA_ "U_T6_MCA_MY2020_Tx" SG_ 374 GearEngag_D_Actl 1;
BA_ "U_CD542_MY2021_Tx" SG_ 374 GearEngag_D_Actl 1;
BA_ "U_U55X_MY2022_Tx" SG_ 374 GearEngag_D_Actl 1;
BA_ "U_CD764_MY2022_Tx" SG_ 374 GearEngag_D_Actl 1;
BA_ "GenSigSendType" SG_ 374 TrnRng_D_Rq 3;
BA_ "GenSigStartValueInteger" SG_ 374 TrnRng_D_Rq 14;
BA_ "ContentDependant" SG_ 374 TrnRng_D_Rq 1;
BA_ "GenSigStartValue" SG_ 374 TrnRng_D_Rq 14;
BA_ "U_CX727_MY2021_Rx" SG_ 374 TrnRng_D_Rq 1;
BA_ "U_P702_MY2021_Rx" SG_ 374 TrnRng_D_Rq 1;
BA_ "U_T6_MCA_MY2020_Rx" SG_ 374 TrnRng_D_Rq 1;
BA_ "U_CD542_MY2021_Rx" SG_ 374 TrnRng_D_Rq 1;
BA_ "U_U55X_MY2022_Rx" SG_ 374 TrnRng_D_Rq 1;
BA_ "U_CD764_MY2022_Rx" SG_ 374 TrnRng_D_Rq 1;
BA_ "U_CX727_MY2021_Tx" SG_ 374 TrnRng_D_Rq 1;
BA_ "U_P702_MY2021_Tx" SG_ 374 TrnRng_D_Rq 1;
BA_ "U_T6_MCA_MY2020_Tx" SG_ 374 TrnRng_D_Rq 1;
BA_ "U_CD542_MY2021_Tx" SG_ 374 TrnRng_D_Rq 1;
BA_ "U_U55X_MY2022_Tx" SG_ 374 TrnRng_D_Rq 1;
BA_ "U_CD764_MY2022_Tx" SG_ 374 TrnRng_D_Rq 1;
BA_ "GenSigSendType" SG_ 374 TrnPrkSys_D_Actl 3;
BA_ "ContentDependant" SG_ 374 TrnPrkSys_D_Actl 1;
BA_ "U_CX727_MY2021_Rx" SG_ 374 TrnPrkSys_D_Actl 1;
BA_ "U_P702_MY2021_Rx" SG_ 374 TrnPrkSys_D_Actl 1;
BA_ "U_T6_MCA_MY2020_Rx" SG_ 374 TrnPrkSys_D_Actl 1;
BA_ "U_CD542_MY2021_Rx" SG_ 374 TrnPrkSys_D_Actl 1;
BA_ "U_U55X_MY2022_Rx" SG_ 374 TrnPrkSys_D_Actl 1;
BA_ "U_CD764_MY2022_Rx" SG_ 374 TrnPrkSys_D_Actl 1;
BA_ "U_CX727_MY2021_Tx" SG_ 374 TrnPrkSys_D_Actl 1;
BA_ "U_P702_MY2021_Tx" SG_ 374 TrnPrkSys_D_Actl 1;
BA_ "U_T6_MCA_MY2020_Tx" SG_ 374 TrnPrkSys_D_Actl 1;
BA_ "U_CD542_MY2021_Tx" SG_ 374 TrnPrkSys_D_Actl 1;
BA_ "U_U55X_MY2022_Tx" SG_ 374 TrnPrkSys_D_Actl 1;
BA_ "U_CD764_MY2022_Tx" SG_ 374 TrnPrkSys_D_Actl 1;
BA_ "GenSigSendType" SG_ 374 GearLvr_D_ActlDrv 3;
BA_ "ContentDependant" SG_ 374 GearLvr_D_ActlDrv 1;
BA_ "U_CX727_MY2021_Rx" SG_ 374 GearLvr_D_ActlDrv 1;
BA_ "U_P702_MY2021_Rx" SG_ 374 GearLvr_D_ActlDrv 1;
BA_ "U_T6_MCA_MY2020_Rx" SG_ 374 GearLvr_D_ActlDrv 1;
BA_ "U_CD542_MY2021_Rx" SG_ 374 GearLvr_D_ActlDrv 1;
BA_ "U_U55X_MY2022_Rx" SG_ 374 GearLvr_D_ActlDrv 1;
BA_ "U_CD764_MY2022_Rx" SG_ 374 GearLvr_D_ActlDrv 1;
BA_ "U_CX727_MY2021_Tx" SG_ 374 GearLvr_D_ActlDrv 1;
BA_ "U_P702_MY2021_Tx" SG_ 374 GearLvr_D_ActlDrv 1;
BA_ "U_T6_MCA_MY2020_Tx" SG_ 374 GearLvr_D_ActlDrv 1;
BA_ "U_CD542_MY2021_Tx" SG_ 374 GearLvr_D_ActlDrv 1;
BA_ "U_U55X_MY2022_Tx" SG_ 374 GearLvr_D_ActlDrv 1;
BA_ "U_CD764_MY2022_Tx" SG_ 374 GearLvr_D_ActlDrv 1;
BA_ "ContentDependant" SG_ 374 GearPos_No_Cs 1;
BA_ "MetaData" SG_ 374 GearPos_No_Cs 1;
BA_ "U_CX727_MY2021_Rx" SG_ 374 GearPos_No_Cs 1;
BA_ "U_P702_MY2021_Rx" SG_ 374 GearPos_No_Cs 1;
BA_ "U_T6_MCA_MY2020_Rx" SG_ 374 GearPos_No_Cs 1;
BA_ "U_CD542_MY2021_Rx" SG_ 374 GearPos_No_Cs 1;
BA_ "U_U55X_MY2022_Rx" SG_ 374 GearPos_No_Cs 1;
BA_ "U_CD764_MY2022_Rx" SG_ 374 GearPos_No_Cs 1;
BA_ "U_CX727_MY2021_Tx" SG_ 374 GearPos_No_Cs 1;
BA_ "U_P702_MY2021_Tx" SG_ 374 GearPos_No_Cs 1;
BA_ "U_T6_MCA_MY2020_Tx" SG_ 374 GearPos_No_Cs 1;
BA_ "U_CD542_MY2021_Tx" SG_ 374 GearPos_No_Cs 1;
BA_ "U_U55X_MY2022_Tx" SG_ 374 GearPos_No_Cs 1;
BA_ "U_CD764_MY2022_Tx" SG_ 374 GearPos_No_Cs 1;
BA_ "GenSigSendType" SG_ 374 GearPos_D_Trg 3;
BA_ "GenSigStartValueInteger" SG_ 374 GearPos_D_Trg 15;
BA_ "ContentDependant" SG_ 374 GearPos_D_Trg 1;
BA_ "GenSigStartValue" SG_ 374 GearPos_D_Trg 15;
BA_ "U_CX727_MY2021_Rx" SG_ 374 GearPos_D_Trg 1;
BA_ "U_P702_MY2021_Rx" SG_ 374 GearPos_D_Trg 1;
BA_ "U_T6_MCA_MY2020_Rx" SG_ 374 GearPos_D_Trg 1;
BA_ "U_CD542_MY2021_Rx" SG_ 374 GearPos_D_Trg 1;
BA_ "U_U55X_MY2022_Rx" SG_ 374 GearPos_D_Trg 1;
BA_ "U_CD764_MY2022_Rx" SG_ 374 GearPos_D_Trg 1;
BA_ "U_CX727_MY2021_Tx" SG_ 374 GearPos_D_Trg 1;
BA_ "U_P702_MY2021_Tx" SG_ 374 GearPos_D_Trg 1;
BA_ "U_T6_MCA_MY2020_Tx" SG_ 374 GearPos_D_Trg 1;
BA_ "U_CD542_MY2021_Tx" SG_ 374 GearPos_D_Trg 1;
BA_ "U_U55X_MY2022_Tx" SG_ 374 GearPos_D_Trg 1;
BA_ "U_CD764_MY2022_Tx" SG_ 374 GearPos_D_Trg 1;
BA_ "ContentDependant" SG_ 374 GearPos_No_Cnt 1;
BA_ "MetaData" SG_ 374 GearPos_No_Cnt 1;
BA_ "U_CX727_MY2021_Rx" SG_ 374 GearPos_No_Cnt 1;
BA_ "U_P702_MY2021_Rx" SG_ 374 GearPos_No_Cnt 1;
BA_ "U_T6_MCA_MY2020_Rx" SG_ 374 GearPos_No_Cnt 1;
BA_ "U_CD542_MY2021_Rx" SG_ 374 GearPos_No_Cnt 1;
BA_ "U_U55X_MY2022_Rx" SG_ 374 GearPos_No_Cnt 1;
BA_ "U_CD764_MY2022_Rx" SG_ 374 GearPos_No_Cnt 1;
BA_ "U_CX727_MY2021_Tx" SG_ 374 GearPos_No_Cnt 1;
BA_ "U_P702_MY2021_Tx" SG_ 374 GearPos_No_Cnt 1;
BA_ "U_T6_MCA_MY2020_Tx" SG_ 374 GearPos_No_Cnt 1;
BA_ "U_CD542_MY2021_Tx" SG_ 374 GearPos_No_Cnt 1;
BA_ "U_U55X_MY2022_Tx" SG_ 374 GearPos_No_Cnt 1;
BA_ "U_CD764_MY2022_Tx" SG_ 374 GearPos_No_Cnt 1;
BA_ "U_CX727_MY2021_Tx" SG_ 374 TrnIgnOffDly_T_Rq 1;
BA_ "U_P702_MY2021_Tx" SG_ 374 TrnIgnOffDly_T_Rq 1;
BA_ "U_T6_MCA_MY2020_Tx" SG_ 374 TrnIgnOffDly_T_Rq 1;
BA_ "U_CD542_MY2021_Tx" SG_ 374 TrnIgnOffDly_T_Rq 1;
BA_ "U_U55X_MY2022_Tx" SG_ 374 TrnIgnOffDly_T_Rq 1;
BA_ "U_CD764_MY2022_Tx" SG_ 374 TrnIgnOffDly_T_Rq 1;
BA_ "GenSigSendType" SG_ 374 GearPos_D_Actl 3;
BA_ "GenSigStartValueInteger" SG_ 374 GearPos_D_Actl 15;
BA_ "ContentDependant" SG_ 374 GearPos_D_Actl 1;
BA_ "GenSigStartValue" SG_ 374 GearPos_D_Actl 15;
BA_ "U_CX727_MY2021_Rx" SG_ 374 GearPos_D_Actl 1;
BA_ "U_P702_MY2021_Rx" SG_ 374 GearPos_D_Actl 1;
BA_ "U_T6_MCA_MY2020_Rx" SG_ 374 GearPos_D_Actl 1;
BA_ "U_CD542_MY2021_Rx" SG_ 374 GearPos_D_Actl 1;
BA_ "U_U55X_MY2022_Rx" SG_ 374 GearPos_D_Actl 1;
BA_ "U_CD764_MY2022_Rx" SG_ 374 GearPos_D_Actl 1;
BA_ "U_CX727_MY2021_Tx" SG_ 374 GearPos_D_Actl 1;
BA_ "U_P702_MY2021_Tx" SG_ 374 GearPos_D_Actl 1;
BA_ "U_T6_MCA_MY2020_Tx" SG_ 374 GearPos_D_Actl 1;
BA_ "U_CD542_MY2021_Tx" SG_ 374 GearPos_D_Actl 1;
BA_ "U_U55X_MY2022_Tx" SG_ 374 GearPos_D_Actl 1;
BA_ "U_CD764_MY2022_Tx" SG_ 374 GearPos_D_Actl 1;
BA_ "U_CX727_MY2021_Rx" SG_ 603 EngAout_Tq_RqSlw 1;
BA_ "U_CD542_MY2021_Rx" SG_ 603 EngAout_Tq_RqSlw 1;
BA_ "U_CX727_MY2021_Tx" SG_ 603 EngAout_Tq_RqSlw 1;
BA_ "U_CD542_MY2021_Tx" SG_ 603 EngAout_Tq_RqSlw 1;
BA_ "U_CX727_MY2021_Rx" SG_ 603 FuelCtlOpenLp_B_Inhbt 1;
BA_ "U_CD542_MY2021_Rx" SG_ 603 FuelCtlOpenLp_B_Inhbt 1;
BA_ "U_CX727_MY2021_Tx" SG_ 603 FuelCtlOpenLp_B_Inhbt 1;
BA_ "U_CD542_MY2021_Tx" SG_ 603 FuelCtlOpenLp_B_Inhbt 1;
BA_ "U_CX727_MY2021_Rx" SG_ 603 EngDiag_D_RqHtrn 1;
BA_ "U_CD542_MY2021_Rx" SG_ 603 EngDiag_D_RqHtrn 1;
BA_ "U_CX727_MY2021_Tx" SG_ 603 EngDiag_D_RqHtrn 1;
BA_ "U_CD542_MY2021_Tx" SG_ 603 EngDiag_D_RqHtrn 1;
BA_ "ContentDependant" SG_ 603 WhlDirAvgDrv_D_Actl 1;
BA_ "U_CX727_MY2021_Rx" SG_ 603 WhlDirAvgDrv_D_Actl 1;
BA_ "U_P702_MY2021_Rx" SG_ 603 WhlDirAvgDrv_D_Actl 1;
BA_ "U_T6_MCA_MY2020_Rx" SG_ 603 WhlDirAvgDrv_D_Actl 1;
BA_ "U_CD542_MY2021_Rx" SG_ 603 WhlDirAvgDrv_D_Actl 1;
BA_ "U_U55X_MY2022_Rx" SG_ 603 WhlDirAvgDrv_D_Actl 1;
BA_ "U_CD764_MY2022_Rx" SG_ 603 WhlDirAvgDrv_D_Actl 1;
BA_ "U_CX727_MY2021_Tx" SG_ 603 WhlDirAvgDrv_D_Actl 1;
BA_ "U_P702_MY2021_Tx" SG_ 603 WhlDirAvgDrv_D_Actl 1;
BA_ "U_CD542_MY2021_Tx" SG_ 603 WhlDirAvgDrv_D_Actl 1;
BA_ "ContentDependant" SG_ 603 PrplTqMnRgen_B_Actl 1;
BA_ "U_CX727_MY2021_Rx" SG_ 603 PrplTqMnRgen_B_Actl 1;
BA_ "U_P702_MY2021_Rx" SG_ 603 PrplTqMnRgen_B_Actl 1;
BA_ "U_CD542_MY2021_Rx" SG_ 603 PrplTqMnRgen_B_Actl 1;
BA_ "U_CD764_MY2022_Rx" SG_ 603 PrplTqMnRgen_B_Actl 1;
BA_ "U_CX727_MY2021_Tx" SG_ 603 PrplTqMnRgen_B_Actl 1;
BA_ "U_P702_MY2021_Tx" SG_ 603 PrplTqMnRgen_B_Actl 1;
BA_ "U_CD542_MY2021_Tx" SG_ 603 PrplTqMnRgen_B_Actl 1;
BA_ "U_CX727_MY2021_Rx" SG_ 603 EngAout_Tq_RqFst 1;
BA_ "U_CD542_MY2021_Rx" SG_ 603 EngAout_Tq_RqFst 1;
BA_ "U_CX727_MY2021_Tx" SG_ 603 EngAout_Tq_RqFst 1;
BA_ "U_CD542_MY2021_Tx" SG_ 603 EngAout_Tq_RqFst 1;
BA_ "U_CX727_MY2021_Rx" SG_ 603 PrplWhlTot_Tq_Cmd 1;
BA_ "U_CD542_MY2021_Rx" SG_ 603 PrplWhlTot_Tq_Cmd 1;
BA_ "U_CX727_MY2021_Tx" SG_ 603 PrplWhlTot_Tq_Cmd 1;
BA_ "U_CD542_MY2021_Tx" SG_ 603 PrplWhlTot_Tq_Cmd 1;
BA_ "GenSigStartValueInteger" SG_ 603 EDrvTqMntrRconfg_D_Cmd 7;
BA_ "GenSigStartValue" SG_ 603 EDrvTqMntrRconfg_D_Cmd 7;
BA_ "U_CX727_MY2021_Rx" SG_ 603 EDrvTqMntrRconfg_D_Cmd 1;
BA_ "U_CD542_MY2021_Rx" SG_ 603 EDrvTqMntrRconfg_D_Cmd 1;
BA_ "U_CX727_MY2021_Tx" SG_ 603 EDrvTqMntrRconfg_D_Cmd 1;
BA_ "U_CD542_MY2021_Tx" SG_ 603 EDrvTqMntrRconfg_D_Cmd 1;
BA_ "GenSigStartValueInteger" SG_ 603 BattTracCnnct_D_Rq 2;
BA_ "ContentDependant" SG_ 603 BattTracCnnct_D_Rq 1;
BA_ "GenSigStartValue" SG_ 603 BattTracCnnct_D_Rq 2;
BA_ "U_CX727_MY2021_Rx" SG_ 603 BattTracCnnct_D_Rq 1;
BA_ "U_CD542_MY2021_Rx" SG_ 603 BattTracCnnct_D_Rq 1;
BA_ "U_CX727_MY2021_Tx" SG_ 603 BattTracCnnct_D_Rq 1;
BA_ "U_P702_MY2021_Tx" SG_ 603 BattTracCnnct_D_Rq 1;
BA_ "U_CD542_MY2021_Tx" SG_ 603 BattTracCnnct_D_Rq 1;
BA_ "U_CX727_MY2021_Rx" SG_ 603 EngAout_N_Spc 1;
BA_ "U_CD542_MY2021_Rx" SG_ 603 EngAout_N_Spc 1;
BA_ "U_CX727_MY2021_Tx" SG_ 603 EngAout_N_Spc 1;
BA_ "U_CD542_MY2021_Tx" SG_ 603 EngAout_N_Spc 1;
BA_ "ECGUsedRxSignal" SG_ 602 HtrnWarnLamp_B_Dsply 1;
BA_ "U_CD542_MY2021_Rx" SG_ 602 HtrnWarnLamp_B_Dsply 1;
BA_ "U_U55X_MY2022_Rx" SG_ 602 HtrnWarnLamp_B_Dsply 1;
BA_ "U_CD764_MY2022_Rx" SG_ 602 HtrnWarnLamp_B_Dsply 1;
BA_ "U_CX727_MY2021_Tx" SG_ 602 HtrnWarnLamp_B_Dsply 1;
BA_ "U_P702_MY2021_Tx" SG_ 602 HtrnWarnLamp_B_Dsply 1;
BA_ "U_CD542_MY2021_Tx" SG_ 602 HtrnWarnLamp_B_Dsply 1;
BA_ "U_CX727_MY2021_Rx" SG_ 602 PtcHtrRun_B_Rq 1;
BA_ "U_CX727_MY2021_Tx" SG_ 602 PtcHtrRun_B_Rq 1;
BA_ "U_CD542_MY2021_Tx" SG_ 602 PtcHtrRun_B_Rq 1;
BA_ "U_CX727_MY2021_Rx" SG_ 602 CoolFan_D_Rq 1;
BA_ "U_CX727_MY2021_Tx" SG_ 602 CoolFan_D_Rq 1;
BA_ "U_CD542_MY2021_Tx" SG_ 602 CoolFan_D_Rq 1;
BA_ "U_CX727_MY2021_Tx" SG_ 602 PwPckTqRdy_B_Dsply 1;
BA_ "U_P702_MY2021_Tx" SG_ 602 PwPckTqRdy_B_Dsply 1;
BA_ "U_CD542_MY2021_Tx" SG_ 602 PwPckTqRdy_B_Dsply 1;
BA_ "U_CX727_MY2021_Rx" SG_ 602 HtrnAin_N_RqMxPrtct 1;
BA_ "U_CX727_MY2021_Tx" SG_ 602 HtrnAin_N_RqMxPrtct 1;
BA_ "U_CD542_MY2021_Tx" SG_ 602 HtrnAin_N_RqMxPrtct 1;
BA_ "U_CX727_MY2021_Rx" SG_ 602 ObdEngStdy_B_Stat 1;
BA_ "U_CX727_MY2021_Tx" SG_ 602 ObdEngStdy_B_Stat 1;
BA_ "U_CD542_MY2021_Tx" SG_ 602 ObdEngStdy_B_Stat 1;
BA_ "U_CX727_MY2021_Rx" SG_ 602 EngStrtSrvc_B_Allw 1;
BA_ "U_CX727_MY2021_Tx" SG_ 602 EngStrtSrvc_B_Allw 1;
BA_ "U_CD542_MY2021_Tx" SG_ 602 EngStrtSrvc_B_Allw 1;
BA_ "GenSigStartValueInteger" SG_ 1152 VehElEff_No_Avg 126;
BA_ "GenSigStartValue" SG_ 1152 VehElEff_No_Avg 126;
BA_ "U_P702_MY2021_Rx" SG_ 1152 VehElEff_No_Avg 1;
BA_ "U_P702_MY2021_Tx" SG_ 1152 VehElEff_No_Avg 1;
BA_ "GenSigSendType" SG_ 1152 PwCabinEnblScnd_B_Rq 3;
BA_ "GenSigSendType" SG_ 1152 PwCabinEnbl_B_Rq 3;
BA_ "GenSigSendType" SG_ 1152 PwTrnkFrntEnblScnd_B_Rq 3;
BA_ "GenSigSendType" SG_ 1152 PwTrnkFrntEnbl_B_Rq 3;
BA_ "GenSigSendType" SG_ 1152 PwOutlet8EnblScnd_B_Rq 3;
BA_ "GenSigSendType" SG_ 1152 PwOutlet8Enbl_B_Rq 3;
BA_ "GenSigSendType" SG_ 1152 PwOutlet7EnblScnd_B_Rq 3;
BA_ "GenSigSendType" SG_ 1152 PwOutlet7Enbl_B_Rq 3;
BA_ "GenSigSendType" SG_ 1152 PwOutlet6EnblScnd_B_Rq 3;
BA_ "GenSigSendType" SG_ 1152 PwOutlet6Enbl_B_Rq 3;
BA_ "GenSigSendType" SG_ 1152 HybPwULoLamp_B_Rq 3;
BA_ "U_CX727_MY2021_Rx" SG_ 1152 GrdAsstActv_B_Stat 1;
BA_ "U_CD542_MY2021_Rx" SG_ 1152 GrdAsstActv_B_Stat 1;
BA_ "U_P702_MY2021_Tx" SG_ 1152 GrdAsstActv_B_Stat 1;
BA_ "U_CD542_MY2021_Tx" SG_ 1152 GrdAsstActv_B_Stat 1;
BA_ "GenSigSendType" SG_ 1152 EngTeHi_B_Actl 3;
BA_ "U_CX727_MY2021_Rx" SG_ 1152 EngTeHi_B_Actl 1;
BA_ "U_CD542_MY2021_Rx" SG_ 1152 EngTeHi_B_Actl 1;
BA_ "U_CX727_MY2021_Tx" SG_ 1152 EngTeHi_B_Actl 1;
BA_ "U_P702_MY2021_Tx" SG_ 1152 EngTeHi_B_Actl 1;
BA_ "U_CD542_MY2021_Tx" SG_ 1152 EngTeHi_B_Actl 1;
BA_ "GenSigSendType" SG_ 1152 DcdcOn_B_Rq 3;
BA_ "U_CX727_MY2021_Tx" SG_ 1152 DcdcOn_B_Rq 1;
BA_ "U_P702_MY2021_Tx" SG_ 1152 DcdcOn_B_Rq 1;
BA_ "U_CD542_MY2021_Tx" SG_ 1152 DcdcOn_B_Rq 1;
BA_ "GenSigSendType" SG_ 1152 ULoBattSpprtSustn_B_Rq 3;
BA_ "U_CX727_MY2021_Rx" SG_ 1152 ULoBattSpprtSustn_B_Rq 1;
BA_ "U_CD542_MY2021_Rx" SG_ 1152 ULoBattSpprtSustn_B_Rq 1;
BA_ "U_CX727_MY2021_Tx" SG_ 1152 ULoBattSpprtSustn_B_Rq 1;
BA_ "U_P702_MY2021_Tx" SG_ 1152 ULoBattSpprtSustn_B_Rq 1;
BA_ "U_CD542_MY2021_Tx" SG_ 1152 ULoBattSpprtSustn_B_Rq 1;
BA_ "GenSigSendType" SG_ 1152 BattTracDiagClr_B_Stat 3;
BA_ "U_CD542_MY2021_Tx" SG_ 1152 BattTracDiagClr_B_Stat 1;
BA_ "GenSigStartValue" SG_ 872 DcdcIn_Pw_Mx 115;
BA_ "U_CD542_MY2021_Tx" SG_ 872 DcdcIn_Pw_Mx 1;
BA_ "U_CD542_MY2021_Tx" SG_ 872 PwFlowPlgBatt_D_Dsply 1;
BA_ "U_CD542_MY2021_Tx" SG_ 872 PwFlowMtrDrv_D_Dsply 1;
BA_ "U_CD542_MY2021_Tx" SG_ 872 PwFlowEngMtr_D_Dsply 1;
BA_ "U_CD542_MY2021_Tx" SG_ 872 PwFlowEngFuel_D_Dsply 1;
BA_ "U_CD542_MY2021_Tx" SG_ 872 PwFlowEngDrv_D_Dsply 1;
BA_ "U_CD542_MY2021_Tx" SG_ 872 PwFlowBattMtr_D_Dsply 1;
BA_ "GenSigStartValueInteger" SG_ 872 MtrPwLvl_Pc_Dsply 511;
BA_ "U_CX727_MY2021_Tx" SG_ 872 MtrPwLvl_Pc_Dsply 1;
BA_ "U_CD542_MY2021_Tx" SG_ 872 MtrPwLvl_Pc_Dsply 1;
BA_ "ECGUsedRxSignal" SG_ 872 PlgActvArb_B_Dsply 1;
BA_ "U_CD542_MY2021_Rx" SG_ 872 PlgActvArb_B_Dsply 1;
BA_ "U_U55X_MY2022_Rx" SG_ 872 PlgActvArb_B_Dsply 1;
BA_ "U_CX727_MY2021_Tx" SG_ 872 PlgActvArb_B_Dsply 1;
BA_ "U_P702_MY2021_Tx" SG_ 872 PlgActvArb_B_Dsply 1;
BA_ "U_CD542_MY2021_Tx" SG_ 872 PlgActvArb_B_Dsply 1;
BA_ "U_CX727_MY2021_Tx" SG_ 872 LvAcsyPwLvl_Pc_Dsply 1;
BA_ "U_CD542_MY2021_Tx" SG_ 872 LvAcsyPwLvl_Pc_Dsply 1;
BA_ "U_CD542_MY2021_Tx" SG_ 872 ClimPwLvl_Pc_Dsply 1;
BA_ "ECGUsedRxSignal" SG_ 872 HybMdeStat_D_Dsply 1;
BA_ "U_CD542_MY2021_Rx" SG_ 872 HybMdeStat_D_Dsply 1;
BA_ "U_U55X_MY2022_Rx" SG_ 872 HybMdeStat_D_Dsply 1;
BA_ "U_CX727_MY2021_Tx" SG_ 872 HybMdeStat_D_Dsply 1;
BA_ "U_P702_MY2021_Tx" SG_ 872 HybMdeStat_D_Dsply 1;
BA_ "U_CD542_MY2021_Tx" SG_ 872 HybMdeStat_D_Dsply 1;
BA_ "U_CD542_MY2021_Tx" SG_ 872 EcoMode_B_Stat 1;
BA_ "ContentDependant" SG_ 560 SelDrvMdeSwtch_D_Stat3 1;
BA_ "U_P702_MY2021_Rx" SG_ 560 SelDrvMdeSwtch_D_Stat3 1;
BA_ "U_U55X_MY2022_Rx" SG_ 560 SelDrvMdeSwtch_D_Stat3 1;
BA_ "U_CX727_MY2021_Tx" SG_ 560 SelDrvMdeSwtch_D_Stat3 1;
BA_ "U_P702_MY2021_Tx" SG_ 560 SelDrvMdeSwtch_D_Stat3 1;
BA_ "U_T6_MCA_MY2020_Tx" SG_ 560 SelDrvMdeSwtch_D_Stat3 1;
BA_ "U_CD542_MY2021_Tx" SG_ 560 SelDrvMdeSwtch_D_Stat3 1;
BA_ "U_U55X_MY2022_Tx" SG_ 560 SelDrvMdeSwtch_D_Stat3 1;
BA_ "ContentDependant" SG_ 560 GearLvrPosActl_No_Cs 1;
BA_ "MetaData" SG_ 560 GearLvrPosActl_No_Cs 1;
BA_ "U_CX727_MY2021_Tx" SG_ 560 GearLvrPosActl_No_Cs 1;
BA_ "U_CD542_MY2021_Tx" SG_ 560 GearLvrPosActl_No_Cs 1;
BA_ "ContentDependant" SG_ 560 GearLvrPosActl_No_Cnt 1;
BA_ "MetaData" SG_ 560 GearLvrPosActl_No_Cnt 1;
BA_ "U_CX727_MY2021_Tx" SG_ 560 GearLvrPosActl_No_Cnt 1;
BA_ "U_CD542_MY2021_Tx" SG_ 560 GearLvrPosActl_No_Cnt 1;
BA_ "ContentDependant" SG_ 560 TrnGbox_Rt_Actl 1;
BA_ "U_CX727_MY2021_Rx" SG_ 560 TrnGbox_Rt_Actl 1;
BA_ "U_CD542_MY2021_Rx" SG_ 560 TrnGbox_Rt_Actl 1;
BA_ "U_CD764_MY2022_Rx" SG_ 560 TrnGbox_Rt_Actl 1;
BA_ "U_CX727_MY2021_Tx" SG_ 560 TrnGbox_Rt_Actl 1;
BA_ "U_CD542_MY2021_Tx" SG_ 560 TrnGbox_Rt_Actl 1;
BA_ "ContentDependant" SG_ 560 TrnSrvcRqd_B_Rq 1;
BA_ "U_T6_MCA_MY2020_Rx" SG_ 560 TrnSrvcRqd_B_Rq 1;
BA_ "ECGUsedRxSignal" SG_ 560 TrnSrvcRqd_B_Rq 1;
BA_ "U_CD542_MY2021_Rx" SG_ 560 TrnSrvcRqd_B_Rq 1;
BA_ "U_U55X_MY2022_Rx" SG_ 560 TrnSrvcRqd_B_Rq 1;
BA_ "U_CD764_MY2022_Rx" SG_ 560 TrnSrvcRqd_B_Rq 1;
BA_ "U_CX727_MY2021_Tx" SG_ 560 TrnSrvcRqd_B_Rq 1;
BA_ "U_P702_MY2021_Tx" SG_ 560 TrnSrvcRqd_B_Rq 1;
BA_ "U_T6_MCA_MY2020_Tx" SG_ 560 TrnSrvcRqd_B_Rq 1;
BA_ "U_CD542_MY2021_Tx" SG_ 560 TrnSrvcRqd_B_Rq 1;
BA_ "U_U55X_MY2022_Tx" SG_ 560 TrnSrvcRqd_B_Rq 1;
BA_ "U_CD764_MY2022_Tx" SG_ 560 TrnSrvcRqd_B_Rq 1;
BA_ "ContentDependant" SG_ 560 TrnCnvtClu_D_Actl 1;
BA_ "U_T6_MCA_MY2020_Rx" SG_ 560 TrnCnvtClu_D_Actl 1;
BA_ "U_CD542_MY2021_Rx" SG_ 560 TrnCnvtClu_D_Actl 1;
BA_ "U_CD764_MY2022_Rx" SG_ 560 TrnCnvtClu_D_Actl 1;
BA_ "U_CX727_MY2021_Tx" SG_ 560 TrnCnvtClu_D_Actl 1;
BA_ "U_T6_MCA_MY2020_Tx" SG_ 560 TrnCnvtClu_D_Actl 1;
BA_ "U_CD542_MY2021_Tx" SG_ 560 TrnCnvtClu_D_Actl 1;
BA_ "ContentDependant" SG_ 560 TrnShifActv_B_Actl 1;
BA_ "U_CX727_MY2021_Rx" SG_ 560 TrnShifActv_B_Actl 1;
BA_ "U_P702_MY2021_Rx" SG_ 560 TrnShifActv_B_Actl 1;
BA_ "U_T6_MCA_MY2020_Rx" SG_ 560 TrnShifActv_B_Actl 1;
BA_ "U_CD542_MY2021_Rx" SG_ 560 TrnShifActv_B_Actl 1;
BA_ "U_U55X_MY2022_Rx" SG_ 560 TrnShifActv_B_Actl 1;
BA_ "U_CD764_MY2022_Rx" SG_ 560 TrnShifActv_B_Actl 1;
BA_ "U_CX727_MY2021_Tx" SG_ 560 TrnShifActv_B_Actl 1;
BA_ "U_P702_MY2021_Tx" SG_ 560 TrnShifActv_B_Actl 1;
BA_ "U_T6_MCA_MY2020_Tx" SG_ 560 TrnShifActv_B_Actl 1;
BA_ "U_CD542_MY2021_Tx" SG_ 560 TrnShifActv_B_Actl 1;
BA_ "U_U55X_MY2022_Tx" SG_ 560 TrnShifActv_B_Actl 1;
BA_ "U_CD764_MY2022_Tx" SG_ 560 TrnShifActv_B_Actl 1;
BA_ "U_CX727_MY2021_Tx" SG_ 560 RtmTerrMdeChng_D_Rdy 1;
BA_ "U_CD542_MY2021_Tx" SG_ 560 RtmTerrMdeChng_D_Rdy 1;
BA_ "U_CX727_MY2021_Tx" SG_ 560 RtmTerrMde_D_Actl 1;
BA_ "U_CD542_MY2021_Tx" SG_ 560 RtmTerrMde_D_Actl 1;
BA_ "GenSigStartValueInteger" SG_ 560 GearLvrPos_D_Actl 14;
BA_ "GenSigStartValue" SG_ 560 GearLvrPos_D_Actl 14;
BA_ "U_CX727_MY2021_Rx" SG_ 560 GearLvrPos_D_Actl 1;
BA_ "U_P702_MY2021_Rx" SG_ 560 GearLvrPos_D_Actl 1;
BA_ "U_T6_MCA_MY2020_Rx" SG_ 560 GearLvrPos_D_Actl 1;
BA_ "U_CD542_MY2021_Rx" SG_ 560 GearLvrPos_D_Actl 1;
BA_ "U_U55X_MY2022_Rx" SG_ 560 GearLvrPos_D_Actl 1;
BA_ "U_CD764_MY2022_Rx" SG_ 560 GearLvrPos_D_Actl 1;
BA_ "U_CX727_MY2021_Tx" SG_ 560 GearLvrPos_D_Actl 1;
BA_ "U_P702_MY2021_Tx" SG_ 560 GearLvrPos_D_Actl 1;
BA_ "U_T6_MCA_MY2020_Tx" SG_ 560 GearLvrPos_D_Actl 1;
BA_ "U_CD542_MY2021_Tx" SG_ 560 GearLvrPos_D_Actl 1;
BA_ "U_U55X_MY2022_Tx" SG_ 560 GearLvrPos_D_Actl 1;
BA_ "U_CD764_MY2022_Tx" SG_ 560 GearLvrPos_D_Actl 1;
BA_ "GenSigStartValueInteger" SG_ 560 GboxOil_Te_Actl 254;
BA_ "ContentDependant" SG_ 560 GboxOil_Te_Actl 1;
BA_ "GenSigStartValue" SG_ 560 GboxOil_Te_Actl 254;
BA_ "U_CX727_MY2021_Rx" SG_ 560 GboxOil_Te_Actl 1;
BA_ "U_P702_MY2021_Rx" SG_ 560 GboxOil_Te_Actl 1;
BA_ "U_T6_MCA_MY2020_Rx" SG_ 560 GboxOil_Te_Actl 1;
BA_ "U_CD542_MY2021_Rx" SG_ 560 GboxOil_Te_Actl 1;
BA_ "U_U55X_MY2022_Rx" SG_ 560 GboxOil_Te_Actl 1;
BA_ "U_CX727_MY2021_Tx" SG_ 560 GboxOil_Te_Actl 1;
BA_ "U_P702_MY2021_Tx" SG_ 560 GboxOil_Te_Actl 1;
BA_ "U_T6_MCA_MY2020_Tx" SG_ 560 GboxOil_Te_Actl 1;
BA_ "U_CD542_MY2021_Tx" SG_ 560 GboxOil_Te_Actl 1;
BA_ "U_U55X_MY2022_Tx" SG_ 560 GboxOil_Te_Actl 1;
BA_ "U_CD764_MY2022_Tx" SG_ 560 GboxOil_Te_Actl 1;
BA_ "MetaData" SG_ 369 TrnIpcDsplyMdeDActl_No_Cs 1;
BA_ "ContentDependant" SG_ 369 TrnIpcDsplyMdeDActl_No_Cs 1;
BA_ "MetaData" SG_ 369 TrnIpcDsplyMdeDActl_No_Cnt 1;
BA_ "ContentDependant" SG_ 369 TrnIpcDsplyMdeDActl_No_Cnt 1;
BA_ "GenSigStartValueInteger" SG_ 369 TrnIpcDsplyRng2_D_Actl 15;
BA_ "GenSigStartValue" SG_ 369 TrnIpcDsplyRng2_D_Actl 15;
BA_ "U_P702_MY2021_Tx" SG_ 369 TrnIpcDsplyRng2_D_Actl 1;
BA_ "U_T6_MCA_MY2020_Tx" SG_ 369 TrnIpcDsplyRng2_D_Actl 1;
BA_ "U_U55X_MY2022_Tx" SG_ 369 TrnIpcDsplyRng2_D_Actl 1;
BA_ "U_P702_MY2021_Tx" SG_ 369 TrnIpcDsplyRng_D_Stat 1;
BA_ "U_T6_MCA_MY2020_Tx" SG_ 369 TrnIpcDsplyRng_D_Stat 1;
BA_ "U_U55X_MY2022_Tx" SG_ 369 TrnIpcDsplyRng_D_Stat 1;
BA_ "GenSigStartValueInteger" SG_ 369 PrplWhlScnd_Tq_Cmd 4;
BA_ "GenSigStartValue" SG_ 369 PrplWhlScnd_Tq_Cmd 2048;
BA_ "GenSigStartValueInteger" SG_ 369 PrplWhlPrim_Tq_Cmd 4;
BA_ "GenSigStartValue" SG_ 369 PrplWhlPrim_Tq_Cmd 2048;
BA_ "GenSigStartValueInteger" SG_ 369 TrnIpcDsplyGear_D_Actl 15;
BA_ "GenSigStartValue" SG_ 369 TrnIpcDsplyGear_D_Actl 15;
BA_ "U_P702_MY2021_Tx" SG_ 369 TrnIpcDsplyGear_D_Actl 1;
BA_ "U_T6_MCA_MY2020_Tx" SG_ 369 TrnIpcDsplyGear_D_Actl 1;
BA_ "U_CD542_MY2021_Tx" SG_ 369 TrnIpcDsplyGear_D_Actl 1;
BA_ "U_U55X_MY2022_Tx" SG_ 369 TrnIpcDsplyGear_D_Actl 1;
BA_ "U_CD764_MY2022_Tx" SG_ 369 TrnIpcDsplyGear_D_Actl 1;
BA_ "WakeupSignal" SG_ 369 TrnIpcDsplyMde_D_Stat 1;
BA_ "U_P702_MY2021_Tx" SG_ 369 TrnIpcDsplyMde_D_Stat 1;
BA_ "U_T6_MCA_MY2020_Tx" SG_ 369 TrnIpcDsplyMde_D_Stat 1;
BA_ "U_CD542_MY2021_Tx" SG_ 369 TrnIpcDsplyMde_D_Stat 1;
BA_ "U_U55X_MY2022_Tx" SG_ 369 TrnIpcDsplyMde_D_Stat 1;
BA_ "U_CD764_MY2022_Tx" SG_ 369 TrnIpcDsplyMde_D_Stat 1;
BA_ "WakeupSignal" SG_ 369 TrnIpcDsplyMde_D_Actl 1;
BA_ "U_P702_MY2021_Tx" SG_ 369 TrnIpcDsplyMde_D_Actl 1;
BA_ "U_T6_MCA_MY2020_Tx" SG_ 369 TrnIpcDsplyMde_D_Actl 1;
BA_ "U_CD542_MY2021_Tx" SG_ 369 TrnIpcDsplyMde_D_Actl 1;
BA_ "U_U55X_MY2022_Tx" SG_ 369 TrnIpcDsplyMde_D_Actl 1;
BA_ "U_CD764_MY2022_Tx" SG_ 369 TrnIpcDsplyMde_D_Actl 1;
BA_ "U_P702_MY2021_Tx" SG_ 369 TrnIpcDsplyGear_D_Stat 1;
BA_ "U_T6_MCA_MY2020_Tx" SG_ 369 TrnIpcDsplyGear_D_Stat 1;
BA_ "U_CD542_MY2021_Tx" SG_ 369 TrnIpcDsplyGear_D_Stat 1;
BA_ "U_U55X_MY2022_Tx" SG_ 369 TrnIpcDsplyGear_D_Stat 1;
BA_ "U_CD764_MY2022_Tx" SG_ 369 TrnIpcDsplyGear_D_Stat 1;
BA_ "GenSigSendType" SG_ 92 TrnGearMsgTxt2_D_Rq 3;
BA_ "ContentDependant" SG_ 92 TrnGearMsgTxt2_D_Rq 1;
BA_ "U_CD764_MY2022_Tx" SG_ 92 TrnGearMsgTxt2_D_Rq 1;
BA_ "GenSigSendType" SG_ 92 TrnSbwSysHlth_D_Actl 3;
BA_ "GenSigStartValueInteger" SG_ 92 TrnSbwSysHlth_D_Actl 1;
BA_ "ContentDependant" SG_ 92 TrnSbwSysHlth_D_Actl 1;
BA_ "GenSigStartValue" SG_ 92 TrnSbwSysHlth_D_Actl 1;
BA_ "U_CX727_MY2021_Tx" SG_ 92 TrnSbwSysHlth_D_Actl 1;
BA_ "U_P702_MY2021_Tx" SG_ 92 TrnSbwSysHlth_D_Actl 1;
BA_ "U_T6_MCA_MY2020_Tx" SG_ 92 TrnSbwSysHlth_D_Actl 1;
BA_ "U_CD542_MY2021_Tx" SG_ 92 TrnSbwSysHlth_D_Actl 1;
BA_ "GenSigSendType" SG_ 92 TrnLvrV_D_Rq 3;
BA_ "GenSigStartValueInteger" SG_ 92 TrnLvrV_D_Rq 1;
BA_ "GenSigStartValue" SG_ 92 TrnLvrV_D_Rq 1;
BA_ "U_CX727_MY2021_Tx" SG_ 92 TrnLvrV_D_Rq 1;
BA_ "U_P702_MY2021_Tx" SG_ 92 TrnLvrV_D_Rq 1;
BA_ "U_T6_MCA_MY2020_Tx" SG_ 92 TrnLvrV_D_Rq 1;
BA_ "U_CD542_MY2021_Tx" SG_ 92 TrnLvrV_D_Rq 1;
BA_ "U_U55X_MY2022_Tx" SG_ 92 TrnLvrV_D_Rq 1;
BA_ "U_CD764_MY2022_Tx" SG_ 92 TrnLvrV_D_Rq 1;
BA_ "GenSigSendType" SG_ 92 TrnGearNtmAllow_B_Stat 3;
BA_ "ContentDependant" SG_ 92 TrnGearNtmAllow_B_Stat 1;
BA_ "U_CX727_MY2021_Tx" SG_ 92 TrnGearNtmAllow_B_Stat 1;
BA_ "U_P702_MY2021_Tx" SG_ 92 TrnGearNtmAllow_B_Stat 1;
BA_ "U_T6_MCA_MY2020_Tx" SG_ 92 TrnGearNtmAllow_B_Stat 1;
BA_ "U_CD542_MY2021_Tx" SG_ 92 TrnGearNtmAllow_B_Stat 1;
BA_ "U_U55X_MY2022_Tx" SG_ 92 TrnGearNtmAllow_B_Stat 1;
BA_ "U_CD764_MY2022_Tx" SG_ 92 TrnGearNtmAllow_B_Stat 1;
BA_ "GenSigSendType" SG_ 92 TrnDtpCmd_D_Actl 3;
BA_ "WakeupSignal" SG_ 92 TrnDtpCmd_D_Actl 1;
BA_ "GenSigStartValueInteger" SG_ 92 TrnDtpCmd_D_Actl 1;
BA_ "ContentDependant" SG_ 92 TrnDtpCmd_D_Actl 1;
BA_ "GenSigStartValue" SG_ 92 TrnDtpCmd_D_Actl 1;
BA_ "U_CX727_MY2021_Tx" SG_ 92 TrnDtpCmd_D_Actl 1;
BA_ "U_P702_MY2021_Tx" SG_ 92 TrnDtpCmd_D_Actl 1;
BA_ "U_T6_MCA_MY2020_Tx" SG_ 92 TrnDtpCmd_D_Actl 1;
BA_ "U_CD542_MY2021_Tx" SG_ 92 TrnDtpCmd_D_Actl 1;
BA_ "U_U55X_MY2022_Tx" SG_ 92 TrnDtpCmd_D_Actl 1;
BA_ "U_CD764_MY2022_Tx" SG_ 92 TrnDtpCmd_D_Actl 1;
BA_ "GenSigSendType" SG_ 92 GearSelLck_D_Rq 3;
BA_ "U_CX727_MY2021_Tx" SG_ 92 GearSelLck_D_Rq 1;
BA_ "U_P702_MY2021_Tx" SG_ 92 GearSelLck_D_Rq 1;
BA_ "U_T6_MCA_MY2020_Tx" SG_ 92 GearSelLck_D_Rq 1;
BA_ "U_CD542_MY2021_Tx" SG_ 92 GearSelLck_D_Rq 1;
BA_ "U_U55X_MY2022_Tx" SG_ 92 GearSelLck_D_Rq 1;
BA_ "U_CD764_MY2022_Tx" SG_ 92 GearSelLck_D_Rq 1;
BA_ "ContentDependant" SG_ 92 TrnGearCmd_No_Cs 1;
BA_ "MetaData" SG_ 92 TrnGearCmd_No_Cs 1;
BA_ "U_CX727_MY2021_Tx" SG_ 92 TrnGearCmd_No_Cs 1;
BA_ "U_P702_MY2021_Tx" SG_ 92 TrnGearCmd_No_Cs 1;
BA_ "U_T6_MCA_MY2020_Tx" SG_ 92 TrnGearCmd_No_Cs 1;
BA_ "U_CD542_MY2021_Tx" SG_ 92 TrnGearCmd_No_Cs 1;
BA_ "U_U55X_MY2022_Tx" SG_ 92 TrnGearCmd_No_Cs 1;
BA_ "U_CD764_MY2022_Tx" SG_ 92 TrnGearCmd_No_Cs 1;
BA_ "GenSigSendType" SG_ 92 TrnValidGear_D_Cnfm 3;
BA_ "ContentDependant" SG_ 92 TrnValidGear_D_Cnfm 1;
BA_ "U_CX727_MY2021_Tx" SG_ 92 TrnValidGear_D_Cnfm 1;
BA_ "U_P702_MY2021_Tx" SG_ 92 TrnValidGear_D_Cnfm 1;
BA_ "U_T6_MCA_MY2020_Tx" SG_ 92 TrnValidGear_D_Cnfm 1;
BA_ "U_CD542_MY2021_Tx" SG_ 92 TrnValidGear_D_Cnfm 1;
BA_ "U_U55X_MY2022_Tx" SG_ 92 TrnValidGear_D_Cnfm 1;
BA_ "U_CD764_MY2022_Tx" SG_ 92 TrnValidGear_D_Cnfm 1;
BA_ "GenSigSendType" SG_ 92 TrnNtrlTowCmd_D_Actl 3;
BA_ "ContentDependant" SG_ 92 TrnNtrlTowCmd_D_Actl 1;
BA_ "U_CX727_MY2021_Rx" SG_ 92 TrnNtrlTowCmd_D_Actl 1;
BA_ "U_P702_MY2021_Rx" SG_ 92 TrnNtrlTowCmd_D_Actl 1;
BA_ "U_T6_MCA_MY2020_Rx" SG_ 92 TrnNtrlTowCmd_D_Actl 1;
BA_ "U_CD542_MY2021_Rx" SG_ 92 TrnNtrlTowCmd_D_Actl 1;
BA_ "U_U55X_MY2022_Rx" SG_ 92 TrnNtrlTowCmd_D_Actl 1;
BA_ "U_CD764_MY2022_Rx" SG_ 92 TrnNtrlTowCmd_D_Actl 1;
BA_ "U_CX727_MY2021_Tx" SG_ 92 TrnNtrlTowCmd_D_Actl 1;
BA_ "U_P702_MY2021_Tx" SG_ 92 TrnNtrlTowCmd_D_Actl 1;
BA_ "U_T6_MCA_MY2020_Tx" SG_ 92 TrnNtrlTowCmd_D_Actl 1;
BA_ "U_CD542_MY2021_Tx" SG_ 92 TrnNtrlTowCmd_D_Actl 1;
BA_ "U_U55X_MY2022_Tx" SG_ 92 TrnNtrlTowCmd_D_Actl 1;
BA_ "U_CD764_MY2022_Tx" SG_ 92 TrnNtrlTowCmd_D_Actl 1;
BA_ "ContentDependant" SG_ 92 TrnGearCmd_Pc_ActlPt 1;
BA_ "U_CX727_MY2021_Tx" SG_ 92 TrnGearCmd_Pc_ActlPt 1;
BA_ "U_P702_MY2021_Tx" SG_ 92 TrnGearCmd_Pc_ActlPt 1;
BA_ "U_T6_MCA_MY2020_Tx" SG_ 92 TrnGearCmd_Pc_ActlPt 1;
BA_ "U_CD542_MY2021_Tx" SG_ 92 TrnGearCmd_Pc_ActlPt 1;
BA_ "U_U55X_MY2022_Tx" SG_ 92 TrnGearCmd_Pc_ActlPt 1;
BA_ "U_CD764_MY2022_Tx" SG_ 92 TrnGearCmd_Pc_ActlPt 1;
BA_ "GenSigSendType" SG_ 92 TrnGear_D_RqPt 3;
BA_ "ContentDependant" SG_ 92 TrnGear_D_RqPt 1;
BA_ "U_CX727_MY2021_Tx" SG_ 92 TrnGear_D_RqPt 1;
BA_ "U_P702_MY2021_Tx" SG_ 92 TrnGear_D_RqPt 1;
BA_ "U_T6_MCA_MY2020_Tx" SG_ 92 TrnGear_D_RqPt 1;
BA_ "U_CD542_MY2021_Tx" SG_ 92 TrnGear_D_RqPt 1;
BA_ "U_U55X_MY2022_Tx" SG_ 92 TrnGear_D_RqPt 1;
BA_ "U_CD764_MY2022_Tx" SG_ 92 TrnGear_D_RqPt 1;
BA_ "GenSigSendType" SG_ 92 TrnCmdState_B_Actl 3;
BA_ "ContentDependant" SG_ 92 TrnCmdState_B_Actl 1;
BA_ "U_CX727_MY2021_Tx" SG_ 92 TrnCmdState_B_Actl 1;
BA_ "U_P702_MY2021_Tx" SG_ 92 TrnCmdState_B_Actl 1;
BA_ "U_T6_MCA_MY2020_Tx" SG_ 92 TrnCmdState_B_Actl 1;
BA_ "U_CD542_MY2021_Tx" SG_ 92 TrnCmdState_B_Actl 1;
BA_ "U_U55X_MY2022_Tx" SG_ 92 TrnCmdState_B_Actl 1;
BA_ "U_CD764_MY2022_Tx" SG_ 92 TrnCmdState_B_Actl 1;
BA_ "ContentDependant" SG_ 92 TrnCmdCnt_B_Actl 1;
BA_ "U_CX727_MY2021_Tx" SG_ 92 TrnCmdCnt_B_Actl 1;
BA_ "U_P702_MY2021_Tx" SG_ 92 TrnCmdCnt_B_Actl 1;
BA_ "U_T6_MCA_MY2020_Tx" SG_ 92 TrnCmdCnt_B_Actl 1;
BA_ "U_CD542_MY2021_Tx" SG_ 92 TrnCmdCnt_B_Actl 1;
BA_ "U_U55X_MY2022_Tx" SG_ 92 TrnCmdCnt_B_Actl 1;
BA_ "U_CD764_MY2022_Tx" SG_ 92 TrnCmdCnt_B_Actl 1;
BA_ "GenSigSendType" SG_ 92 PrkBrkActv_D_RqTrnGear 3;
BA_ "GenSigStartValueInteger" SG_ 92 PrkBrkActv_D_RqTrnGear 1;
BA_ "ContentDependant" SG_ 92 PrkBrkActv_D_RqTrnGear 1;
BA_ "GenSigStartValue" SG_ 92 PrkBrkActv_D_RqTrnGear 1;
BA_ "U_CX727_MY2021_Rx" SG_ 92 PrkBrkActv_D_RqTrnGear 1;
BA_ "U_P702_MY2021_Rx" SG_ 92 PrkBrkActv_D_RqTrnGear 1;
BA_ "U_T6_MCA_MY2020_Rx" SG_ 92 PrkBrkActv_D_RqTrnGear 1;
BA_ "U_CD542_MY2021_Rx" SG_ 92 PrkBrkActv_D_RqTrnGear 1;
BA_ "U_U55X_MY2022_Rx" SG_ 92 PrkBrkActv_D_RqTrnGear 1;
BA_ "U_CD764_MY2022_Rx" SG_ 92 PrkBrkActv_D_RqTrnGear 1;
BA_ "U_CX727_MY2021_Tx" SG_ 92 PrkBrkActv_D_RqTrnGear 1;
BA_ "U_P702_MY2021_Tx" SG_ 92 PrkBrkActv_D_RqTrnGear 1;
BA_ "U_T6_MCA_MY2020_Tx" SG_ 92 PrkBrkActv_D_RqTrnGear 1;
BA_ "U_CD542_MY2021_Tx" SG_ 92 PrkBrkActv_D_RqTrnGear 1;
BA_ "U_U55X_MY2022_Tx" SG_ 92 PrkBrkActv_D_RqTrnGear 1;
BA_ "U_CD764_MY2022_Tx" SG_ 92 PrkBrkActv_D_RqTrnGear 1;
BA_ "GenSigSendType" SG_ 92 TrnGearMsgTxt_D_Rq 3;
BA_ "ContentDependant" SG_ 92 TrnGearMsgTxt_D_Rq 1;
BA_ "U_CX727_MY2021_Tx" SG_ 92 TrnGearMsgTxt_D_Rq 1;
BA_ "U_P702_MY2021_Tx" SG_ 92 TrnGearMsgTxt_D_Rq 1;
BA_ "U_T6_MCA_MY2020_Tx" SG_ 92 TrnGearMsgTxt_D_Rq 1;
BA_ "U_CD542_MY2021_Tx" SG_ 92 TrnGearMsgTxt_D_Rq 1;
BA_ "U_U55X_MY2022_Tx" SG_ 92 TrnGearMsgTxt_D_Rq 1;
BA_ "U_CD764_MY2022_Tx" SG_ 92 TrnGearMsgTxt_D_Rq 1;
BA_ "ContentDependant" SG_ 92 TrnGearCmd_No_Cnt 1;
BA_ "MetaData" SG_ 92 TrnGearCmd_No_Cnt 1;
BA_ "U_CX727_MY2021_Tx" SG_ 92 TrnGearCmd_No_Cnt 1;
BA_ "U_P702_MY2021_Tx" SG_ 92 TrnGearCmd_No_Cnt 1;
BA_ "U_T6_MCA_MY2020_Tx" SG_ 92 TrnGearCmd_No_Cnt 1;
BA_ "U_CD542_MY2021_Tx" SG_ 92 TrnGearCmd_No_Cnt 1;
BA_ "U_U55X_MY2022_Tx" SG_ 92 TrnGearCmd_No_Cnt 1;
BA_ "U_CD764_MY2022_Tx" SG_ 92 TrnGearCmd_No_Cnt 1;
BA_ "GenSigSendType" SG_ 2030 TesterPhysicalResSOBDMC 3;
BA_ "U_CX727_MY2021_Tx" SG_ 2030 TesterPhysicalResSOBDMC 1;
BA_ "U_P702_MY2021_Tx" SG_ 2030 TesterPhysicalResSOBDMC 1;
BA_ "U_T6_MCA_MY2020_Tx" SG_ 2030 TesterPhysicalResSOBDMC 1;
BA_ "U_CD542_MY2021_Tx" SG_ 2030 TesterPhysicalResSOBDMC 1;
BA_ "GenSigSendType" SG_ 1087 FapLcInhbt_B_Rq 3;
BA_ "U_T6_MCA_MY2020_Rx" SG_ 1087 FapLcInhbt_B_Rq 1;
BA_ "U_U55X_MY2022_Rx" SG_ 1087 FapLcInhbt_B_Rq 1;
BA_ "U_CX727_MY2021_Tx" SG_ 1087 FapLcInhbt_B_Rq 1;
BA_ "U_P702_MY2021_Tx" SG_ 1087 FapLcInhbt_B_Rq 1;
BA_ "U_T6_MCA_MY2020_Tx" SG_ 1087 FapLcInhbt_B_Rq 1;
BA_ "U_CD542_MY2021_Tx" SG_ 1087 FapLcInhbt_B_Rq 1;
BA_ "U_CD764_MY2022_Tx" SG_ 1087 FapLcInhbt_B_Rq 1;
BA_ "GenSigSendType" SG_ 1087 RepaLcGrdInhbt_B_Stat 3;
BA_ "U_U55X_MY2022_Rx" SG_ 1087 RepaLcGrdInhbt_B_Stat 1;
BA_ "U_CD764_MY2022_Rx" SG_ 1087 RepaLcGrdInhbt_B_Stat 1;
BA_ "GenSigSendType" SG_ 1087 FapLcStopHold_B_Rq 3;
BA_ "U_CX727_MY2021_Rx" SG_ 1087 FapLcStopHold_B_Rq 1;
BA_ "U_P702_MY2021_Rx" SG_ 1087 FapLcStopHold_B_Rq 1;
BA_ "U_T6_MCA_MY2020_Rx" SG_ 1087 FapLcStopHold_B_Rq 1;
BA_ "U_CD542_MY2021_Rx" SG_ 1087 FapLcStopHold_B_Rq 1;
BA_ "U_U55X_MY2022_Rx" SG_ 1087 FapLcStopHold_B_Rq 1;
BA_ "U_CD764_MY2022_Rx" SG_ 1087 FapLcStopHold_B_Rq 1;
BA_ "U_CX727_MY2021_Tx" SG_ 1087 FapLcStopHold_B_Rq 1;
BA_ "U_P702_MY2021_Tx" SG_ 1087 FapLcStopHold_B_Rq 1;
BA_ "U_T6_MCA_MY2020_Tx" SG_ 1087 FapLcStopHold_B_Rq 1;
BA_ "U_CD542_MY2021_Tx" SG_ 1087 FapLcStopHold_B_Rq 1;
BA_ "U_CD764_MY2022_Tx" SG_ 1087 FapLcStopHold_B_Rq 1;
BA_ "GenSigSendType" SG_ 1087 FapLcPrchgBrk_B_Rq 3;
BA_ "U_CX727_MY2021_Rx" SG_ 1087 FapLcPrchgBrk_B_Rq 1;
BA_ "U_P702_MY2021_Rx" SG_ 1087 FapLcPrchgBrk_B_Rq 1;
BA_ "U_T6_MCA_MY2020_Rx" SG_ 1087 FapLcPrchgBrk_B_Rq 1;
BA_ "U_CD542_MY2021_Rx" SG_ 1087 FapLcPrchgBrk_B_Rq 1;
BA_ "U_U55X_MY2022_Rx" SG_ 1087 FapLcPrchgBrk_B_Rq 1;
BA_ "U_CD764_MY2022_Rx" SG_ 1087 FapLcPrchgBrk_B_Rq 1;
BA_ "U_CX727_MY2021_Tx" SG_ 1087 FapLcPrchgBrk_B_Rq 1;
BA_ "U_P702_MY2021_Tx" SG_ 1087 FapLcPrchgBrk_B_Rq 1;
BA_ "U_T6_MCA_MY2020_Tx" SG_ 1087 FapLcPrchgBrk_B_Rq 1;
BA_ "U_CD542_MY2021_Tx" SG_ 1087 FapLcPrchgBrk_B_Rq 1;
BA_ "U_CD764_MY2022_Tx" SG_ 1087 FapLcPrchgBrk_B_Rq 1;
BA_ "GenSigSendType" SG_ 1087 FapLcObstcl_B_Stat 3;
BA_ "U_T6_MCA_MY2020_Rx" SG_ 1087 FapLcObstcl_B_Stat 1;
BA_ "U_CD542_MY2021_Rx" SG_ 1087 FapLcObstcl_B_Stat 1;
BA_ "U_U55X_MY2022_Rx" SG_ 1087 FapLcObstcl_B_Stat 1;
BA_ "U_CD764_MY2022_Rx" SG_ 1087 FapLcObstcl_B_Stat 1;
BA_ "U_CX727_MY2021_Tx" SG_ 1087 FapLcObstcl_B_Stat 1;
BA_ "U_P702_MY2021_Tx" SG_ 1087 FapLcObstcl_B_Stat 1;
BA_ "U_T6_MCA_MY2020_Tx" SG_ 1087 FapLcObstcl_B_Stat 1;
BA_ "U_CD542_MY2021_Tx" SG_ 1087 FapLcObstcl_B_Stat 1;
BA_ "U_CD764_MY2022_Tx" SG_ 1087 FapLcObstcl_B_Stat 1;
BA_ "GenSigSendType" SG_ 1087 FapLcMaxGrdInhbt_B_Stat 3;
BA_ "U_T6_MCA_MY2020_Rx" SG_ 1087 FapLcMaxGrdInhbt_B_Stat 1;
BA_ "U_CD542_MY2021_Rx" SG_ 1087 FapLcMaxGrdInhbt_B_Stat 1;
BA_ "U_U55X_MY2022_Rx" SG_ 1087 FapLcMaxGrdInhbt_B_Stat 1;
BA_ "U_CD764_MY2022_Rx" SG_ 1087 FapLcMaxGrdInhbt_B_Stat 1;
BA_ "U_CX727_MY2021_Tx" SG_ 1087 FapLcMaxGrdInhbt_B_Stat 1;
BA_ "U_P702_MY2021_Tx" SG_ 1087 FapLcMaxGrdInhbt_B_Stat 1;
BA_ "U_T6_MCA_MY2020_Tx" SG_ 1087 FapLcMaxGrdInhbt_B_Stat 1;
BA_ "U_CD542_MY2021_Tx" SG_ 1087 FapLcMaxGrdInhbt_B_Stat 1;
BA_ "U_CD764_MY2022_Tx" SG_ 1087 FapLcMaxGrdInhbt_B_Stat 1;
BA_ "GenSigSendType" SG_ 1087 FapLcMaxGrdAbrt_B_Stat 3;
BA_ "U_T6_MCA_MY2020_Rx" SG_ 1087 FapLcMaxGrdAbrt_B_Stat 1;
BA_ "U_CD542_MY2021_Rx" SG_ 1087 FapLcMaxGrdAbrt_B_Stat 1;
BA_ "U_U55X_MY2022_Rx" SG_ 1087 FapLcMaxGrdAbrt_B_Stat 1;
BA_ "U_CD764_MY2022_Rx" SG_ 1087 FapLcMaxGrdAbrt_B_Stat 1;
BA_ "U_CX727_MY2021_Tx" SG_ 1087 FapLcMaxGrdAbrt_B_Stat 1;
BA_ "U_P702_MY2021_Tx" SG_ 1087 FapLcMaxGrdAbrt_B_Stat 1;
BA_ "U_T6_MCA_MY2020_Tx" SG_ 1087 FapLcMaxGrdAbrt_B_Stat 1;
BA_ "U_CD542_MY2021_Tx" SG_ 1087 FapLcMaxGrdAbrt_B_Stat 1;
BA_ "U_CD764_MY2022_Tx" SG_ 1087 FapLcMaxGrdAbrt_B_Stat 1;
BA_ "GenSigSendType" SG_ 1087 FapLcActv_B_Stat 3;
BA_ "U_T6_MCA_MY2020_Rx" SG_ 1087 FapLcActv_B_Stat 1;
BA_ "U_CD542_MY2021_Rx" SG_ 1087 FapLcActv_B_Stat 1;
BA_ "U_U55X_MY2022_Rx" SG_ 1087 FapLcActv_B_Stat 1;
BA_ "U_CD764_MY2022_Rx" SG_ 1087 FapLcActv_B_Stat 1;
BA_ "U_CX727_MY2021_Tx" SG_ 1087 FapLcActv_B_Stat 1;
BA_ "U_P702_MY2021_Tx" SG_ 1087 FapLcActv_B_Stat 1;
BA_ "U_T6_MCA_MY2020_Tx" SG_ 1087 FapLcActv_B_Stat 1;
BA_ "U_CD542_MY2021_Tx" SG_ 1087 FapLcActv_B_Stat 1;
BA_ "U_CD764_MY2022_Tx" SG_ 1087 FapLcActv_B_Stat 1;
BA_ "GenSigSendType" SG_ 1087 AdasLcObtclAbrt_B_Stat 3;
BA_ "U_T6_MCA_MY2020_Rx" SG_ 1087 AdasLcObtclAbrt_B_Stat 1;
BA_ "U_CD542_MY2021_Rx" SG_ 1087 AdasLcObtclAbrt_B_Stat 1;
BA_ "U_U55X_MY2022_Rx" SG_ 1087 AdasLcObtclAbrt_B_Stat 1;
BA_ "U_CD764_MY2022_Rx" SG_ 1087 AdasLcObtclAbrt_B_Stat 1;
BA_ "U_T6_MCA_MY2020_Tx" SG_ 1087 AdasLcObtclAbrt_B_Stat 1;
BA_ "U_CD542_MY2021_Tx" SG_ 1087 AdasLcObtclAbrt_B_Stat 1;
BA_ "U_CD764_MY2022_Tx" SG_ 1087 AdasLcObtclAbrt_B_Stat 1;
BA_ "GenSigSendType" SG_ 1896 TesterPhysicalResABS 3;
BA_ "U_CX727_MY2021_Tx" SG_ 1896 TesterPhysicalResABS 1;
BA_ "U_P702_MY2021_Tx" SG_ 1896 TesterPhysicalResABS 1;
BA_ "U_T6_MCA_MY2020_Tx" SG_ 1896 TesterPhysicalResABS 1;
BA_ "U_CD542_MY2021_Tx" SG_ 1896 TesterPhysicalResABS 1;
BA_ "U_U55X_MY2022_Tx" SG_ 1896 TesterPhysicalResABS 1;
BA_ "U_CD764_MY2022_Tx" SG_ 1896 TesterPhysicalResABS 1;
BA_ "GenSigSendType" SG_ 1888 TesterPhysicalReqABS 3;
BA_ "U_CX727_MY2021_Rx" SG_ 1888 TesterPhysicalReqABS 1;
BA_ "U_P702_MY2021_Rx" SG_ 1888 TesterPhysicalReqABS 1;
BA_ "U_T6_MCA_MY2020_Rx" SG_ 1888 TesterPhysicalReqABS 1;
BA_ "U_CD542_MY2021_Rx" SG_ 1888 TesterPhysicalReqABS 1;
BA_ "U_U55X_MY2022_Rx" SG_ 1888 TesterPhysicalReqABS 1;
BA_ "U_CD764_MY2022_Rx" SG_ 1888 TesterPhysicalReqABS 1;
BA_ "U_CX727_MY2021_Tx" SG_ 1848 TesterPhysicalResPSCM 1;
BA_ "U_P702_MY2021_Tx" SG_ 1848 TesterPhysicalResPSCM 1;
BA_ "U_T6_MCA_MY2020_Tx" SG_ 1848 TesterPhysicalResPSCM 1;
BA_ "U_CD542_MY2021_Tx" SG_ 1848 TesterPhysicalResPSCM 1;
BA_ "U_U55X_MY2022_Tx" SG_ 1848 TesterPhysicalResPSCM 1;
BA_ "U_CD764_MY2022_Tx" SG_ 1848 TesterPhysicalResPSCM 1;
BA_ "GenSigSendType" SG_ 1840 TesterPhysicalReqPSCM 3;
BA_ "U_CX727_MY2021_Rx" SG_ 1840 TesterPhysicalReqPSCM 1;
BA_ "U_P702_MY2021_Rx" SG_ 1840 TesterPhysicalReqPSCM 1;
BA_ "U_T6_MCA_MY2020_Rx" SG_ 1840 TesterPhysicalReqPSCM 1;
BA_ "U_CD542_MY2021_Rx" SG_ 1840 TesterPhysicalReqPSCM 1;
BA_ "U_U55X_MY2022_Rx" SG_ 1840 TesterPhysicalReqPSCM 1;
BA_ "U_CD764_MY2022_Rx" SG_ 1840 TesterPhysicalReqPSCM 1;
BA_ "U_P702_MY2021_Tx" SG_ 1713 UUDTABSResponse2 1;
BA_ "U_T6_MCA_MY2020_Tx" SG_ 1713 UUDTABSResponse2 1;
BA_ "U_CD542_MY2021_Tx" SG_ 1713 UUDTABSResponse2 1;
BA_ "U_U55X_MY2022_Tx" SG_ 1713 UUDTABSResponse2 1;
BA_ "U_CD764_MY2022_Tx" SG_ 1713 UUDTABSResponse2 1;
BA_ "U_P702_MY2021_Tx" SG_ 1712 UUDTABSResponse1 1;
BA_ "U_T6_MCA_MY2020_Tx" SG_ 1712 UUDTABSResponse1 1;
BA_ "U_CD542_MY2021_Tx" SG_ 1712 UUDTABSResponse1 1;
BA_ "U_U55X_MY2022_Tx" SG_ 1712 UUDTABSResponse1 1;
BA_ "U_CD764_MY2022_Tx" SG_ 1712 UUDTABSResponse1 1;
BA_ "U_CX727_MY2021_Tx" SG_ 2024 TesterPhysicalResPCM 1;
BA_ "U_P702_MY2021_Tx" SG_ 2024 TesterPhysicalResPCM 1;
BA_ "U_T6_MCA_MY2020_Tx" SG_ 2024 TesterPhysicalResPCM 1;
BA_ "U_CD542_MY2021_Tx" SG_ 2024 TesterPhysicalResPCM 1;
BA_ "U_U55X_MY2022_Tx" SG_ 2024 TesterPhysicalResPCM 1;
BA_ "U_CD764_MY2022_Tx" SG_ 2024 TesterPhysicalResPCM 1;
BA_ "GenSigSendType" SG_ 2016 TesterPhysicalReqPCM 3;
BA_ "U_CX727_MY2021_Rx" SG_ 2016 TesterPhysicalReqPCM 1;
BA_ "U_P702_MY2021_Rx" SG_ 2016 TesterPhysicalReqPCM 1;
BA_ "U_T6_MCA_MY2020_Rx" SG_ 2016 TesterPhysicalReqPCM 1;
BA_ "U_CD542_MY2021_Rx" SG_ 2016 TesterPhysicalReqPCM 1;
BA_ "U_U55X_MY2022_Rx" SG_ 2016 TesterPhysicalReqPCM 1;
BA_ "U_CD764_MY2022_Rx" SG_ 2016 TesterPhysicalReqPCM 1;
BA_ "GenSigSendType" SG_ 2015 TesterFunctionalReq 3;
BA_ "U_CX727_MY2021_Rx" SG_ 2015 TesterFunctionalReq 1;
BA_ "U_P702_MY2021_Rx" SG_ 2015 TesterFunctionalReq 1;
BA_ "U_T6_MCA_MY2020_Rx" SG_ 2015 TesterFunctionalReq 1;
BA_ "ECGUsedRxSignal" SG_ 2015 TesterFunctionalReq 1;
BA_ "U_CD542_MY2021_Rx" SG_ 2015 TesterFunctionalReq 1;
BA_ "U_U55X_MY2022_Rx" SG_ 2015 TesterFunctionalReq 1;
BA_ "U_CD764_MY2022_Rx" SG_ 2015 TesterFunctionalReq 1;
BA_ "GenSigSendType" SG_ 1814 TesterPhysicalReqGWM_F1 3;
BA_ "U_T6_MCA_MY2020_Rx" SG_ 1814 TesterPhysicalReqGWM_F1 1;
BA_ "ECGUsedRxSignal" SG_ 1814 TesterPhysicalReqGWM_F1 1;
BA_ "U_CD542_MY2021_Rx" SG_ 1814 TesterPhysicalReqGWM_F1 1;
BA_ "U_U55X_MY2022_Rx" SG_ 1814 TesterPhysicalReqGWM_F1 1;
BA_ "U_CD764_MY2022_Rx" SG_ 1814 TesterPhysicalReqGWM_F1 1;
BA_ "U_CX727_MY2021_Tx" SG_ 1697 UUDTPCMResponse2 1;
BA_ "U_P702_MY2021_Tx" SG_ 1697 UUDTPCMResponse2 1;
BA_ "U_T6_MCA_MY2020_Tx" SG_ 1697 UUDTPCMResponse2 1;
BA_ "U_CD542_MY2021_Tx" SG_ 1697 UUDTPCMResponse2 1;
BA_ "U_U55X_MY2022_Tx" SG_ 1697 UUDTPCMResponse2 1;
BA_ "U_CD764_MY2022_Tx" SG_ 1697 UUDTPCMResponse2 1;
BA_ "U_CX727_MY2021_Tx" SG_ 1696 UUDTPCMResponse1 1;
BA_ "U_P702_MY2021_Tx" SG_ 1696 UUDTPCMResponse1 1;
BA_ "U_T6_MCA_MY2020_Tx" SG_ 1696 UUDTPCMResponse1 1;
BA_ "U_CD542_MY2021_Tx" SG_ 1696 UUDTPCMResponse1 1;
BA_ "U_U55X_MY2022_Tx" SG_ 1696 UUDTPCMResponse1 1;
BA_ "U_CD764_MY2022_Tx" SG_ 1696 UUDTPCMResponse1 1;
BA_ "GenSigStartValueInteger" SG_ 1429 PCM_GWOnBoardTester 255;
BA_ "ContentDependant" SG_ 1429 PCM_GWOnBoardTester 1;
BA_ "GenSigStartValue" SG_ 1429 PCM_GWOnBoardTester 255;
BA_ "U_P702_MY2021_Rx" SG_ 1429 PCM_GWOnBoardTester 1;
BA_ "U_T6_MCA_MY2020_Rx" SG_ 1429 PCM_GWOnBoardTester 1;
BA_ "U_CX727_MY2021_Tx" SG_ 1429 PCM_GWOnBoardTester 1;
BA_ "U_P702_MY2021_Tx" SG_ 1429 PCM_GWOnBoardTester 1;
BA_ "U_T6_MCA_MY2020_Tx" SG_ 1429 PCM_GWOnBoardTester 1;
BA_ "U_CD542_MY2021_Tx" SG_ 1429 PCM_GWOnBoardTester 1;
BA_ "U_U55X_MY2022_Tx" SG_ 1429 PCM_GWOnBoardTester 1;
BA_ "U_CD764_MY2022_Tx" SG_ 1429 PCM_GWOnBoardTester 1;
BA_ "GenSigStartValueInteger" SG_ 1429 PCM_GWNMProxy 255;
BA_ "ContentDependant" SG_ 1429 PCM_GWNMProxy 1;
BA_ "GenSigStartValue" SG_ 1429 PCM_GWNMProxy 255;
BA_ "U_P702_MY2021_Rx" SG_ 1429 PCM_GWNMProxy 1;
BA_ "U_T6_MCA_MY2020_Rx" SG_ 1429 PCM_GWNMProxy 1;
BA_ "U_CX727_MY2021_Tx" SG_ 1429 PCM_GWNMProxy 1;
BA_ "U_P702_MY2021_Tx" SG_ 1429 PCM_GWNMProxy 1;
BA_ "U_T6_MCA_MY2020_Tx" SG_ 1429 PCM_GWNMProxy 1;
BA_ "U_CD542_MY2021_Tx" SG_ 1429 PCM_GWNMProxy 1;
BA_ "U_U55X_MY2022_Tx" SG_ 1429 PCM_GWNMProxy 1;
BA_ "U_CD764_MY2022_Tx" SG_ 1429 PCM_GWNMProxy 1;
BA_ "GenSigStartValueInteger" SG_ 1429 PCM_AutoSarNMReserved4 255;
BA_ "ContentDependant" SG_ 1429 PCM_AutoSarNMReserved4 1;
BA_ "GenSigStartValue" SG_ 1429 PCM_AutoSarNMReserved4 255;
BA_ "U_P702_MY2021_Rx" SG_ 1429 PCM_AutoSarNMReserved4 1;
BA_ "U_T6_MCA_MY2020_Rx" SG_ 1429 PCM_AutoSarNMReserved4 1;
BA_ "U_CX727_MY2021_Tx" SG_ 1429 PCM_AutoSarNMReserved4 1;
BA_ "U_P702_MY2021_Tx" SG_ 1429 PCM_AutoSarNMReserved4 1;
BA_ "U_T6_MCA_MY2020_Tx" SG_ 1429 PCM_AutoSarNMReserved4 1;
BA_ "U_CD542_MY2021_Tx" SG_ 1429 PCM_AutoSarNMReserved4 1;
BA_ "U_U55X_MY2022_Tx" SG_ 1429 PCM_AutoSarNMReserved4 1;
BA_ "U_CD764_MY2022_Tx" SG_ 1429 PCM_AutoSarNMReserved4 1;
BA_ "GenSigStartValueInteger" SG_ 1429 PCM_AutoSarNMReserved3 255;
BA_ "ContentDependant" SG_ 1429 PCM_AutoSarNMReserved3 1;
BA_ "GenSigStartValue" SG_ 1429 PCM_AutoSarNMReserved3 255;
BA_ "U_P702_MY2021_Rx" SG_ 1429 PCM_AutoSarNMReserved3 1;
BA_ "U_T6_MCA_MY2020_Rx" SG_ 1429 PCM_AutoSarNMReserved3 1;
BA_ "U_CX727_MY2021_Tx" SG_ 1429 PCM_AutoSarNMReserved3 1;
BA_ "U_P702_MY2021_Tx" SG_ 1429 PCM_AutoSarNMReserved3 1;
BA_ "U_T6_MCA_MY2020_Tx" SG_ 1429 PCM_AutoSarNMReserved3 1;
BA_ "U_CD542_MY2021_Tx" SG_ 1429 PCM_AutoSarNMReserved3 1;
BA_ "U_U55X_MY2022_Tx" SG_ 1429 PCM_AutoSarNMReserved3 1;
BA_ "U_CD764_MY2022_Tx" SG_ 1429 PCM_AutoSarNMReserved3 1;
BA_ "GenSigStartValueInteger" SG_ 1429 PCM_AutoSarNMReserved2 255;
BA_ "ContentDependant" SG_ 1429 PCM_AutoSarNMReserved2 1;
BA_ "GenSigStartValue" SG_ 1429 PCM_AutoSarNMReserved2 255;
BA_ "U_P702_MY2021_Rx" SG_ 1429 PCM_AutoSarNMReserved2 1;
BA_ "U_T6_MCA_MY2020_Rx" SG_ 1429 PCM_AutoSarNMReserved2 1;
BA_ "U_CX727_MY2021_Tx" SG_ 1429 PCM_AutoSarNMReserved2 1;
BA_ "U_P702_MY2021_Tx" SG_ 1429 PCM_AutoSarNMReserved2 1;
BA_ "U_T6_MCA_MY2020_Tx" SG_ 1429 PCM_AutoSarNMReserved2 1;
BA_ "U_CD542_MY2021_Tx" SG_ 1429 PCM_AutoSarNMReserved2 1;
BA_ "U_U55X_MY2022_Tx" SG_ 1429 PCM_AutoSarNMReserved2 1;
BA_ "U_CD764_MY2022_Tx" SG_ 1429 PCM_AutoSarNMReserved2 1;
BA_ "GenSigStartValueInteger" SG_ 1429 PCM_AutoSarNMReserved1 255;
BA_ "ContentDependant" SG_ 1429 PCM_AutoSarNMReserved1 1;
BA_ "GenSigStartValue" SG_ 1429 PCM_AutoSarNMReserved1 255;
BA_ "U_P702_MY2021_Rx" SG_ 1429 PCM_AutoSarNMReserved1 1;
BA_ "U_T6_MCA_MY2020_Rx" SG_ 1429 PCM_AutoSarNMReserved1 1;
BA_ "U_CX727_MY2021_Tx" SG_ 1429 PCM_AutoSarNMReserved1 1;
BA_ "U_P702_MY2021_Tx" SG_ 1429 PCM_AutoSarNMReserved1 1;
BA_ "U_T6_MCA_MY2020_Tx" SG_ 1429 PCM_AutoSarNMReserved1 1;
BA_ "U_CD542_MY2021_Tx" SG_ 1429 PCM_AutoSarNMReserved1 1;
BA_ "U_U55X_MY2022_Tx" SG_ 1429 PCM_AutoSarNMReserved1 1;
BA_ "U_CD764_MY2022_Tx" SG_ 1429 PCM_AutoSarNMReserved1 1;
BA_ "GenSigStartValueInteger" SG_ 1429 PCM_AutoSarNMNodeId 149;
BA_ "ContentDependant" SG_ 1429 PCM_AutoSarNMNodeId 1;
BA_ "GenSigStartValue" SG_ 1429 PCM_AutoSarNMNodeId 149;
BA_ "U_P702_MY2021_Rx" SG_ 1429 PCM_AutoSarNMNodeId 1;
BA_ "U_T6_MCA_MY2020_Rx" SG_ 1429 PCM_AutoSarNMNodeId 1;
BA_ "U_CX727_MY2021_Tx" SG_ 1429 PCM_AutoSarNMNodeId 1;
BA_ "U_P702_MY2021_Tx" SG_ 1429 PCM_AutoSarNMNodeId 1;
BA_ "U_T6_MCA_MY2020_Tx" SG_ 1429 PCM_AutoSarNMNodeId 1;
BA_ "U_CD542_MY2021_Tx" SG_ 1429 PCM_AutoSarNMNodeId 1;
BA_ "U_U55X_MY2022_Tx" SG_ 1429 PCM_AutoSarNMNodeId 1;
BA_ "U_CD764_MY2022_Tx" SG_ 1429 PCM_AutoSarNMNodeId 1;
BA_ "ContentDependant" SG_ 1429 PCM_AutoSarNMControl 1;
BA_ "U_P702_MY2021_Rx" SG_ 1429 PCM_AutoSarNMControl 1;
BA_ "U_T6_MCA_MY2020_Rx" SG_ 1429 PCM_AutoSarNMControl 1;
BA_ "U_CX727_MY2021_Tx" SG_ 1429 PCM_AutoSarNMControl 1;
BA_ "U_P702_MY2021_Tx" SG_ 1429 PCM_AutoSarNMControl 1;
BA_ "U_T6_MCA_MY2020_Tx" SG_ 1429 PCM_AutoSarNMControl 1;
BA_ "U_CD542_MY2021_Tx" SG_ 1429 PCM_AutoSarNMControl 1;
BA_ "U_U55X_MY2022_Tx" SG_ 1429 PCM_AutoSarNMControl 1;
BA_ "U_CD764_MY2022_Tx" SG_ 1429 PCM_AutoSarNMControl 1;
BA_ "GenSigStartValueInteger" SG_ 1100 WakeAlarm1_T_Rq 32767;
BA_ "GenSigStartValue" SG_ 1100 WakeAlarm1_T_Rq 32767;
BA_ "U_P702_MY2021_Tx" SG_ 1100 WakeAlarm1_T_Rq 1;
BA_ "U_T6_MCA_MY2020_Tx" SG_ 1100 WakeAlarm1_T_Rq 1;
BA_ "U_CD542_MY2021_Tx" SG_ 1100 WakeAlarm1_T_Rq 1;
BA_ "GenSigSendType" SG_ 1100 WakeAlarm1_B_Typ 3;
BA_ "WakeupSignal" SG_ 1100 WakeAlarm1_B_Typ 1;
BA_ "U_P702_MY2021_Tx" SG_ 1100 WakeAlarm1_B_Typ 1;
BA_ "U_T6_MCA_MY2020_Tx" SG_ 1100 WakeAlarm1_B_Typ 1;
BA_ "U_CD542_MY2021_Tx" SG_ 1100 WakeAlarm1_B_Typ 1;
BA_ "GenSigSendType" SG_ 1100 AutoTowAllw_D_StatMnu 3;
BA_ "U_P702_MY2021_Tx" SG_ 1100 AutoTowAllw_D_StatMnu 1;
BA_ "U_U55X_MY2022_Tx" SG_ 1100 AutoTowAllw_D_StatMnu 1;
BA_ "GenSigSendType" SG_ 1100 AutoTowActv_B_Stat 3;
BA_ "U_T6_MCA_MY2020_Rx" SG_ 1100 AutoTowActv_B_Stat 1;
BA_ "U_CD542_MY2021_Rx" SG_ 1100 AutoTowActv_B_Stat 1;
BA_ "U_U55X_MY2022_Rx" SG_ 1100 AutoTowActv_B_Stat 1;
BA_ "U_CD764_MY2022_Rx" SG_ 1100 AutoTowActv_B_Stat 1;
BA_ "U_P702_MY2021_Tx" SG_ 1100 AutoTowActv_B_Stat 1;
BA_ "U_U55X_MY2022_Tx" SG_ 1100 AutoTowActv_B_Stat 1;
BA_ "GenSigStartValueInteger" SG_ 1100 GrossTrainWeight_M_Est 254;
BA_ "GenSigStartValue" SG_ 1100 GrossTrainWeight_M_Est 254;
BA_ "U_P702_MY2021_Rx" SG_ 1100 GrossTrainWeight_M_Est 1;
BA_ "U_T6_MCA_MY2020_Rx" SG_ 1100 GrossTrainWeight_M_Est 1;
BA_ "U_CD542_MY2021_Rx" SG_ 1100 GrossTrainWeight_M_Est 1;
BA_ "U_U55X_MY2022_Rx" SG_ 1100 GrossTrainWeight_M_Est 1;
BA_ "U_CD764_MY2022_Rx" SG_ 1100 GrossTrainWeight_M_Est 1;
BA_ "U_P702_MY2021_Tx" SG_ 1100 GrossTrainWeight_M_Est 1;
BA_ "U_T6_MCA_MY2020_Tx" SG_ 1100 GrossTrainWeight_M_Est 1;
BA_ "U_CD542_MY2021_Tx" SG_ 1100 GrossTrainWeight_M_Est 1;
BA_ "U_U55X_MY2022_Tx" SG_ 1100 GrossTrainWeight_M_Est 1;
BA_ "U_P702_MY2021_Tx" SG_ 1100 HvacCmprLim_D_Stat 1;
BA_ "U_T6_MCA_MY2020_Tx" SG_ 1100 HvacCmprLim_D_Stat 1;
BA_ "U_CD542_MY2021_Tx" SG_ 1100 HvacCmprLim_D_Stat 1;
BA_ "U_U55X_MY2022_Tx" SG_ 1100 HvacCmprLim_D_Stat 1;
BA_ "U_CD764_MY2022_Tx" SG_ 1100 HvacCmprLim_D_Stat 1;
BA_ "GenSigStartValue" SG_ 873 PwWhlLvl_Pc_Dsply 511;
BA_ "U_CD542_MY2021_Tx" SG_ 873 PwWhlLvl_Pc_Dsply 1;
BA_ "GenSigStartValueInteger" SG_ 873 BattPwLvl2_Pc_Dsply 511;
BA_ "U_CX727_MY2021_Tx" SG_ 873 BattPwLvl2_Pc_Dsply 1;
BA_ "U_CD542_MY2021_Tx" SG_ 873 BattPwLvl2_Pc_Dsply 1;
BA_ "U_CX727_MY2021_Tx" SG_ 873 EffRelTrgtOn_B_Dsply 1;
BA_ "U_CD542_MY2021_Tx" SG_ 873 EffRelTrgtOn_B_Dsply 1;
BA_ "U_CX727_MY2021_Tx" SG_ 873 EffInstThres_Pc_Dsply 1;
BA_ "U_CD542_MY2021_Tx" SG_ 873 EffInstThres_Pc_Dsply 1;
BA_ "U_CX727_MY2021_Tx" SG_ 873 EffInstLvl_Pc_Dsply 1;
BA_ "U_CD542_MY2021_Tx" SG_ 873 EffInstLvl_Pc_Dsply 1;
BA_ "U_CX727_MY2021_Tx" SG_ 873 GpsElMdeActv_B_Dsply 1;
BA_ "U_CD542_MY2021_Tx" SG_ 873 GpsElMdeActv_B_Dsply 1;
BA_ "U_CX727_MY2021_Tx" SG_ 873 LoAirAmbPlgIn_B_Dsply 1;
BA_ "U_CD542_MY2021_Tx" SG_ 873 LoAirAmbPlgIn_B_Dsply 1;
BA_ "ECGUsedRxSignal" SG_ 871 BattElecPerf_D_Actl 1;
BA_ "U_CD542_MY2021_Rx" SG_ 871 BattElecPerf_D_Actl 1;
BA_ "U_U55X_MY2022_Rx" SG_ 871 BattElecPerf_D_Actl 1;
BA_ "U_CX727_MY2021_Tx" SG_ 871 BattElecPerf_D_Actl 1;
BA_ "U_P702_MY2021_Tx" SG_ 871 BattElecPerf_D_Actl 1;
BA_ "U_CD542_MY2021_Tx" SG_ 871 BattElecPerf_D_Actl 1;
BA_ "ECGUsedRxSignal" SG_ 871 BattChrgTrgtLPt_T_Est 1;
BA_ "U_CD542_MY2021_Rx" SG_ 871 BattChrgTrgtLPt_T_Est 1;
BA_ "U_U55X_MY2022_Rx" SG_ 871 BattChrgTrgtLPt_T_Est 1;
BA_ "U_CX727_MY2021_Tx" SG_ 871 BattChrgTrgtLPt_T_Est 1;
BA_ "U_P702_MY2021_Tx" SG_ 871 BattChrgTrgtLPt_T_Est 1;
BA_ "U_CD542_MY2021_Tx" SG_ 871 BattChrgTrgtLPt_T_Est 1;
BA_ "ECGUsedRxSignal" SG_ 871 BattChrgTrgSocPt_T_Est 1;
BA_ "U_CD542_MY2021_Rx" SG_ 871 BattChrgTrgSocPt_T_Est 1;
BA_ "U_U55X_MY2022_Rx" SG_ 871 BattChrgTrgSocPt_T_Est 1;
BA_ "U_CX727_MY2021_Tx" SG_ 871 BattChrgTrgSocPt_T_Est 1;
BA_ "U_P702_MY2021_Tx" SG_ 871 BattChrgTrgSocPt_T_Est 1;
BA_ "U_CD542_MY2021_Tx" SG_ 871 BattChrgTrgSocPt_T_Est 1;
BA_ "ECGUsedRxSignal" SG_ 871 BattChrgCmpltPt_T_Est 1;
BA_ "U_CD542_MY2021_Rx" SG_ 871 BattChrgCmpltPt_T_Est 1;
BA_ "U_U55X_MY2022_Rx" SG_ 871 BattChrgCmpltPt_T_Est 1;
BA_ "U_CX727_MY2021_Tx" SG_ 871 BattChrgCmpltPt_T_Est 1;
BA_ "U_P702_MY2021_Tx" SG_ 871 BattChrgCmpltPt_T_Est 1;
BA_ "U_CD542_MY2021_Tx" SG_ 871 BattChrgCmpltPt_T_Est 1;
BA_ "U_CX727_MY2021_Tx" SG_ 871 DrvEffLvlIncDec_D_Cmd 1;
BA_ "U_CD542_MY2021_Tx" SG_ 871 DrvEffLvlIncDec_D_Cmd 1;
BA_ "GenSigStartValueInteger" SG_ 1098 EcoCochInstTot_Pc_Dsply 255;
BA_ "GenSigStartValue" SG_ 1098 EcoCochInstTot_Pc_Dsply 255;
BA_ "U_CD764_MY2022_Tx" SG_ 1098 EcoCochInstTot_Pc_Dsply 1;
BA_ "U_CX727_MY2021_Tx" SG_ 1086 FuelPumpPwr_B_Rq 1;
BA_ "U_P702_MY2021_Tx" SG_ 1086 FuelPumpPwr_B_Rq 1;
BA_ "U_T6_MCA_MY2020_Tx" SG_ 1086 FuelPumpPwr_B_Rq 1;
BA_ "U_CD542_MY2021_Tx" SG_ 1086 FuelPumpPwr_B_Rq 1;
BA_ "U_U55X_MY2022_Tx" SG_ 1086 FuelPumpPwr_B_Rq 1;
BA_ "U_CD764_MY2022_Tx" SG_ 1086 FuelPumpPwr_B_Rq 1;
BA_ "U_CX727_MY2021_Tx" SG_ 1086 BattULoChrg_U_Cmd 1;
BA_ "U_P702_MY2021_Tx" SG_ 1086 BattULoChrg_U_Cmd 1;
BA_ "U_T6_MCA_MY2020_Tx" SG_ 1086 BattULoChrg_U_Cmd 1;
BA_ "U_CD542_MY2021_Tx" SG_ 1086 BattULoChrg_U_Cmd 1;
BA_ "U_U55X_MY2022_Tx" SG_ 1086 BattULoChrg_U_Cmd 1;
BA_ "ContentDependant" SG_ 1086 ElLoadCtl_D_Rq 1;
BA_ "U_P702_MY2021_Tx" SG_ 1086 ElLoadCtl_D_Rq 1;
BA_ "U_T6_MCA_MY2020_Tx" SG_ 1086 ElLoadCtl_D_Rq 1;
BA_ "U_CD542_MY2021_Tx" SG_ 1086 ElLoadCtl_D_Rq 1;
BA_ "U_U55X_MY2022_Tx" SG_ 1086 ElLoadCtl_D_Rq 1;
BA_ "U_CD764_MY2022_Tx" SG_ 1086 ElLoadCtl_D_Rq 1;
BA_ "ContentDependant" SG_ 1085 ULoRgenTestMde_B_Stat 1;
BA_ "U_P702_MY2021_Tx" SG_ 1085 ULoRgenTestMde_B_Stat 1;
BA_ "U_T6_MCA_MY2020_Tx" SG_ 1085 ULoRgenTestMde_B_Stat 1;
BA_ "U_CD542_MY2021_Tx" SG_ 1085 ULoRgenTestMde_B_Stat 1;
BA_ "U_U55X_MY2022_Tx" SG_ 1085 ULoRgenTestMde_B_Stat 1;
BA_ "U_CD764_MY2022_Tx" SG_ 1085 ULoRgenTestMde_B_Stat 1;
BA_ "U_CX727_MY2021_Rx" SG_ 1085 PwSrcULoOvrTe_B_Actl 1;
BA_ "U_CD542_MY2021_Rx" SG_ 1085 PwSrcULoOvrTe_B_Actl 1;
BA_ "U_P702_MY2021_Tx" SG_ 1085 PwSrcULoOvrTe_B_Actl 1;
BA_ "U_T6_MCA_MY2020_Tx" SG_ 1085 PwSrcULoOvrTe_B_Actl 1;
BA_ "U_CD542_MY2021_Tx" SG_ 1085 PwSrcULoOvrTe_B_Actl 1;
BA_ "U_U55X_MY2022_Tx" SG_ 1085 PwSrcULoOvrTe_B_Actl 1;
BA_ "U_CD764_MY2022_Tx" SG_ 1085 PwSrcULoOvrTe_B_Actl 1;
BA_ "U_CX727_MY2021_Rx" SG_ 1085 PwSrcULoOn_B_Actl 1;
BA_ "U_P702_MY2021_Rx" SG_ 1085 PwSrcULoOn_B_Actl 1;
BA_ "U_CD542_MY2021_Rx" SG_ 1085 PwSrcULoOn_B_Actl 1;
BA_ "U_P702_MY2021_Tx" SG_ 1085 PwSrcULoFalt_D_Stat 1;
BA_ "U_T6_MCA_MY2020_Tx" SG_ 1085 PwSrcULoFalt_D_Stat 1;
BA_ "U_CD542_MY2021_Tx" SG_ 1085 PwSrcULoFalt_D_Stat 1;
BA_ "U_U55X_MY2022_Tx" SG_ 1085 PwSrcULoFalt_D_Stat 1;
BA_ "U_CD764_MY2022_Tx" SG_ 1085 PwSrcULoFalt_D_Stat 1;
BA_ "U_CX727_MY2021_Rx" SG_ 1085 PwSrcULoDcnnt_B_Stat 1;
BA_ "U_CD542_MY2021_Rx" SG_ 1085 PwSrcULoDcnnt_B_Stat 1;
BA_ "U_P702_MY2021_Tx" SG_ 1085 PwSrcULoDcnnt_B_Stat 1;
BA_ "U_T6_MCA_MY2020_Tx" SG_ 1085 PwSrcULoDcnnt_B_Stat 1;
BA_ "U_CD542_MY2021_Tx" SG_ 1085 PwSrcULoDcnnt_B_Stat 1;
BA_ "U_U55X_MY2022_Tx" SG_ 1085 PwSrcULoDcnnt_B_Stat 1;
BA_ "U_CD764_MY2022_Tx" SG_ 1085 PwSrcULoDcnnt_B_Stat 1;
BA_ "U_P702_MY2021_Tx" SG_ 1085 PwSrcULo_Pc_Mx 1;
BA_ "U_T6_MCA_MY2020_Tx" SG_ 1085 PwSrcULo_Pc_Mx 1;
BA_ "U_CD542_MY2021_Tx" SG_ 1085 PwSrcULo_Pc_Mx 1;
BA_ "U_U55X_MY2022_Tx" SG_ 1085 PwSrcULo_Pc_Mx 1;
BA_ "U_CD764_MY2022_Tx" SG_ 1085 PwSrcULo_Pc_Mx 1;
BA_ "ContentDependant" SG_ 1085 BattTracCool_D_RqDcdc 1;
BA_ "ContentDependant" SG_ 1085 PwSrcULoComm_B_Falt 1;
BA_ "U_P702_MY2021_Tx" SG_ 1085 PwSrcULoComm_B_Falt 1;
BA_ "U_T6_MCA_MY2020_Tx" SG_ 1085 PwSrcULoComm_B_Falt 1;
BA_ "U_CD542_MY2021_Tx" SG_ 1085 PwSrcULoComm_B_Falt 1;
BA_ "U_U55X_MY2022_Tx" SG_ 1085 PwSrcULoComm_B_Falt 1;
BA_ "U_CD764_MY2022_Tx" SG_ 1085 PwSrcULoComm_B_Falt 1;
BA_ "ContentDependant" SG_ 1085 DcdcULo_U_Actl 1;
BA_ "U_CX727_MY2021_Rx" SG_ 1085 DcdcULo_U_Actl 1;
BA_ "U_P702_MY2021_Rx" SG_ 1085 DcdcULo_U_Actl 1;
BA_ "U_CD542_MY2021_Rx" SG_ 1085 DcdcULo_U_Actl 1;
BA_ "ContentDependant" SG_ 1085 DcdcUHi_I_Actl 1;
BA_ "U_CX727_MY2021_Rx" SG_ 1085 DcdcUHi_I_Actl 1;
BA_ "U_P702_MY2021_Rx" SG_ 1085 DcdcUHi_I_Actl 1;
BA_ "U_CD542_MY2021_Rx" SG_ 1085 DcdcUHi_I_Actl 1;
BA_ "U_CX727_MY2021_Rx" SG_ 1085 PwSrcULo_I_Mx 1;
BA_ "U_P702_MY2021_Rx" SG_ 1085 PwSrcULo_I_Mx 1;
BA_ "U_CD542_MY2021_Rx" SG_ 1085 PwSrcULo_I_Mx 1;
BA_ "U_P702_MY2021_Tx" SG_ 1085 PwSrcULo_I_Mx 1;
BA_ "U_T6_MCA_MY2020_Tx" SG_ 1085 PwSrcULo_I_Mx 1;
BA_ "U_CD542_MY2021_Tx" SG_ 1085 PwSrcULo_I_Mx 1;
BA_ "U_U55X_MY2022_Tx" SG_ 1085 PwSrcULo_I_Mx 1;
BA_ "U_CD764_MY2022_Tx" SG_ 1085 PwSrcULo_I_Mx 1;
BA_ "U_CX727_MY2021_Rx" SG_ 1085 PwSrcULo_I_Actl 1;
BA_ "U_P702_MY2021_Rx" SG_ 1085 PwSrcULo_I_Actl 1;
BA_ "U_CD542_MY2021_Rx" SG_ 1085 PwSrcULo_I_Actl 1;
BA_ "U_P702_MY2021_Tx" SG_ 1085 PwSrcULo_I_Actl 1;
BA_ "U_T6_MCA_MY2020_Tx" SG_ 1085 PwSrcULo_I_Actl 1;
BA_ "U_CD542_MY2021_Tx" SG_ 1085 PwSrcULo_I_Actl 1;
BA_ "U_U55X_MY2022_Tx" SG_ 1085 PwSrcULo_I_Actl 1;
BA_ "U_CD764_MY2022_Tx" SG_ 1085 PwSrcULo_I_Actl 1;
BA_ "ContentDependant" SG_ 1085 DcdcUHi_U_Actl 1;
BA_ "U_CX727_MY2021_Rx" SG_ 1085 DcdcUHi_U_Actl 1;
BA_ "U_P702_MY2021_Rx" SG_ 1085 DcdcUHi_U_Actl 1;
BA_ "U_CD542_MY2021_Rx" SG_ 1085 DcdcUHi_U_Actl 1;
BA_ "U_CX727_MY2021_Tx" SG_ 1071 EngAout_N_Dsply 1;
BA_ "U_P702_MY2021_Tx" SG_ 1071 EngAout_N_Dsply 1;
BA_ "U_T6_MCA_MY2020_Tx" SG_ 1071 EngAout_N_Dsply 1;
BA_ "U_CD542_MY2021_Tx" SG_ 1071 EngAout_N_Dsply 1;
BA_ "U_U55X_MY2022_Tx" SG_ 1071 EngAout_N_Dsply 1;
BA_ "U_CD764_MY2022_Tx" SG_ 1071 EngAout_N_Dsply 1;
BA_ "ContentDependant" SG_ 1071 CluPdl_PcRate_Actl 1;
BA_ "U_CX727_MY2021_Rx" SG_ 1071 CluPdl_PcRate_Actl 1;
BA_ "U_CD542_MY2021_Rx" SG_ 1071 CluPdl_PcRate_Actl 1;
BA_ "U_P702_MY2021_Tx" SG_ 1071 CluPdl_PcRate_Actl 1;
BA_ "U_T6_MCA_MY2020_Tx" SG_ 1071 CluPdl_PcRate_Actl 1;
BA_ "GenSigStartValueInteger" SG_ 1071 CluPdlPosPcMeas_D_Qf 1;
BA_ "ContentDependant" SG_ 1071 CluPdlPosPcMeas_D_Qf 1;
BA_ "MetaData" SG_ 1071 CluPdlPosPcMeas_D_Qf 1;
BA_ "GenSigStartValue" SG_ 1071 CluPdlPosPcMeas_D_Qf 1;
BA_ "U_CX727_MY2021_Rx" SG_ 1071 CluPdlPosPcMeas_D_Qf 1;
BA_ "U_P702_MY2021_Rx" SG_ 1071 CluPdlPosPcMeas_D_Qf 1;
BA_ "U_T6_MCA_MY2020_Rx" SG_ 1071 CluPdlPosPcMeas_D_Qf 1;
BA_ "U_CD542_MY2021_Rx" SG_ 1071 CluPdlPosPcMeas_D_Qf 1;
BA_ "U_U55X_MY2022_Rx" SG_ 1071 CluPdlPosPcMeas_D_Qf 1;
BA_ "U_P702_MY2021_Tx" SG_ 1071 CluPdlPosPcMeas_D_Qf 1;
BA_ "U_T6_MCA_MY2020_Tx" SG_ 1071 CluPdlPosPcMeas_D_Qf 1;
BA_ "ContentDependant" SG_ 1071 CluPdlPos_Pc_Meas 1;
BA_ "U_CX727_MY2021_Rx" SG_ 1071 CluPdlPos_Pc_Meas 1;
BA_ "U_P702_MY2021_Rx" SG_ 1071 CluPdlPos_Pc_Meas 1;
BA_ "U_T6_MCA_MY2020_Rx" SG_ 1071 CluPdlPos_Pc_Meas 1;
BA_ "U_CD542_MY2021_Rx" SG_ 1071 CluPdlPos_Pc_Meas 1;
BA_ "U_U55X_MY2022_Rx" SG_ 1071 CluPdlPos_Pc_Meas 1;
BA_ "U_P702_MY2021_Tx" SG_ 1071 CluPdlPos_Pc_Meas 1;
BA_ "U_T6_MCA_MY2020_Tx" SG_ 1071 CluPdlPos_Pc_Meas 1;
BA_ "ContentDependant" SG_ 1071 EngAoutIdl_N_Ntrl 1;
BA_ "U_CX727_MY2021_Rx" SG_ 1071 EngAoutIdl_N_Ntrl 1;
BA_ "U_P702_MY2021_Rx" SG_ 1071 EngAoutIdl_N_Ntrl 1;
BA_ "U_T6_MCA_MY2020_Rx" SG_ 1071 EngAoutIdl_N_Ntrl 1;
BA_ "U_CD542_MY2021_Rx" SG_ 1071 EngAoutIdl_N_Ntrl 1;
BA_ "U_U55X_MY2022_Rx" SG_ 1071 EngAoutIdl_N_Ntrl 1;
BA_ "U_CD764_MY2022_Rx" SG_ 1071 EngAoutIdl_N_Ntrl 1;
BA_ "U_CX727_MY2021_Tx" SG_ 1071 EngAoutIdl_N_Ntrl 1;
BA_ "U_P702_MY2021_Tx" SG_ 1071 EngAoutIdl_N_Ntrl 1;
BA_ "U_T6_MCA_MY2020_Tx" SG_ 1071 EngAoutIdl_N_Ntrl 1;
BA_ "U_CD542_MY2021_Tx" SG_ 1071 EngAoutIdl_N_Ntrl 1;
BA_ "U_U55X_MY2022_Tx" SG_ 1071 EngAoutIdl_N_Ntrl 1;
BA_ "U_CD764_MY2022_Tx" SG_ 1071 EngAoutIdl_N_Ntrl 1;
BA_ "U_P702_MY2021_Tx" SG_ 1069 SlMde_D_Stat 1;
BA_ "U_T6_MCA_MY2020_Tx" SG_ 1069 SlMde_D_Stat 1;
BA_ "U_CD542_MY2021_Tx" SG_ 1069 SlMde_D_Stat 1;
BA_ "U_CD764_MY2022_Tx" SG_ 1069 SlMde_D_Stat 1;
BA_ "U_P702_MY2021_Tx" SG_ 1069 SlMde_D_RqDsply 1;
BA_ "U_T6_MCA_MY2020_Tx" SG_ 1069 SlMde_D_RqDsply 1;
BA_ "U_CD542_MY2021_Tx" SG_ 1069 SlMde_D_RqDsply 1;
BA_ "U_CD764_MY2022_Tx" SG_ 1069 SlMde_D_RqDsply 1;
BA_ "U_P702_MY2021_Tx" SG_ 1069 IsaOffst_D_Stat 1;
BA_ "U_T6_MCA_MY2020_Tx" SG_ 1069 IsaOffst_D_Stat 1;
BA_ "U_CD542_MY2021_Tx" SG_ 1069 IsaOffst_D_Stat 1;
BA_ "U_CD764_MY2022_Tx" SG_ 1069 IsaOffst_D_Stat 1;
BA_ "WakeupSignal" SG_ 1069 ReFuelSysStat_D_Dsply 1;
BA_ "U_CX727_MY2021_Tx" SG_ 1069 ReFuelSysStat_D_Dsply 1;
BA_ "U_CD542_MY2021_Tx" SG_ 1069 ReFuelSysStat_D_Dsply 1;
BA_ "U_CX727_MY2021_Rx" SG_ 1069 ULoSrcOnPlg_B_Cmd 1;
BA_ "U_CD542_MY2021_Rx" SG_ 1069 ULoSrcOnPlg_B_Cmd 1;
BA_ "U_CX727_MY2021_Tx" SG_ 1069 ULoSrcOnPlg_B_Cmd 1;
BA_ "U_CD542_MY2021_Tx" SG_ 1069 ULoSrcOnPlg_B_Cmd 1;
BA_ "U_CX727_MY2021_Rx" SG_ 1069 EngOilMaint_B_Stat 1;
BA_ "U_CD542_MY2021_Rx" SG_ 1069 EngOilMaint_B_Stat 1;
BA_ "U_CX727_MY2021_Tx" SG_ 1069 EngOilMaint_B_Stat 1;
BA_ "U_CD542_MY2021_Tx" SG_ 1069 EngOilMaint_B_Stat 1;
BA_ "U_CX727_MY2021_Tx" SG_ 1069 GrllShtrPos_D_Cmd 1;
BA_ "U_P702_MY2021_Tx" SG_ 1069 GrllShtrPos_D_Cmd 1;
BA_ "U_T6_MCA_MY2020_Tx" SG_ 1069 GrllShtrPos_D_Cmd 1;
BA_ "U_CD542_MY2021_Tx" SG_ 1069 GrllShtrPos_D_Cmd 1;
BA_ "U_U55X_MY2022_Tx" SG_ 1069 GrllShtrPos_D_Cmd 1;
BA_ "U_CD764_MY2022_Tx" SG_ 1069 GrllShtrPos_D_Cmd 1;
BA_ "U_CX727_MY2021_Tx" SG_ 1069 GrllShtrPos_B_Falt 1;
BA_ "U_P702_MY2021_Tx" SG_ 1069 GrllShtrPos_B_Falt 1;
BA_ "U_T6_MCA_MY2020_Tx" SG_ 1069 GrllShtrPos_B_Falt 1;
BA_ "U_CD542_MY2021_Tx" SG_ 1069 GrllShtrPos_B_Falt 1;
BA_ "U_U55X_MY2022_Tx" SG_ 1069 GrllShtrPos_B_Falt 1;
BA_ "U_CD764_MY2022_Tx" SG_ 1069 GrllShtrPos_B_Falt 1;
BA_ "ContentDependant" SG_ 1069 ObdWarmUp_B_Complt 1;
BA_ "U_CX727_MY2021_Rx" SG_ 1069 ObdWarmUp_B_Complt 1;
BA_ "U_P702_MY2021_Rx" SG_ 1069 ObdWarmUp_B_Complt 1;
BA_ "U_CD542_MY2021_Rx" SG_ 1069 ObdWarmUp_B_Complt 1;
BA_ "U_CX727_MY2021_Tx" SG_ 1069 ObdWarmUp_B_Complt 1;
BA_ "U_P702_MY2021_Tx" SG_ 1069 ObdWarmUp_B_Complt 1;
BA_ "U_CD542_MY2021_Tx" SG_ 1069 ObdWarmUp_B_Complt 1;
BA_ "ContentDependant" SG_ 1069 EngMsgTxt_D_Rq 1;
BA_ "U_CX727_MY2021_Tx" SG_ 1069 EngMsgTxt_D_Rq 1;
BA_ "U_P702_MY2021_Tx" SG_ 1069 EngMsgTxt_D_Rq 1;
BA_ "U_T6_MCA_MY2020_Tx" SG_ 1069 EngMsgTxt_D_Rq 1;
BA_ "U_CD542_MY2021_Tx" SG_ 1069 EngMsgTxt_D_Rq 1;
BA_ "U_U55X_MY2022_Tx" SG_ 1069 EngMsgTxt_D_Rq 1;
BA_ "U_CD764_MY2022_Tx" SG_ 1069 EngMsgTxt_D_Rq 1;
BA_ "ContentDependant" SG_ 1069 EngClnt_Te_ActlDiag 1;
BA_ "U_CX727_MY2021_Rx" SG_ 1069 EngClnt_Te_ActlDiag 1;
BA_ "U_P702_MY2021_Rx" SG_ 1069 EngClnt_Te_ActlDiag 1;
BA_ "U_T6_MCA_MY2020_Rx" SG_ 1069 EngClnt_Te_ActlDiag 1;
BA_ "U_CD542_MY2021_Rx" SG_ 1069 EngClnt_Te_ActlDiag 1;
BA_ "U_CX727_MY2021_Tx" SG_ 1069 EngClnt_Te_ActlDiag 1;
BA_ "U_P702_MY2021_Tx" SG_ 1069 EngClnt_Te_ActlDiag 1;
BA_ "U_T6_MCA_MY2020_Tx" SG_ 1069 EngClnt_Te_ActlDiag 1;
BA_ "U_CD542_MY2021_Tx" SG_ 1069 EngClnt_Te_ActlDiag 1;
BA_ "ContentDependant" SG_ 1069 EngLoad_Pc_CalcDiag 1;
BA_ "U_CX727_MY2021_Rx" SG_ 1069 EngLoad_Pc_CalcDiag 1;
BA_ "U_P702_MY2021_Rx" SG_ 1069 EngLoad_Pc_CalcDiag 1;
BA_ "U_T6_MCA_MY2020_Rx" SG_ 1069 EngLoad_Pc_CalcDiag 1;
BA_ "U_CD542_MY2021_Rx" SG_ 1069 EngLoad_Pc_CalcDiag 1;
BA_ "U_CX727_MY2021_Tx" SG_ 1069 EngLoad_Pc_CalcDiag 1;
BA_ "U_P702_MY2021_Tx" SG_ 1069 EngLoad_Pc_CalcDiag 1;
BA_ "U_T6_MCA_MY2020_Tx" SG_ 1069 EngLoad_Pc_CalcDiag 1;
BA_ "U_CD542_MY2021_Tx" SG_ 1069 EngLoad_Pc_CalcDiag 1;
BA_ "U_P702_MY2021_Rx" SG_ 1069 EngAirIn_Te_Actl 1;
BA_ "U_T6_MCA_MY2020_Rx" SG_ 1069 EngAirIn_Te_Actl 1;
BA_ "U_CX727_MY2021_Tx" SG_ 1069 EngAirIn_Te_Actl 1;
BA_ "U_P702_MY2021_Tx" SG_ 1069 EngAirIn_Te_Actl 1;
BA_ "U_T6_MCA_MY2020_Tx" SG_ 1069 EngAirIn_Te_Actl 1;
BA_ "U_CD542_MY2021_Tx" SG_ 1069 EngAirIn_Te_Actl 1;
BA_ "U_U55X_MY2022_Tx" SG_ 1069 EngAirIn_Te_Actl 1;
BA_ "U_CD764_MY2022_Tx" SG_ 1069 EngAirIn_Te_Actl 1;
BA_ "ContentDependant" SG_ 1069 ApedPos_Pc_ActlDiag 1;
BA_ "U_CX727_MY2021_Rx" SG_ 1069 ApedPos_Pc_ActlDiag 1;
BA_ "U_P702_MY2021_Rx" SG_ 1069 ApedPos_Pc_ActlDiag 1;
BA_ "U_T6_MCA_MY2020_Rx" SG_ 1069 ApedPos_Pc_ActlDiag 1;
BA_ "U_CD542_MY2021_Rx" SG_ 1069 ApedPos_Pc_ActlDiag 1;
BA_ "U_CX727_MY2021_Tx" SG_ 1069 ApedPos_Pc_ActlDiag 1;
BA_ "U_P702_MY2021_Tx" SG_ 1069 ApedPos_Pc_ActlDiag 1;
BA_ "U_T6_MCA_MY2020_Tx" SG_ 1069 ApedPos_Pc_ActlDiag 1;
BA_ "U_CD542_MY2021_Tx" SG_ 1069 ApedPos_Pc_ActlDiag 1;
BA_ "U_CX727_MY2021_Tx" SG_ 1060 BpedDrvMsgTxt_B_Dsply 1;
BA_ "U_P702_MY2021_Tx" SG_ 1060 BpedDrvMsgTxt_B_Dsply 1;
BA_ "U_T6_MCA_MY2020_Tx" SG_ 1060 BpedDrvMsgTxt_B_Dsply 1;
BA_ "U_CD542_MY2021_Tx" SG_ 1060 BpedDrvMsgTxt_B_Dsply 1;
BA_ "U_U55X_MY2022_Tx" SG_ 1060 BpedDrvMsgTxt_B_Dsply 1;
BA_ "U_CD764_MY2022_Tx" SG_ 1060 BpedDrvMsgTxt_B_Dsply 1;
BA_ "GenSigStartValueInteger" SG_ 1060 FuelLvl_Pc_DsplyEng 48;
BA_ "U_P702_MY2021_Tx" SG_ 1060 FuelLvl_Pc_DsplyEng 1;
BA_ "U_T6_MCA_MY2020_Tx" SG_ 1060 FuelLvl_Pc_DsplyEng 1;
BA_ "U_CD542_MY2021_Tx" SG_ 1060 FuelLvl_Pc_DsplyEng 1;
BA_ "U_U55X_MY2022_Tx" SG_ 1060 FuelLvl_Pc_DsplyEng 1;
BA_ "U_CD764_MY2022_Tx" SG_ 1060 FuelLvl_Pc_DsplyEng 1;
BA_ "U_P702_MY2021_Tx" SG_ 1060 FuelLvlWarn_D_ActlEng 1;
BA_ "U_T6_MCA_MY2020_Tx" SG_ 1060 FuelLvlWarn_D_ActlEng 1;
BA_ "U_CD542_MY2021_Tx" SG_ 1060 FuelLvlWarn_D_ActlEng 1;
BA_ "U_U55X_MY2022_Tx" SG_ 1060 FuelLvlWarn_D_ActlEng 1;
BA_ "U_CD764_MY2022_Tx" SG_ 1060 FuelLvlWarn_D_ActlEng 1;
BA_ "U_P702_MY2021_Tx" SG_ 1060 FuelRange_L_DsplyEng 1;
BA_ "U_T6_MCA_MY2020_Tx" SG_ 1060 FuelRange_L_DsplyEng 1;
BA_ "U_CD542_MY2021_Tx" SG_ 1060 FuelRange_L_DsplyEng 1;
BA_ "U_U55X_MY2022_Tx" SG_ 1060 FuelRange_L_DsplyEng 1;
BA_ "U_CD764_MY2022_Tx" SG_ 1060 FuelRange_L_DsplyEng 1;
BA_ "U_P702_MY2021_Rx" SG_ 1060 SelDrvMdePt_D_Stat 1;
BA_ "U_T6_MCA_MY2020_Rx" SG_ 1060 SelDrvMdePt_D_Stat 1;
BA_ "U_CD542_MY2021_Rx" SG_ 1060 SelDrvMdePt_D_Stat 1;
BA_ "U_U55X_MY2022_Rx" SG_ 1060 SelDrvMdePt_D_Stat 1;
BA_ "U_CD764_MY2022_Rx" SG_ 1060 SelDrvMdePt_D_Stat 1;
BA_ "U_CX727_MY2021_Tx" SG_ 1060 SelDrvMdePt_D_Stat 1;
BA_ "U_P702_MY2021_Tx" SG_ 1060 SelDrvMdePt_D_Stat 1;
BA_ "U_T6_MCA_MY2020_Tx" SG_ 1060 SelDrvMdePt_D_Stat 1;
BA_ "U_CD542_MY2021_Tx" SG_ 1060 SelDrvMdePt_D_Stat 1;
BA_ "U_U55X_MY2022_Tx" SG_ 1060 SelDrvMdePt_D_Stat 1;
BA_ "U_CD764_MY2022_Tx" SG_ 1060 SelDrvMdePt_D_Stat 1;
BA_ "U_CX727_MY2021_Tx" SG_ 1057 EngIdlShutDwnTxt_D_Rq 1;
BA_ "U_P702_MY2021_Tx" SG_ 1057 EngIdlShutDwnTxt_D_Rq 1;
BA_ "U_T6_MCA_MY2020_Tx" SG_ 1057 EngIdlShutDwnTxt_D_Rq 1;
BA_ "U_CD542_MY2021_Tx" SG_ 1057 EngIdlShutDwnTxt_D_Rq 1;
BA_ "U_U55X_MY2022_Tx" SG_ 1057 EngIdlShutDwnTxt_D_Rq 1;
BA_ "U_CD764_MY2022_Tx" SG_ 1057 EngIdlShutDwnTxt_D_Rq 1;
BA_ "ContentDependant" SG_ 1057 EngIdlShutDown_D_Stat 1;
BA_ "U_T6_MCA_MY2020_Rx" SG_ 1057 EngIdlShutDown_D_Stat 1;
BA_ "ECGUsedRxSignal" SG_ 1057 EngIdlShutDown_D_Stat 1;
BA_ "U_CD542_MY2021_Rx" SG_ 1057 EngIdlShutDown_D_Stat 1;
BA_ "U_U55X_MY2022_Rx" SG_ 1057 EngIdlShutDown_D_Stat 1;
BA_ "U_CD764_MY2022_Rx" SG_ 1057 EngIdlShutDown_D_Stat 1;
BA_ "U_CX727_MY2021_Tx" SG_ 1057 EngIdlShutDown_D_Stat 1;
BA_ "U_P702_MY2021_Tx" SG_ 1057 EngIdlShutDown_D_Stat 1;
BA_ "U_T6_MCA_MY2020_Tx" SG_ 1057 EngIdlShutDown_D_Stat 1;
BA_ "U_CD542_MY2021_Tx" SG_ 1057 EngIdlShutDown_D_Stat 1;
BA_ "U_U55X_MY2022_Tx" SG_ 1057 EngIdlShutDown_D_Stat 1;
BA_ "U_CD764_MY2022_Tx" SG_ 1057 EngIdlShutDown_D_Stat 1;
BA_ "GenSigStartValueInteger" SG_ 1057 FUEL_ALCOHOL_PERCNT 255;
BA_ "ContentDependant" SG_ 1057 FUEL_ALCOHOL_PERCNT 1;
BA_ "GenSigStartValue" SG_ 1057 FUEL_ALCOHOL_PERCNT 255;
BA_ "U_CX727_MY2021_Tx" SG_ 1057 FUEL_ALCOHOL_PERCNT 1;
BA_ "U_P702_MY2021_Tx" SG_ 1057 FUEL_ALCOHOL_PERCNT 1;
BA_ "U_T6_MCA_MY2020_Tx" SG_ 1057 FUEL_ALCOHOL_PERCNT 1;
BA_ "U_CD542_MY2021_Tx" SG_ 1057 FUEL_ALCOHOL_PERCNT 1;
BA_ "U_U55X_MY2022_Tx" SG_ 1057 FUEL_ALCOHOL_PERCNT 1;
BA_ "U_CX727_MY2021_Tx" SG_ 1057 ECMMILRequest 1;
BA_ "U_P702_MY2021_Tx" SG_ 1057 ECMMILRequest 1;
BA_ "U_T6_MCA_MY2020_Tx" SG_ 1057 ECMMILRequest 1;
BA_ "U_CD542_MY2021_Tx" SG_ 1057 ECMMILRequest 1;
BA_ "U_U55X_MY2022_Tx" SG_ 1057 ECMMILRequest 1;
BA_ "U_CD764_MY2022_Tx" SG_ 1057 ECMMILRequest 1;
BA_ "U_CX727_MY2021_Rx" SG_ 1057 AirCondFluidHi_P_Actl 1;
BA_ "U_P702_MY2021_Rx" SG_ 1057 AirCondFluidHi_P_Actl 1;
BA_ "U_CD542_MY2021_Rx" SG_ 1057 AirCondFluidHi_P_Actl 1;
BA_ "U_CX727_MY2021_Tx" SG_ 1057 AirCondFluidHi_P_Actl 1;
BA_ "U_P702_MY2021_Tx" SG_ 1057 AirCondFluidHi_P_Actl 1;
BA_ "U_T6_MCA_MY2020_Tx" SG_ 1057 AirCondFluidHi_P_Actl 1;
BA_ "U_CD542_MY2021_Tx" SG_ 1057 AirCondFluidHi_P_Actl 1;
BA_ "U_U55X_MY2022_Tx" SG_ 1057 AirCondFluidHi_P_Actl 1;
BA_ "U_CD764_MY2022_Tx" SG_ 1057 AirCondFluidHi_P_Actl 1;
BA_ "U_CX727_MY2021_Tx" SG_ 1057 OilPressureWarning 1;
BA_ "U_P702_MY2021_Tx" SG_ 1057 OilPressureWarning 1;
BA_ "U_T6_MCA_MY2020_Tx" SG_ 1057 OilPressureWarning 1;
BA_ "U_CD542_MY2021_Tx" SG_ 1057 OilPressureWarning 1;
BA_ "U_U55X_MY2022_Tx" SG_ 1057 OilPressureWarning 1;
BA_ "U_CD764_MY2022_Tx" SG_ 1057 OilPressureWarning 1;
BA_ "ContentDependant" SG_ 1057 VehVLimActv_B_Actl 1;
BA_ "U_CX727_MY2021_Rx" SG_ 1057 VehVLimActv_B_Actl 1;
BA_ "U_P702_MY2021_Rx" SG_ 1057 VehVLimActv_B_Actl 1;
BA_ "U_T6_MCA_MY2020_Rx" SG_ 1057 VehVLimActv_B_Actl 1;
BA_ "U_CD542_MY2021_Rx" SG_ 1057 VehVLimActv_B_Actl 1;
BA_ "U_CX727_MY2021_Tx" SG_ 1057 VehVLimActv_B_Actl 1;
BA_ "U_P702_MY2021_Tx" SG_ 1057 VehVLimActv_B_Actl 1;
BA_ "U_T6_MCA_MY2020_Tx" SG_ 1057 VehVLimActv_B_Actl 1;
BA_ "U_CD542_MY2021_Tx" SG_ 1057 VehVLimActv_B_Actl 1;
BA_ "U_CX727_MY2021_Tx" SG_ 1057 CoolantFanStepAct 1;
BA_ "U_P702_MY2021_Tx" SG_ 1057 CoolantFanStepAct 1;
BA_ "U_T6_MCA_MY2020_Tx" SG_ 1057 CoolantFanStepAct 1;
BA_ "U_CD542_MY2021_Tx" SG_ 1057 CoolantFanStepAct 1;
BA_ "U_U55X_MY2022_Tx" SG_ 1057 CoolantFanStepAct 1;
BA_ "U_CD764_MY2022_Tx" SG_ 1057 CoolantFanStepAct 1;
BA_ "U_T6_MCA_MY2020_Rx" SG_ 1055 EcoCochInstNeg_B_Dsply 1;
BA_ "ECGUsedRxSignal" SG_ 1055 EcoCochInstNeg_B_Dsply 1;
BA_ "U_CD542_MY2021_Rx" SG_ 1055 EcoCochInstNeg_B_Dsply 1;
BA_ "U_U55X_MY2022_Rx" SG_ 1055 EcoCochInstNeg_B_Dsply 1;
BA_ "U_CD764_MY2022_Rx" SG_ 1055 EcoCochInstNeg_B_Dsply 1;
BA_ "U_CX727_MY2021_Tx" SG_ 1055 EcoCochInstNeg_B_Dsply 1;
BA_ "U_P702_MY2021_Tx" SG_ 1055 EcoCochInstNeg_B_Dsply 1;
BA_ "U_T6_MCA_MY2020_Tx" SG_ 1055 EcoCochInstNeg_B_Dsply 1;
BA_ "U_CD542_MY2021_Tx" SG_ 1055 EcoCochInstNeg_B_Dsply 1;
BA_ "U_U55X_MY2022_Tx" SG_ 1055 EcoCochInstNeg_B_Dsply 1;
BA_ "U_CD764_MY2022_Tx" SG_ 1055 EcoCochInstNeg_B_Dsply 1;
BA_ "GenSigStartValueInteger" SG_ 1055 EcoCochShif_Pc_Dsply 255;
BA_ "GenSigStartValue" SG_ 1055 EcoCochShif_Pc_Dsply 255;
BA_ "U_T6_MCA_MY2020_Rx" SG_ 1055 EcoCochShif_Pc_Dsply 1;
BA_ "ECGUsedRxSignal" SG_ 1055 EcoCochShif_Pc_Dsply 1;
BA_ "U_CD542_MY2021_Rx" SG_ 1055 EcoCochShif_Pc_Dsply 1;
BA_ "U_U55X_MY2022_Rx" SG_ 1055 EcoCochShif_Pc_Dsply 1;
BA_ "U_CD764_MY2022_Rx" SG_ 1055 EcoCochShif_Pc_Dsply 1;
BA_ "U_CX727_MY2021_Tx" SG_ 1055 EcoCochShif_Pc_Dsply 1;
BA_ "U_P702_MY2021_Tx" SG_ 1055 EcoCochShif_Pc_Dsply 1;
BA_ "U_T6_MCA_MY2020_Tx" SG_ 1055 EcoCochShif_Pc_Dsply 1;
BA_ "U_CD542_MY2021_Tx" SG_ 1055 EcoCochShif_Pc_Dsply 1;
BA_ "U_U55X_MY2022_Tx" SG_ 1055 EcoCochShif_Pc_Dsply 1;
BA_ "U_CD764_MY2022_Tx" SG_ 1055 EcoCochShif_Pc_Dsply 1;
BA_ "GenSigStartValueInteger" SG_ 1055 EcoCochInst_Pc_Dsply 1000;
BA_ "GenSigStartValue" SG_ 1055 EcoCochInst_Pc_Dsply 100;
BA_ "U_T6_MCA_MY2020_Rx" SG_ 1055 EcoCochInst_Pc_Dsply 1;
BA_ "ECGUsedRxSignal" SG_ 1055 EcoCochInst_Pc_Dsply 1;
BA_ "U_CD542_MY2021_Rx" SG_ 1055 EcoCochInst_Pc_Dsply 1;
BA_ "U_U55X_MY2022_Rx" SG_ 1055 EcoCochInst_Pc_Dsply 1;
BA_ "U_CD764_MY2022_Rx" SG_ 1055 EcoCochInst_Pc_Dsply 1;
BA_ "U_CX727_MY2021_Tx" SG_ 1055 EcoCochInst_Pc_Dsply 1;
BA_ "U_P702_MY2021_Tx" SG_ 1055 EcoCochInst_Pc_Dsply 1;
BA_ "U_T6_MCA_MY2020_Tx" SG_ 1055 EcoCochInst_Pc_Dsply 1;
BA_ "U_CD542_MY2021_Tx" SG_ 1055 EcoCochInst_Pc_Dsply 1;
BA_ "U_U55X_MY2022_Tx" SG_ 1055 EcoCochInst_Pc_Dsply 1;
BA_ "U_CD764_MY2022_Tx" SG_ 1055 EcoCochInst_Pc_Dsply 1;
BA_ "GenSigStartValueInteger" SG_ 1055 EcoCochIdlFuel_Pc_Dsply 255;
BA_ "GenSigStartValue" SG_ 1055 EcoCochIdlFuel_Pc_Dsply 255;
BA_ "U_T6_MCA_MY2020_Rx" SG_ 1055 EcoCochIdlFuel_Pc_Dsply 1;
BA_ "ECGUsedRxSignal" SG_ 1055 EcoCochIdlFuel_Pc_Dsply 1;
BA_ "U_CD542_MY2021_Rx" SG_ 1055 EcoCochIdlFuel_Pc_Dsply 1;
BA_ "U_U55X_MY2022_Rx" SG_ 1055 EcoCochIdlFuel_Pc_Dsply 1;
BA_ "U_CD764_MY2022_Rx" SG_ 1055 EcoCochIdlFuel_Pc_Dsply 1;
BA_ "U_CX727_MY2021_Tx" SG_ 1055 EcoCochIdlFuel_Pc_Dsply 1;
BA_ "U_P702_MY2021_Tx" SG_ 1055 EcoCochIdlFuel_Pc_Dsply 1;
BA_ "U_T6_MCA_MY2020_Tx" SG_ 1055 EcoCochIdlFuel_Pc_Dsply 1;
BA_ "U_CD542_MY2021_Tx" SG_ 1055 EcoCochIdlFuel_Pc_Dsply 1;
BA_ "U_U55X_MY2022_Tx" SG_ 1055 EcoCochIdlFuel_Pc_Dsply 1;
BA_ "U_CD764_MY2022_Tx" SG_ 1055 EcoCochIdlFuel_Pc_Dsply 1;
BA_ "GenSigStartValueInteger" SG_ 1055 EcoCochDecel_Pc_Dsply 255;
BA_ "GenSigStartValue" SG_ 1055 EcoCochDecel_Pc_Dsply 255;
BA_ "U_T6_MCA_MY2020_Rx" SG_ 1055 EcoCochDecel_Pc_Dsply 1;
BA_ "ECGUsedRxSignal" SG_ 1055 EcoCochDecel_Pc_Dsply 1;
BA_ "U_U55X_MY2022_Rx" SG_ 1055 EcoCochDecel_Pc_Dsply 1;
BA_ "U_CD764_MY2022_Rx" SG_ 1055 EcoCochDecel_Pc_Dsply 1;
BA_ "U_CX727_MY2021_Tx" SG_ 1055 EcoCochDecel_Pc_Dsply 1;
BA_ "U_P702_MY2021_Tx" SG_ 1055 EcoCochDecel_Pc_Dsply 1;
BA_ "U_T6_MCA_MY2020_Tx" SG_ 1055 EcoCochDecel_Pc_Dsply 1;
BA_ "U_CD542_MY2021_Tx" SG_ 1055 EcoCochDecel_Pc_Dsply 1;
BA_ "U_U55X_MY2022_Tx" SG_ 1055 EcoCochDecel_Pc_Dsply 1;
BA_ "U_CD764_MY2022_Tx" SG_ 1055 EcoCochDecel_Pc_Dsply 1;
BA_ "GenSigStartValueInteger" SG_ 1055 EcoCochCrus_Pc_Dsply 255;
BA_ "GenSigStartValue" SG_ 1055 EcoCochCrus_Pc_Dsply 255;
BA_ "U_T6_MCA_MY2020_Rx" SG_ 1055 EcoCochCrus_Pc_Dsply 1;
BA_ "ECGUsedRxSignal" SG_ 1055 EcoCochCrus_Pc_Dsply 1;
BA_ "U_U55X_MY2022_Rx" SG_ 1055 EcoCochCrus_Pc_Dsply 1;
BA_ "U_CD764_MY2022_Rx" SG_ 1055 EcoCochCrus_Pc_Dsply 1;
BA_ "U_CX727_MY2021_Tx" SG_ 1055 EcoCochCrus_Pc_Dsply 1;
BA_ "U_P702_MY2021_Tx" SG_ 1055 EcoCochCrus_Pc_Dsply 1;
BA_ "U_T6_MCA_MY2020_Tx" SG_ 1055 EcoCochCrus_Pc_Dsply 1;
BA_ "U_CD542_MY2021_Tx" SG_ 1055 EcoCochCrus_Pc_Dsply 1;
BA_ "U_U55X_MY2022_Tx" SG_ 1055 EcoCochCrus_Pc_Dsply 1;
BA_ "U_CD764_MY2022_Tx" SG_ 1055 EcoCochCrus_Pc_Dsply 1;
BA_ "GenSigStartValueInteger" SG_ 1055 EcoCochA_Pc_Dsply 255;
BA_ "GenSigStartValue" SG_ 1055 EcoCochA_Pc_Dsply 255;
BA_ "U_T6_MCA_MY2020_Rx" SG_ 1055 EcoCochA_Pc_Dsply 1;
BA_ "ECGUsedRxSignal" SG_ 1055 EcoCochA_Pc_Dsply 1;
BA_ "U_U55X_MY2022_Rx" SG_ 1055 EcoCochA_Pc_Dsply 1;
BA_ "U_CD764_MY2022_Rx" SG_ 1055 EcoCochA_Pc_Dsply 1;
BA_ "U_CX727_MY2021_Tx" SG_ 1055 EcoCochA_Pc_Dsply 1;
BA_ "U_P702_MY2021_Tx" SG_ 1055 EcoCochA_Pc_Dsply 1;
BA_ "U_T6_MCA_MY2020_Tx" SG_ 1055 EcoCochA_Pc_Dsply 1;
BA_ "U_CD542_MY2021_Tx" SG_ 1055 EcoCochA_Pc_Dsply 1;
BA_ "U_U55X_MY2022_Tx" SG_ 1055 EcoCochA_Pc_Dsply 1;
BA_ "U_CD764_MY2022_Tx" SG_ 1055 EcoCochA_Pc_Dsply 1;
BA_ "U_CX727_MY2021_Tx" SG_ 610 AwdLckWhlRr_Pc_RqDsply 1;
BA_ "U_T6_MCA_MY2020_Tx" SG_ 610 AwdLckWhlRr_Pc_RqDsply 1;
BA_ "U_CX727_MY2021_Tx" SG_ 610 AwdLckWhlRl_Pc_RqDsply 1;
BA_ "U_T6_MCA_MY2020_Tx" SG_ 610 AwdLckWhlRl_Pc_RqDsply 1;
BA_ "U_CX727_MY2021_Tx" SG_ 610 AwdLckWhlFr_Pc_RqDsply 1;
BA_ "U_T6_MCA_MY2020_Tx" SG_ 610 AwdLckWhlFr_Pc_RqDsply 1;
BA_ "U_CX727_MY2021_Tx" SG_ 610 AwdLckWhlFl_Pc_RqDsply 1;
BA_ "U_T6_MCA_MY2020_Tx" SG_ 610 AwdLckWhlFl_Pc_RqDsply 1;
BA_ "ContentDependant" SG_ 562 GearNtrl_No_Cs 1;
BA_ "MetaData" SG_ 562 GearNtrl_No_Cs 1;
BA_ "U_CX727_MY2021_Rx" SG_ 562 GearNtrl_No_Cs 1;
BA_ "U_T6_MCA_MY2020_Rx" SG_ 562 GearNtrl_No_Cs 1;
BA_ "U_CD542_MY2021_Rx" SG_ 562 GearNtrl_No_Cs 1;
BA_ "U_CD764_MY2022_Rx" SG_ 562 GearNtrl_No_Cs 1;
BA_ "U_P702_MY2021_Tx" SG_ 562 GearNtrl_No_Cs 1;
BA_ "U_T6_MCA_MY2020_Tx" SG_ 562 GearNtrl_No_Cs 1;
BA_ "U_CD542_MY2021_Tx" SG_ 562 GearNtrl_No_Cs 1;
BA_ "GenSigSendType" SG_ 562 GearNtrl_D_Stat 3;
BA_ "GenSigStartValueInteger" SG_ 562 GearNtrl_D_Stat 2;
BA_ "GenSigStartValue" SG_ 562 GearNtrl_D_Stat 2;
BA_ "U_CX727_MY2021_Rx" SG_ 562 GearNtrl_D_Stat 1;
BA_ "U_P702_MY2021_Rx" SG_ 562 GearNtrl_D_Stat 1;
BA_ "U_T6_MCA_MY2020_Rx" SG_ 562 GearNtrl_D_Stat 1;
BA_ "U_CD542_MY2021_Rx" SG_ 562 GearNtrl_D_Stat 1;
BA_ "U_U55X_MY2022_Rx" SG_ 562 GearNtrl_D_Stat 1;
BA_ "U_CD764_MY2022_Rx" SG_ 562 GearNtrl_D_Stat 1;
BA_ "U_P702_MY2021_Tx" SG_ 562 GearNtrl_D_Stat 1;
BA_ "U_T6_MCA_MY2020_Tx" SG_ 562 GearNtrl_D_Stat 1;
BA_ "U_CD542_MY2021_Tx" SG_ 562 GearNtrl_D_Stat 1;
BA_ "ContentDependant" SG_ 562 GearNtrl_No_Cnt 1;
BA_ "MetaData" SG_ 562 GearNtrl_No_Cnt 1;
BA_ "U_CX727_MY2021_Rx" SG_ 562 GearNtrl_No_Cnt 1;
BA_ "U_T6_MCA_MY2020_Rx" SG_ 562 GearNtrl_No_Cnt 1;
BA_ "U_CD542_MY2021_Rx" SG_ 562 GearNtrl_No_Cnt 1;
BA_ "U_CD764_MY2022_Rx" SG_ 562 GearNtrl_No_Cnt 1;
BA_ "U_P702_MY2021_Tx" SG_ 562 GearNtrl_No_Cnt 1;
BA_ "U_T6_MCA_MY2020_Tx" SG_ 562 GearNtrl_No_Cnt 1;
BA_ "U_CD542_MY2021_Tx" SG_ 562 GearNtrl_No_Cnt 1;
BA_ "U_T6_MCA_MY2020_Rx" SG_ 517 FapLc_B_Err 1;
BA_ "U_CD542_MY2021_Rx" SG_ 517 FapLc_B_Err 1;
BA_ "U_U55X_MY2022_Rx" SG_ 517 FapLc_B_Err 1;
BA_ "U_CD764_MY2022_Rx" SG_ 517 FapLc_B_Err 1;
BA_ "U_CX727_MY2021_Tx" SG_ 517 FapLc_B_Err 1;
BA_ "U_P702_MY2021_Tx" SG_ 517 FapLc_B_Err 1;
BA_ "U_T6_MCA_MY2020_Tx" SG_ 517 FapLc_B_Err 1;
BA_ "U_CD542_MY2021_Tx" SG_ 517 FapLc_B_Err 1;
BA_ "U_CD764_MY2022_Tx" SG_ 517 FapLc_B_Err 1;
BA_ "U_CX727_MY2021_Rx" SG_ 517 BrkTot_Tq_RqFapLc 1;
BA_ "U_P702_MY2021_Rx" SG_ 517 BrkTot_Tq_RqFapLc 1;
BA_ "U_T6_MCA_MY2020_Rx" SG_ 517 BrkTot_Tq_RqFapLc 1;
BA_ "U_CD542_MY2021_Rx" SG_ 517 BrkTot_Tq_RqFapLc 1;
BA_ "U_U55X_MY2022_Rx" SG_ 517 BrkTot_Tq_RqFapLc 1;
BA_ "U_CD764_MY2022_Rx" SG_ 517 BrkTot_Tq_RqFapLc 1;
BA_ "U_CX727_MY2021_Tx" SG_ 517 BrkTot_Tq_RqFapLc 1;
BA_ "U_P702_MY2021_Tx" SG_ 517 BrkTot_Tq_RqFapLc 1;
BA_ "U_T6_MCA_MY2020_Tx" SG_ 517 BrkTot_Tq_RqFapLc 1;
BA_ "U_CD542_MY2021_Tx" SG_ 517 BrkTot_Tq_RqFapLc 1;
BA_ "U_U55X_MY2022_Tx" SG_ 517 BrkTot_Tq_RqFapLc 1;
BA_ "U_CD764_MY2022_Tx" SG_ 517 BrkTot_Tq_RqFapLc 1;
VAL_ 535 WhlRr_W_Meas 32767 "Fault" 32766 "Unknown" ;
VAL_ 535 WhlRl_W_Meas 32767 "Fault" 32766 "Unknown" ;
VAL_ 535 WhlFr_W_Meas 32767 "Fault" 32766 "Unknown" ;
VAL_ 535 WhlFl_W_Meas 32767 "Fault" 32766 "Unknown" ;
VAL_ 534 WhlDirRr_D_Actl 3 "Faulty" 2 "NoDataExists" 1 "Backward" 0 "Forward" ;
VAL_ 534 WhlDirRl_D_Actl 3 "Faulty" 2 "NoDataExists" 1 "Backward" 0 "Forward" ;
VAL_ 534 WhlDirFr_D_Actl 3 "Faulty" 2 "NoDataExists" 1 "Backward" 0 "Forward" ;
VAL_ 534 WhlDirFl_D_Actl 3 "Faulty" 2 "NoDataExists" 1 "Backward" 0 "Forward" ;
VAL_ 532 RgenTqFalt_B_Actl 1 "Fault" 0 "No_Fault" ;
VAL_ 532 RgenBrkDynoMde_B_Actl 1 "TwoWheelDyno" 0 "NormalOperation" ;
VAL_ 531 PrkBrkMsgTxt_D_Rq 15 "Message15" 14 "Message14" 13 "Message13" 12 "Message12" 11 "Message11" 10 "Message10" 9 "Message9" 8 "Message8" 7 "Message7" 6 "Message6" 5 "Message5" 4 "Message4" 3 "Message3" 2 "Message2" 1 "Message1" 0 "No_Message" ;
VAL_ 531 VehStop_D_Stat 3 "Faulty" 2 "NoDataExists" 1 "Yes" 0 "No" ;
VAL_ 531 TracCtlPtActv_B_Actl 1 "Active" 0 "Inactive" ;
VAL_ 531 VehicleStationary 1 "Yes" 0 "No" ;
VAL_ 531 AbsActv_B_Actl 1 "Yes" 0 "No" ;
VAL_ 531 StabCtlBrkActv_B_Actl 1 "Yes" 0 "No" ;
VAL_ 531 CmbbBrkPrchg_B_Actl 1 "Yes" 0 "No" ;
VAL_ 531 CmbbBrkDecel_B_Actl 1 "Yes" 0 "No" ;
VAL_ 531 CmbbBaSensInc_B_Actl 1 "Yes" 0 "No" ;
VAL_ 531 AccBrkWarm_B_Actl 1 "Yes" 0 "No" ;
VAL_ 531 AccBrkTotTqMn_B_Actl 1 "Yes" 0 "No" ;
VAL_ 531 AccBrkPrchgActv_B_Actl 1 "Yes" 0 "No" ;
VAL_ 531 AccBrkDis_B_Actl 1 "Yes" 0 "No" ;
VAL_ 531 AccBrkDeny_B_Actl 1 "Yes" 0 "No" ;
VAL_ 531 AccBrkActv_B_Actl 1 "Yes" 0 "No" ;
VAL_ 531 PrplDrgCtlActv_B_Actl 1 "Active" 0 "Inactive" ;
VAL_ 531 CmbbBrkDis_B_Actl 1 "Yes" 0 "No" ;
VAL_ 531 CmbbDeny_B_ActlBrk 1 "Yes" 0 "No" ;
VAL_ 531 CcDis_B_Cmd 1 "Yes" 0 "No" ;
VAL_ 531 VehLongOvrGnd_A_Est 1023 "Fault" 1022 "Unknown" ;
VAL_ 531 AccStopActv_B_ActlBrk 1 "Yes" 0 "No" ;
VAL_ 531 AccDis_B_ActlEpb 1 "Yes" 0 "No" ;
VAL_ 531 PrkBrkStatus 7 "GeneralFault_MaintenceMode" 6 "ECD_by_Brake_ECU_Active" 5 "EPB_Limphome_Active" 4 "Rear_Caliper_Open" 3 "RWU_By_EPB_Active" 2 "Rear_Caliper_Transition" 1 "Rear_Caliper_Closed" 0 "Not_Supported" ;
VAL_ 531 PrkBrkYwLamp_D_Rq 3 "Fast_Flash" 2 "Slow_Flash" 1 "On" 0 "Off" ;
VAL_ 531 PrkBrkRedLamp_D_Rq 3 "Fast_Flash" 2 "Slow_Flash" 1 "On" 0 "Off" ;
VAL_ 125 VehRolComp_W_Actl 4094 "NoDataExists" 4095 "Fault" ;
VAL_ 125 VehVertComp_A_Actl 1022 "NoDataExists" 1023 "Fault" ;
VAL_ 125 BrkTot_Tq_RqArb 8191 "Fault" 8190 "Unknown" ;
VAL_ 125 BrkTot_Tq_Actl 8191 "Fault" 8190 "Unknown" ;
VAL_ 125 HsaStat_D_Actl 7 "Faulty" 6 "FaultyWithDriverIndication" 5 "SlowRelease" 4 "FastRelease" 3 "ActiveBrakePedalReleased" 2 "ActiveBrakePedalPressed" 1 "FindingGradient" 0 "Inactive" ;
VAL_ 119 VehTrvlDir_D_Stat 7 "Faulty" 6 "NoDataExists" 5 "NotUsed2" 4 "NotUsed1" 3 "Reverse" 2 "LikelyReverse" 1 "Forward" 0 "LikelyForward" ;
VAL_ 119 VehOverGnd_V_Est 65535 "Invalid" 65534 "Unknown" ;
VAL_ 119 VehLongComp_A_Actl 1023 "Fault" 1022 "NoDataExists" ;
VAL_ 119 VehLatComp_A_Actl 1023 "Fault" 1022 "NoDataExists" ;
VAL_ 119 VehYawComp_W_Actl 4095 "Fault" 4094 "NoDataExists" ;
VAL_ 118 BrkCtrFnd_B_Stat 1 "Yes" 0 "No" ;
VAL_ 118 DrvSte_D_Stat 15 "NotUsed10" 14 "NotUsed9" 13 "NotUsed8" 12 "NotUsed7" 11 "NotUsed6" 10 "NotUsed5" 9 "NotUsed4" 8 "NotUsed3" 7 "NotUsed2" 6 "NotUsed1" 5 "Request_Active" 4 "Ignition_Off" 3 "DSR_in_Normal_Idle_Mode" 2 "EPAS_Comm_Disturbed" 1 "DSR_Request_Not_Applicable" 0 "DSR_Deactivated" ;
VAL_ 118 DrvSte_Tq_Rq 255 "Invalid" 254 "Unknown" ;
VAL_ 118 EmgcyBrkLamp_D_Rq 3 "NotUsed" 2 "Active_at_standstill" 1 "Active_at_speed" 0 "Inactive" ;
VAL_ 118 StopLamp_B_RqBrk 1 "Active" 0 "Inactive" ;
VAL_ 118 SteWhlCompAnEst_D_Qf 3 "OK" 2 "Not_Within_Specifications" 1 "No_Data_Exists" 0 "Faulty" ;
VAL_ 73 immoSubTarget1Cmd_T1 7 "Unused3" 6 "DEFAULT_RESET" 5 "ECHO_TARGET1_IDBLOCK2" 4 "Unused1" 3 "RQST_TARGET1_IDBLOCK2" 2 "RQST_TARGET1_IDBLOCK1" 1 "RESPONSE" 0 "IDLE" ;
VAL_ 561 TrnMsgTxt2_D_Rq 7 "NotUsed3" 6 "NotUsed2" 5 "NotUsed1" 4 "TransTooHot_LoudChime" 3 "PressBrake_LoudChime" 2 "PressBrake_SoftChime" 1 "PressBrake_NoChime" 0 "NoText_NoChime" ;
VAL_ 561 TrnMsgTxt_D_Rq 15 "Message_15" 14 "Message_14" 13 "Message_13" 12 "Message_12" 11 "Message_11" 10 "Message_10" 9 "Message_9" 8 "Message_8" 7 "Message_7" 6 "Message_6" 5 "Message_5" 4 "Message_4" 3 "Message_3" 2 "Message_2" 1 "Message_1" 0 "NoMessage" ;
VAL_ 1090 VehElRnge_L_Dsply 4094 "NoDataExists" 4095 "Fault" ;
VAL_ 1090 Mtr2State_D_ActlMntr 7 "Faulty" 6 "NoDataExists" 5 "NotUsed_1" 4 "ReadinessState" 3 "DeactivationState" 2 "PowerGeneration" 1 "PowerConsumption" 0 "Null" ;
VAL_ 1090 Inv1Ain_I_ActlMntr 32767 "Faulty" 32766 "NoDataExists" ;
VAL_ 1090 HybVehMde_D_ActlMntr 7 "Faulty" 6 "NoDataExists" 5 "NotUsed_2" 4 "NotUsed_1" 3 "Fuel" 2 "HybridElectric" 1 "AllElectric" 0 "Null" ;
VAL_ 1090 ChrgStat_D_ActlMntr 7 "Faulty" 6 "NoDataExists" 5 "NotUsed" 4 "ChargingCompleted" 3 "NotCharging" 2 "ChargingInDrivingState" 1 "ChargingInParkingState" 0 "Null" ;
VAL_ 870 PolicePurstMde_B_Stat 1 "On" 0 "Off" ;
VAL_ 870 RngPerChrgInst_L_Dsply 4095 "Faulty" 4094 "NoDataExists" ;
VAL_ 870 ChkPlgtoStrt_D_Dsply 3 "NotUsed" 2 "Is_VehicleUnplugged_Prompt" 1 "Check_Plug_to_Start" 0 "No_Message_Display" ;
VAL_ 870 HybMdeLimMsgTxt_D_Rq 3 "Limited_Req_Full_Defrost" 2 "Limited_Climate_Defrost" 1 "Limited_System_Performance" 0 "Null" ;
VAL_ 870 HybMdeMsgTxt_D2_Rq 15 "NotUsed_4" 14 "NotUsed_3" 13 "NotUsed_2" 12 "NotUsed_1" 11 "EvOverride_Avail" 10 "EvLaterActv_EvAuto_NowAvai" 9 "EvNowActv_EvAuto_LaterAvai" 8 "EvAutoActv_EvNow_LaterAvai" 7 "EvAutoActv_NoOtherMdeAvail" 6 "EvChrgActv_EvAutoMdeAvail" 5 "EvAutoActv_EvChrgMdeAvail" 4 "EvChrgActv_AllPhevMdeAvail" 3 "EvLaterActv_AllPhevMdeAvai" 2 "EvNowActv_AllPhevMdeAvail" 1 "EvAutoActv_AllPhevMdeAvail" 0 "Null" ;
VAL_ 870 EngMdeMsgTxt_D_Rq 7 "NotUsed_3" 6 "NotUsed_2" 5 "NotUsed_1" 4 "Charge" 3 "GlowingCharge" 2 "Hybrid" 1 "Ev" 0 "NoMessage" ;
VAL_ 870 ShifOutNtrlMsgTxt_D_Rq 7 "Message7" 6 "Message6" 5 "Message5" 4 "Message4" 3 "Message3" 2 "Message2" 1 "Message1" 0 "NoMessage" ;
VAL_ 869 PwrFlowTxt_D_Dsply 15 "NotUsed7" 14 "NotUsed6" 13 "NotUsed5" 12 "NotUsed4" 11 "Disply_Rgen_Chrg_Txt" 10 "Disp_Fast_Charge_Txt" 9 "Disp_Fast_Charge_Cmplt_Txt" 8 "Disp_Charge_Cmplt_Txt" 7 "Disp_Remote_Start_Txt" 6 "Disp_Eng_Drv_Txt" 5 "Disp_Elec_Drv_Txt" 4 "Disp_Idle_with_Chrg_Txt" 3 "Disp_Idle_Txt" 2 "Disp_Charg_HV_Batt_Txt" 1 "Disp_Hyb_Drive_Txt" 0 "No_Text" ;
VAL_ 869 EngOnMsg2_D_Dsply 14 "_0xE_to_1F_NotUsed" 12 "Battery_Temperature" 11 "Hill_Decent_Control" 10 "Fuel_Maintenance" 9 "Oil_Maintenance" 8 "Normal_Operation" 7 "Low_Gear" 6 "Batt_Charging" 5 "Engine_Cold" 4 "Neutral_Gear" 3 "Heater_Setting" 2 "High_Speed" 1 "Acceleration" 0 "No_Display" 13 "Drive_Mode_Selection" ;
VAL_ 869 EngOnMsg1_D_Dsply 14 "_0xE_to_1F_NotUsed" 12 "Battery_Temperature" 11 "Hill_Decent_Control" 10 "Fuel_Maintenance" 9 "Oil_Maintenance" 8 "Normal_Operation" 7 "Low_Gear" 6 "Batt_Charging" 5 "Engine_Cold" 4 "Neutral_Gear" 3 "Heater_Setting" 2 "High_Speed" 1 "Acceleration" 0 "No_Display" 13 "Drive_Mode_Selection" ;
VAL_ 869 FuelMaintMde_D_Dsply 3 "Feature_Not_Present" 2 "In_Fuel_Maint_Mode" 1 "Close_to_Fuel_Maint" 0 "OK" ;
VAL_ 869 RgenActv_B_Dsply 1 "On" 0 "Off" ;
VAL_ 869 EngOffTe_B_Dsply 1 "Eng_warm_engh_for_pd" 0 "Eng_not_warm_engh_for_pd" ;
VAL_ 869 EngActv_B_Dsply 1 "On" 0 "Off" ;
VAL_ 869 EffWhlThresOn_B_Dsply 1 "On" 0 "Off" ;
VAL_ 869 DchrgActv_B_Dsply 1 "On" 0 "Off" ;
VAL_ 869 ChrgActv_B_Dsply 1 "On" 0 "Off" ;
VAL_ 606 BattTracThrml_D_Stat 15 "NotUsed_5" 14 "NotUsed_4" 13 "NotUsed_3" 12 "NotUsed_2" 11 "NotUsed_1" 10 "SysFill" 9 "AirPurge" 8 "VlvCalib" 7 "InActvHeaterCoreClntFlw" 6 "ActvHeaterCoreClntFlw" 5 "MxChlrClntFlw" 4 "ChlrClntFlw" 3 "RadClntFlwFan" 2 "RadClntFlwWoFan" 1 "ClntFlw" 0 "ThrmlSysOff" ;
VAL_ 606 ElVehChrgMde_D_Stat 3 "NotUsed" 2 "Available" 1 "NotAvailable" 0 "Null" ;
VAL_ 606 ElVehLaterMde_D_Stat 3 "NotUsed" 2 "Available" 1 "NotAvailable" 0 "Null" ;
VAL_ 606 ElVehNowMde_D_Stat 3 "NotUsed" 2 "Available" 1 "NotAvailable" 0 "Null" ;
VAL_ 374 GearEngag_D_Actl 7 "Undefined" 6 "Fwd_Clutch_Fully_Engaged" 5 "Neutral_Idle" 4 "Disengaged_to_Neutral_Idle" 3 "Disengaged_to_Neutral_Park" 2 "Engagement_in_Progress" 1 "InitializeFwdClutchEngagmt" 0 "Park_Neutral" ;
VAL_ 374 TrnRng_D_Rq 15 "Fault" 14 "Unknown_Position" 13 "NotUsed_2" 12 "NotUsed_1" 11 "Range6" 10 "Range5" 9 "Range4" 8 "Range3_M3_L3" 7 "Range2_M2_L2" 6 "Range1_M1_L1" 5 "Low" 4 "Sport_DriveSport_Mposition" 3 "Drive" 2 "Neutral" 1 "Reverse" 0 "Park" ;
VAL_ 374 TrnPrkSys_D_Actl 15 "Faulty" 14 "NotUsed_5" 13 "NotUsed_4" 12 "NotUsed_3" 11 "NotUsed_2" 10 "NotUsed_1" 9 "FrequencyError" 8 "OutOfRangeHigh" 7 "OutOfRangeLow" 6 "Override" 5 "OutOfPark" 4 "TransitionCloseToOutOfPark" 3 "AtNoSpring" 2 "TransitionCloseToPark" 1 "Park" 0 "NotKnown" ;
VAL_ 374 GearLvr_D_ActlDrv 15 "Fault" 14 "Unknown_Position" 13 "NotUsed_2" 12 "NotUsed_1" 11 "Range6" 10 "Range5" 9 "Range4" 8 "Range3_M3_L3" 7 "Range2_M2_L2" 6 "Range1_M1_L1" 5 "Low" 4 "Sport_DriveSport_Mposition" 3 "Drive" 2 "Neutral" 1 "Reverse" 0 "Park" ;
VAL_ 374 GearPos_D_Trg 15 "Unknown" 14 "Reverse" 13 "Undefined_5" 12 "Undefined_4" 11 "Undefined_3" 10 "Tenth" 9 "Ninth" 8 "Eighth" 7 "Seventh" 6 "Sixth" 5 "Fifth" 4 "Fourth" 3 "Third" 2 "Second" 1 "First" 0 "Neutral" ;
VAL_ 374 GearPos_D_Actl 15 "Unknown" 14 "Reverse" 13 "Undefined_5" 12 "Undefined_4" 11 "Undefined_3" 10 "Tenth" 9 "Ninth" 8 "Eighth" 7 "Seventh" 6 "Sixth" 5 "Fifth" 4 "Fourth" 3 "Third" 2 "Second" 1 "First" 0 "Neutral" ;
VAL_ 603 FuelCtlOpenLp_B_Inhbt 1 " Inhibit_FullPedal_Actions" 0 "Normal_Operation" ;
VAL_ 603 EngDiag_D_RqHtrn 7 "NotUsed4" 6 "NotUsed3" 5 "NotUsed2" 4 "NoUsed1" 3 "Eng_Diag_Cstdn" 2 "Eng_Diag_Run" 1 "Eng_Diag_Crank" 0 "Eng_Diag_Normal" ;
VAL_ 603 WhlDirAvgDrv_D_Actl 3 "Faulty" 2 "NoDataExists" 1 "Backward" 0 "Forward" ;
VAL_ 603 PrplTqMnRgen_B_Actl 1 "Yes" 0 "No" ;
VAL_ 603 EDrvTqMntrRconfg_D_Cmd 7 "OK" 6 "Disable_Cruise" 5 "NotUsed4" 4 "Supercreep" 3 "NotUsed3" 2 "NotUsed2" 1 "Engine_shutdown" 0 "NotUsed" ;
VAL_ 603 BattTracCnnct_D_Rq 3 "Undefined" 2 "Retain" 1 "Close" 0 "Open" ;
VAL_ 602 HtrnWarnLamp_B_Dsply 1 "On" 0 "Off" ;
VAL_ 602 PtcHtrRun_B_Rq 1 "On" 0 "Off" ;
VAL_ 602 PwPckTqRdy_B_Dsply 1 "On" 0 "Off" ;
VAL_ 602 ObdEngStdy_B_Stat 1 "Yes" 0 "No" ;
VAL_ 602 EngStrtSrvc_B_Allw 1 "Yes" 0 "No" ;
VAL_ 1152 VehElEff_No_Avg 127 "Faulty" 126 "NoDataExists" ;
VAL_ 1152 PwCabinEnblScnd_B_Rq 1 "Enable" 0 "Disable" ;
VAL_ 1152 PwCabinEnbl_B_Rq 1 "Enable" 0 "Disable" ;
VAL_ 1152 PwTrnkFrntEnblScnd_B_Rq 1 "Enable" 0 "Disable" ;
VAL_ 1152 PwTrnkFrntEnbl_B_Rq 1 "Enable" 0 "Disable" ;
VAL_ 1152 PwOutlet8EnblScnd_B_Rq 1 "Enable" 0 "Disable" ;
VAL_ 1152 PwOutlet8Enbl_B_Rq 1 "Enable" 0 "Disable" ;
VAL_ 1152 PwOutlet7EnblScnd_B_Rq 1 "Enable" 0 "Disable" ;
VAL_ 1152 PwOutlet7Enbl_B_Rq 1 "Enable" 0 "Disable" ;
VAL_ 1152 PwOutlet6EnblScnd_B_Rq 1 "Enable" 0 "Disable" ;
VAL_ 1152 PwOutlet6Enbl_B_Rq 1 "Enable" 0 "Disable" ;
VAL_ 1152 HybPwULoLamp_B_Rq 1 "On" 0 "Off" ;
VAL_ 1152 GrdAsstActv_B_Stat 1 "On" 0 "Off" ;
VAL_ 1152 EngTeHi_B_Actl 1 "EngineTempHigh" 0 "Normal" ;
VAL_ 1152 DcdcOn_B_Rq 1 "On" 0 "Off" ;
VAL_ 1152 ULoBattSpprtSustn_B_Rq 1 "Active" 0 "Inactive" ;
VAL_ 1152 BattTracDiagClr_B_Stat 1 "On" 0 "Off" ;
VAL_ 872 PwFlowPlgBatt_D_Dsply 3 "NotUsed" 2 "Flow_from_Plug_to_Batt" 1 "Flow_from_Batt_to_Plug" 0 "No_Flow" ;
VAL_ 872 PwFlowMtrDrv_D_Dsply 3 "NotUsed" 2 "Flow_from_Mtr_to_Axle" 1 "Flow_from_Axle_to_Mtr" 0 "No_FLow" ;
VAL_ 872 PwFlowEngMtr_D_Dsply 3 "NotUsed" 2 "Flow_from_Eng_to_Mtr" 1 "Flow_from_Mtr_to_Eng" 0 "No_Flow" ;
VAL_ 872 PwFlowEngFuel_D_Dsply 3 "NotUsed" 2 "Flow_from_Eng_to_Fuel" 1 "Flow_from_Fuel_to_Eng" 0 "No_Flow" ;
VAL_ 872 PwFlowEngDrv_D_Dsply 3 "NotUsed" 2 "Flow_from_Eng_to_Axle" 1 "Flow_from_Axle_to_Eng" 0 "No_Flow" ;
VAL_ 872 PwFlowBattMtr_D_Dsply 3 "NotUsed" 2 "Flow_from_Batt_to_Mtr" 1 "Flow_from_Mtr_to_Batt" 0 "No_Flow" ;
VAL_ 872 PlgActvArb_B_Dsply 1 "On" 0 "Off" ;
VAL_ 872 HybMdeStat_D_Dsply 7 "NotUsed2" 6 "EV_Charge" 5 "EV_Override" 4 "Forced_EV_Mode" 3 "Forced_Charge_Sustain_Mode" 2 "Auto_Charge_Sustain_Mode" 1 "Auto_Charge_Deplete_Mode" 0 "Null_State" ;
VAL_ 872 EcoMode_B_Stat 1 "On" 0 "Off" ;
VAL_ 560 CleanerHeater_D_Stat 3 "NotUsed" 2 "Maintain" 1 "Heat" 0 "Inactive" ;
VAL_ 560 SelDrvMdeSwtch_D_Stat3 3 "Faulty" 2 "SwitchState2" 1 "SwitchState1" 0 "NotPressed" ;
VAL_ 560 TrnGbox_Rt_Actl 65535 "Fault" 65534 "Unknown" ;
VAL_ 560 TrnSrvcRqd_B_Rq 1 "On" 0 "Off" ;
VAL_ 560 TrnCnvtClu_D_Actl 3 "Transition_or_Micro_Slip" 2 "Lock_Up_Fixed" 1 "Lock_Up_Slip" 0 "No_Lock_Up" ;
VAL_ 560 TrnShifActv_B_Actl 1 "Active" 0 "Inactive" ;
VAL_ 560 RtmTerrMdeChng_D_Rdy 7 "Fault" 6 "Undefined_2" 5 "Undefined_1" 4 "ModeUnavailDrInputRqd" 3 "SpOpModes_NotSupported" 2 "ModeUnavailDynamicCond" 1 "Module_In_Initialization" 0 "Mode_Change_Available" ;
VAL_ 560 RtmTerrMde_D_Actl 7 "Fail_Safe_Default" 6 "Dynamic_Mode" 5 "Rock_Crawl_Mode" 4 "Mud_Ruts_Mode" 3 "Sand_Mode" 2 "Undefined" 1 "Low_Mu_Mode" 0 "Special_Operating_Mode_Off" ;
VAL_ 560 GearLvrPos_D_Actl 15 "Fault" 14 "Unknown_Position" 13 "Undefined_Treat_as__Fault" 12 "Undefined_Treat_as_Fault" 11 "sixth" 10 "fifth" 9 "fourth" 8 "third" 7 "second" 6 "first" 5 "Low" 4 "Sport_DriveSport" 3 "Drive" 2 "Neutral" 1 "Reverse" 0 "Park" ;
VAL_ 560 GboxOil_Te_Actl 255 "Faulty" 254 "NoDataExists" ;
VAL_ 369 TrnIpcDsplyRng2_D_Actl 15 "No_Range_Selected" 14 "Range_14" 13 "Range_13" 12 "Range_12" 11 "Range_11" 10 "Range_10" 9 "Range_9" 8 "Range_8" 7 "Range_7" 6 "Range_6" 5 "Range_5" 4 "Range_4" 3 "Range_3" 2 "Range_2" 1 "Range_1" 0 "NotUsed" ;
VAL_ 369 TrnIpcDsplyRng_D_Stat 3 "NotUsed" 2 "Flash" 1 "On" 0 "Blank_No_Display" ;
VAL_ 369 TrnIpcDsplyGear_D_Actl 15 "No_Gear_Selected" 14 "_14th_Gear" 13 "_13th_Gear" 12 "_12th_Gear" 11 "_11th_Gear" 10 "_10th_Gear" 9 "_9th_Gear" 8 "_8th_Gear" 7 "_7th_Gear" 6 "_6th_Gear" 5 "_5th_Gear" 4 "_4th_Gear" 3 "_3rd_Gear" 2 "_2nd_Gear" 1 "_1st_Gear" 0 "Neutral" ;
VAL_ 369 TrnIpcDsplyMde_D_Stat 3 "Reserved_Blank_No_Display" 2 "Flash" 1 "On" 0 "Blank_No_Display" ;
VAL_ 369 TrnIpcDsplyMde_D_Actl 7 "Manual_3" 6 "Manual_2" 5 "Manual_1_Low" 4 "Sport" 3 "Drive" 2 "Neutral" 1 "Reverse" 0 "Park" ;
VAL_ 369 TrnIpcDsplyGear_D_Stat 3 "Reserved_Blank_No_Display" 2 "Flash" 1 "On" 0 "Blank_No_Display" ;
VAL_ 92 TrnGearMsgTxt2_D_Rq 31 "Message31" 30 "Message30" 29 "Message29" 28 "Message28" 27 "Message27" 26 "Message26" 25 "Message25" 24 "Message24" 23 "Message23" 22 "Message22" 21 "Message21" 20 "Message20" 19 "Message19" 18 "Message18" 17 "Message17" 16 "Message16" 15 "Message15" 14 "Message14" 13 "Message13" 12 "Message12" 11 "Message11" 10 "Message10" 9 "Message9" 8 "Message8" 7 "Message7" 6 "Message6" 5 "Message5" 4 "Message4" 3 "Message3" 2 "Message2" 1 "Message1" 0 "NoMessage" ;
VAL_ 92 TrnSbwSysHlth_D_Actl 3 "OK" 2 "Degraded" 1 "No_Data_Exists" 0 "Faulty" ;
VAL_ 92 TrnLvrV_D_Rq 3 "Full_Speed" 2 "Aggressive" 1 "Normal" 0 "Quiet" ;
VAL_ 92 TrnGearNtmAllow_B_Stat 1 "Yes" 0 "No" ;
VAL_ 92 TrnDtpCmd_D_Actl 7 "NotUsed4" 6 "NotUsed3" 5 "NotUsed2" 4 "Relatch" 3 "Deploy" 2 "Self_Test" 1 "No_Command" 0 "NotUsed1" ;
VAL_ 92 GearSelLck_D_Rq 3 "PreventionBlocker" 2 "Unlock" 1 "Lock" 0 "Null" ;
VAL_ 92 TrnValidGear_D_Cnfm 3 "Accept" 2 "Reject" 1 "Internal_Request" 0 "No_Command" ;
VAL_ 92 TrnNtrlTowCmd_D_Actl 3 "NotUsed" 2 "Neutral_Tow_Entry" 1 "Car_Wash_Mode" 0 "Normal_Mode" ;
VAL_ 92 TrnGearCmd_Pc_ActlPt 1023 "Fault" ;
VAL_ 92 TrnGear_D_RqPt 7 "Fault" 6 "NotUsed" 5 "Manual" 4 "Drive" 3 "Neutral" 2 "Reverse" 1 "Park" 0 "No_Gear" ;
VAL_ 92 TrnCmdState_B_Actl 1 "Yes" 0 "No" ;
VAL_ 92 PrkBrkActv_D_RqTrnGear 3 "NotUsed2" 2 "RequestParkBrakeEngage" 1 "NoRequest" 0 "NotUsed1" ;
VAL_ 92 TrnGearMsgTxt_D_Rq 15 "Message_15" 14 "Message_14" 13 "Message_13" 12 "Message_12" 11 "Message_11" 10 "Message_10" 9 "Message_9" 8 "Message_8" 7 "Message_7" 6 "Message_6" 5 "Message_5" 4 "Message_4" 3 "Message_3" 2 "Message_2" 1 "Message_1" 0 "NoMessage" ;
VAL_ 1087 FapLcInhbt_B_Rq 1 "Yes" 0 "No" ;
VAL_ 1087 RepaLcGrdInhbt_B_Stat 1 "Yes" 0 "No" ;
VAL_ 1087 FapLcStopHold_B_Rq 1 "Yes" 0 "No" ;
VAL_ 1087 FapLcPrchgBrk_B_Rq 1 "Yes" 0 "No" ;
VAL_ 1087 FapLcObstcl_B_Stat 1 "Yes" 0 "No" ;
VAL_ 1087 FapLcMaxGrdInhbt_B_Stat 1 "Yes" 0 "No" ;
VAL_ 1087 FapLcMaxGrdAbrt_B_Stat 1 "Yes" 0 "No" ;
VAL_ 1087 FapLcActv_B_Stat 1 "Yes" 0 "No" ;
VAL_ 1087 AdasLcObtclAbrt_B_Stat 1 "Yes" 0 "No" ;
VAL_ 1100 WakeAlarm1_B_Typ 1 "CanAndEcuDriveCircuit" 0 "CanOnly" ;
VAL_ 1100 AutoTowAllw_D_StatMnu 3 "TowHaulCommandedOn" 2 "AutoTowHaulEnabled" 1 "AutoTowHaulDisabled" 0 "NoSelection" ;
VAL_ 1100 AutoTowActv_B_Stat 1 "Yes" 0 "No" ;
VAL_ 1100 GrossTrainWeight_M_Est 255 "Faulty" 254 "NoDataExists" ;
VAL_ 1100 HvacCmprLim_D_Stat 7 "NotUsed_2" 6 "NotUsed_1" 5 "CompressorHeadPressure" 4 "AvailableTorque" 3 "PedalPosition" 2 "RPM" 1 "ECT" 0 "NoLimit" ;
VAL_ 873 BattTracEMaint_B_Dsply 1 "On" 0 "Off" ;
VAL_ 873 EffRelTrgtOn_B_Dsply 1 "On" 0 "Off" ;
VAL_ 873 GpsElMdeActv_B_Dsply 1 "On" 0 "Off" ;
VAL_ 873 LoAirAmbPlgIn_B_Dsply 1 "On" 0 "Off" ;
VAL_ 871 BattElecPerf_D_Actl 7 "NotUsed" 6 "Hot_Batt_Severe_Lim_Perf" 5 "Hot_Batt_Reduced_Perf" 4 "Hot_Batt_Close_to_lim_Per" 3 "Cold_Batt_Severe_Lim_Perf" 2 "Cold_Batt_Reduced_Perf" 1 "Cold_Batt_Close_to_lim_Pe" 0 "Ok_no_message_displayed" ;
VAL_ 871 BattChrgTrgtLPt_T_Est 2047 "Faulty" 2046 "NoDataExists" ;
VAL_ 871 BattChrgTrgSocPt_T_Est 2047 "Faulty" 2046 "NoDataExists" ;
VAL_ 871 BattChrgCmpltPt_T_Est 2047 "Faulty" 2046 "NoDataExists" ;
VAL_ 871 DrvEffLvlIncDec_D_Cmd 3 "NotUsed" 2 "Decrease_Level_by_1" 1 "Increase_Level_by_1" 0 "Null_State" ;
VAL_ 1086 FuelPumpPwr_B_Rq 1 "On" 0 "Off" ;
VAL_ 1086 ElLoadCtl_D_Rq 7 "Unused3" 6 "Unused2" 5 "Unused1" 4 "HoldAllDrvrInvisibleLoads" 3 "StdDriverInvisibleLoadsOn" 2 "AllDriverInvisibleLoadsOn" 1 "All_Possible_Loads_Off" 0 "No_Request" ;
VAL_ 1085 ULoRgenTestMde_B_Stat 1 "Active" 0 "Inactive" ;
VAL_ 1085 PwSrcULoOvrTe_B_Actl 1 "Yes" 0 "No" ;
VAL_ 1085 PwSrcULoOn_B_Actl 1 "Operating" 0 "Not_Operating" ;
VAL_ 1085 PwSrcULoFalt_D_Stat 3 "Fault_No_Output" 2 "Fault_Reduced_Output" 1 "Fault_NonSpecific" 0 "No_Fault" ;
VAL_ 1085 PwSrcULoDcnnt_B_Stat 1 "Loose_or_Disconnected" 0 "Connected" ;
VAL_ 1085 PwSrcULo_Pc_Mx 255 "Fault" ;
VAL_ 1085 BattTracCool_D_RqDcdc 3 "NotUsed" 2 "DCDC_Overtemperature" 1 "CoolingRequiredbyDCDC" 0 "NoCoolingRequiredbyDCDC" ;
VAL_ 1085 PwSrcULoComm_B_Falt 1 "Fault" 0 "No_Fault" ;
VAL_ 1085 DcdcULo_U_Actl 255 "Fault" ;
VAL_ 1085 DcdcUHi_I_Actl 255 "Fault" ;
VAL_ 1085 PwSrcULo_I_Mx 255 "Fault" ;
VAL_ 1085 PwSrcULo_I_Actl 255 "Fault" ;
VAL_ 1085 DcdcUHi_U_Actl 1023 "Fault" 1022 "NoDataExists" ;
VAL_ 1071 CluPdlPosPcMeas_D_Qf 3 "OK" 2 "Not_Within_Specifications" 1 "No_Data_Exists" 0 "Faulty" ;
VAL_ 1069 SlMde_D_Stat 3 "IsaNotConfigured" 2 "Manual_Mode" 1 "Auto_Mode" 0 "Null" ;
VAL_ 1069 SlMde_D_RqDsply 3 "NotUsed" 2 "ManualSpeed_LimiterSymbol" 1 "AutoSpeed_LimiterSymbol" 0 "NoSpeed_LimiterSymbol" ;
VAL_ 1069 IsaOffst_D_Stat 15 "Faulty" 14 "Null" 13 "Thirteen" 12 "Twelve" 11 "Eleven" 10 "Ten" 9 "Nine" 8 "Eight" 7 "Seven" 6 "Six" 5 "Five" 4 "Four" 3 "Three" 2 "Two" 1 "One" 0 "Zero" ;
VAL_ 1069 ReFuelSysStat_D_Dsply 7 "NotUsed3" 6 "NotUsed2" 5 "NotUsed1" 4 "Refuel_Err" 3 "Close_Fuel_Door" 2 "Refuel_Ready" 1 "Wait_To_Fuel" 0 "Null" ;
VAL_ 1069 ULoSrcOnPlg_B_Cmd 1 "Activate" 0 "Deactivate" ;
VAL_ 1069 EngOilMaint_B_Stat 1 "On" 0 "Off" ;
VAL_ 1069 GrllShtrPos_D_Cmd 15 "Fully_Open" 14 "Position14" 13 "Position13" 12 "Position12" 11 "Position11" 10 "Position10" 9 "Position9" 8 "Position8" 7 "Position7" 6 "Position6" 5 "Position5" 4 "Position4" 3 "Position3" 2 "Position2" 1 "Position1" 0 "Fully_Closed" ;
VAL_ 1069 GrllShtrPos_B_Falt 1 "Fault" 0 "No_Fault" ;
VAL_ 1069 ObdWarmUp_B_Complt 1 "Yes" 0 "No" ;
VAL_ 1069 EngMsgTxt_D_Rq 3 "Undefined_2" 2 "Undefined_1" 1 "Power_Reduced_to_LowerTemp" 0 "No_Message" ;
VAL_ 1069 EngAirIn_Te_Actl 1023 "Fault" 1022 "Unknown" ;
VAL_ 1060 BpedDrvMsgTxt_B_Dsply 1 "On" 0 "Off" ;
VAL_ 1060 FuelLvlWarn_D_ActlEng 7 "DteLevel5Lowest" 6 "DteLevel4" 5 "DteLevel3" 4 "DteLevel2NonMyKey" 3 "DteLevel1MyKey" 2 "VeryLow" 1 "Low" 0 "OK" ;
VAL_ 1060 SelDrvMdePt_D_Stat 0 "NotAvailable" 1 "Available" 2 "TemporarilyNotAvailable" 3 "Faulty" ;
VAL_ 1057 EngIdlShutDwnTxt_D_Rq 3 "NotUsed" 2 "EngineShutdownOnPrevDrive" 1 "FeatureDisabledDueToFault" 0 "NoMessage" ;
VAL_ 1057 EngIdlShutDown_D_Stat 3 "Not_used" 2 "Engine_Shutdown" 1 "Initiated_Countdown" 0 "Normal_Operation" ;
VAL_ 1057 FUEL_ALCOHOL_PERCNT 255 "Invalid" ;
VAL_ 1057 ECMMILRequest 3 "Not_Used" 2 "Flash" 1 "On" 0 "Off" ;
VAL_ 1057 AirCondFluidHi_P_Actl 255 "Fault" 254 "Unknown" ;
VAL_ 1057 OilPressureWarning 1 "Low_Pressure_Lamp_On" 0 "Normal_Pressure_Lamp_Off" ;
VAL_ 1057 VehVLimActv_B_Actl 1 "Active" 0 "Inactive" ;
VAL_ 1057 CoolantFanStepAct 31 "Unused7" 30 "Unused6" 29 "Unused5" 28 "Unused4" 27 "Unused3" 26 "Unused2" 25 "Unused1" 23 "Step23" 22 "Step22" 21 "Step21" 20 "Step20" 19 "Step19" 18 "Step18" 17 "Step17" 16 "Step16" 15 "Step15" 14 "Step14" 13 "Step13" 12 "Step12" 11 "Step11" 10 "Step10" 9 "Step9" 8 "Step8" 7 "Step7" 6 "Step6" 5 "Step5" 4 "Step4" 3 "Step3" 2 "Step2" 1 "Step1" 24 "Max_Fan_Speed_Req" 0 "Fan_Cmd_Off" ;
VAL_ 1055 EcoCochInstNeg_B_Dsply 1 "True" 0 "False" ;
VAL_ 562 GearNtrl_D_Stat 3 "Faulty" 2 "NoDataExists" 1 "Yes" 0 "No" ;
VAL_ 517 FapLc_B_Err 1 "Yes" 0 "No" ;
